VERSION "dbc-export 1 2025.20.8"

NS_ :

BS_:

BU_: APP BMS CC CMP CMPD CP DAS DI DIF DIR EPBL EPBR EVSE FC GTW HCML HCMR HVP ICR PCS PM PMF PMR PTC SCCM SCM SCS SDCR TAS UMC VC VCFRONT VCLEFT VCRIGHT VCSEC

BO_ 932 PCS_alertMatrix: 8 PCS
 SG_ PCS_matrixIndex M : 0|4@1+ (1,0) [0|15] "" Vector__XXX
 SG_ PCS_a001_chgHwInputOc m0 : 4|1@1+ (1,0) [0|1] "" Vector__XXX
 SG_ PCS_a002_chgHwOutputOc m0 : 5|1@1+ (1,0) [0|1] "" Vector__XXX
 SG_ PCS_a003_chgHwInputOv m0 : 6|1@1+ (1,0) [0|1] "" Vector__XXX
 SG_ PCS_a004_chgHwIntBusOv m0 : 7|1@1+ (1,0) [0|1] "" Vector__XXX
 SG_ PCS_a005_chgOutputOv m0 : 8|1@1+ (1,0) [0|1] "" Vector__XXX
 SG_ PCS_a006_chgPrechargeFailedScr m0 : 9|1@1+ (1,0) [0|1] "" Vector__XXX
 SG_ PCS_a007_chgPhaseTempHot m0 : 10|1@1+ (1,0) [0|1] "" Vector__XXX
 SG_ PCS_a008_chgPhaseOverTemp m0 : 11|1@1+ (1,0) [0|1] "" Vector__XXX
 SG_ PCS_a009_chgPfcCurrentRegulation m0 : 12|1@1+ (1,0) [0|1] "" Vector__XXX
 SG_ PCS_a010_chgIntBusVRegulation m0 : 13|1@1+ (1,0) [0|1] "" Vector__XXX
 SG_ PCS_a011_chgLlcCurrentRegulation m0 : 14|1@1+ (1,0) [0|1] "" Vector__XXX
 SG_ PCS_a012_chgPfcIBandTracerFault m0 : 15|1@1+ (1,0) [0|1] "" Vector__XXX
 SG_ PCS_a013_chgPrechargeFailedBoost m0 : 16|1@1+ (1,0) [0|1] "" Vector__XXX
 SG_ PCS_a014_chgTempRationality m0 : 17|1@1+ (1,0) [0|1] "" Vector__XXX
 SG_ PCS_a015_chg12vUv m0 : 18|1@1+ (1,0) [0|1] "" Vector__XXX
 SG_ PCS_a016_chgAllPhasesFaulted m0 : 19|1@1+ (1,0) [0|1] "" Vector__XXX
 SG_ PCS_a017_chgWallPowerRemoval m0 : 20|1@1+ (1,0) [0|1] "" Vector__XXX
 SG_ PCS_a018_chgUnknownGridConfig m0 : 21|1@1+ (1,0) [0|1] "" Vector__XXX
 SG_ PCS_a019_acChargePowerLimited m0 : 22|1@1+ (1,0) [0|1] "" Vector__XXX
 SG_ PCS_a020_chgEnableLineMismatch m0 : 23|1@1+ (1,0) [0|1] "" Vector__XXX
 SG_ PCS_a021_hvpMia m0 : 24|1@1+ (1,0) [0|1] "" Vector__XXX
 SG_ PCS_a022_bmsMia m0 : 25|1@1+ (1,0) [0|1] "" Vector__XXX
 SG_ PCS_a023_cpMia m0 : 26|1@1+ (1,0) [0|1] "" Vector__XXX
 SG_ PCS_a024_vcfrontMia m0 : 27|1@1+ (1,0) [0|1] "" Vector__XXX
 SG_ PCS_a025_cpu2Malfunction m0 : 28|1@1+ (1,0) [0|1] "" Vector__XXX
 SG_ PCS_a026_watchdogAlarmed m0 : 29|1@1+ (1,0) [0|1] "" Vector__XXX
 SG_ PCS_a027_chgInsufficientCooling m0 : 30|1@1+ (1,0) [0|1] "" Vector__XXX
 SG_ PCS_a028_chgOutputUv m0 : 31|1@1+ (1,0) [0|1] "" Vector__XXX
 SG_ PCS_a029_chgPowerRationality m0 : 32|1@1+ (1,0) [0|1] "" Vector__XXX
 SG_ PCS_a030_canRationality m0 : 33|1@1+ (1,0) [0|1] "" Vector__XXX
 SG_ PCS_a031_uiMia m0 : 34|1@1+ (1,0) [0|1] "" Vector__XXX
 SG_ PCS_a032_excessiveGridTransients m0 : 35|1@1+ (1,0) [0|1] "" Vector__XXX
 SG_ PCS_a033_hvBusUv m0 : 36|1@1+ (1,0) [0|1] "" Vector__XXX
 SG_ PCS_a034_hvBusOv m0 : 37|1@1+ (1,0) [0|1] "" Vector__XXX
 SG_ PCS_a035_lvBusUv m0 : 38|1@1+ (1,0) [0|1] "" Vector__XXX
 SG_ PCS_a036_lvBusOv m0 : 39|1@1+ (1,0) [0|1] "" Vector__XXX
 SG_ PCS_a037_resonantTankOc m0 : 40|1@1+ (1,0) [0|1] "" Vector__XXX
 SG_ PCS_a038_claFaulted m0 : 41|1@1+ (1,0) [0|1] "" Vector__XXX
 SG_ PCS_a039_sdModuleClkFault m0 : 42|1@1+ (1,0) [0|1] "" Vector__XXX
 SG_ PCS_a040_dcdcMaxPowerReached m0 : 43|1@1+ (1,0) [0|1] "" Vector__XXX
 SG_ PCS_a041_dcdcOverTemp m0 : 44|1@1+ (1,0) [0|1] "" Vector__XXX
 SG_ PCS_a042_dcdcEnableLineMismatch m0 : 45|1@1+ (1,0) [0|1] "" Vector__XXX
 SG_ PCS_a043_hvBusPrechargeFailure m0 : 46|1@1+ (1,0) [0|1] "" Vector__XXX
 SG_ PCS_a044_12vSupportRegulation m0 : 47|1@1+ (1,0) [0|1] "" Vector__XXX
 SG_ PCS_a045_hvBusLowImpedance m0 : 48|1@1+ (1,0) [0|1] "" Vector__XXX
 SG_ PCS_a046_hvBusHighImpedence m0 : 49|1@1+ (1,0) [0|1] "" Vector__XXX
 SG_ PCS_a047_bootloaderCrcMismatch m0 : 50|1@1+ (1,0) [0|1] "" Vector__XXX
 SG_ PCS_a048_softwareAssertion m0 : 51|1@1+ (1,0) [0|1] "" Vector__XXX
 SG_ PCS_a049_dcdcTempRationality m0 : 52|1@1+ (1,0) [0|1] "" Vector__XXX
 SG_ PCS_a050_dcdc12VsupportFaulted m0 : 53|1@1+ (1,0) [0|1] "" Vector__XXX
 SG_ PCS_a051_chgIntBusUv m0 : 54|1@1+ (1,0) [0|1] "" Vector__XXX
 SG_ PCS_a052_acVoltageNotPresent m0 : 55|1@1+ (1,0) [0|1] "" Vector__XXX
 SG_ PCS_a053_chgInputVDropHigh m0 : 56|1@1+ (1,0) [0|1] "" Vector__XXX
 SG_ PCS_a054_chgInputVDropTooHigh m0 : 57|1@1+ (1,0) [0|1] "" Vector__XXX
 SG_ PCS_a055_chgLineImpedanceHigh m0 : 58|1@1+ (1,0) [0|1] "" Vector__XXX
 SG_ PCS_a056_chgLineImpedanceTooHigh m0 : 59|1@1+ (1,0) [0|1] "" Vector__XXX
 SG_ PCS_a057_chgInputOverFreq m0 : 60|1@1+ (1,0) [0|1] "" Vector__XXX
 SG_ PCS_a058_chgInputUnderFreq m0 : 61|1@1+ (1,0) [0|1] "" Vector__XXX
 SG_ PCS_a059_chgInputOvRms m0 : 62|1@1+ (1,0) [0|1] "" Vector__XXX
 SG_ PCS_a060_chgInputOvPeak m0 : 63|1@1+ (1,0) [0|1] "" Vector__XXX
 SG_ PCS_a061_chgVLineRationality m1 : 4|1@1+ (1,0) [0|1] "" Vector__XXX
 SG_ PCS_a062_chgILineRationality m1 : 5|1@1+ (1,0) [0|1] "" Vector__XXX
 SG_ PCS_a063_chgVOutRationality m1 : 6|1@1+ (1,0) [0|1] "" Vector__XXX
 SG_ PCS_a064_chgIOutRationality m1 : 7|1@1+ (1,0) [0|1] "" Vector__XXX
 SG_ PCS_a065_chgPllNotLocked m1 : 8|1@1+ (1,0) [0|1] "" Vector__XXX
 SG_ PCS_a066_dcdcHvRationality m1 : 9|1@1+ (1,0) [0|1] "" Vector__XXX
 SG_ PCS_a067_dcdcLvRationality m1 : 10|1@1+ (1,0) [0|1] "" Vector__XXX
 SG_ PCS_a068_dcdcTankvRationality m1 : 11|1@1+ (1,0) [0|1] "" Vector__XXX
 SG_ PCS_a069_chgPfcLineDidt m1 : 12|1@1+ (1,0) [0|1] "" Vector__XXX
 SG_ PCS_a070_chgPfcLineDvdt m1 : 13|1@1+ (1,0) [0|1] "" Vector__XXX
 SG_ PCS_a071_chgPfcILoopRationality m1 : 14|1@1+ (1,0) [0|1] "" Vector__XXX
 SG_ PCS_a072_cpu2ClaStopped m1 : 15|1@1+ (1,0) [0|1] "" Vector__XXX
 SG_ PCS_a073_unexpectedAcInputVoltag m1 : 16|1@1+ (1,0) [0|1] "" Vector__XXX
 SG_ PCS_a074_hvBusDischargeFailure m1 : 17|1@1+ (1,0) [0|1] "" Vector__XXX
 SG_ PCS_a075_hvBusDischargeTimeout m1 : 18|1@1+ (1,0) [0|1] "" Vector__XXX
 SG_ PCS_a076_dcdcEnDeassertedErr m1 : 19|1@1+ (1,0) [0|1] "" Vector__XXX
 SG_ PCS_a077_microGridWobbleDetected m1 : 20|1@1+ (1,0) [0|1] "" Vector__XXX
 SG_ PCS_a078_chgStopDcdcTooHot m1 : 21|1@1+ (1,0) [0|1] "" Vector__XXX
 SG_ PCS_a079_eepromOperationError m1 : 22|1@1+ (1,0) [0|1] "" Vector__XXX
 SG_ PCS_a080_damagedPhaseDetected m1 : 23|1@1+ (1,0) [0|1] "" Vector__XXX
 SG_ PCS_a081_dcdcPchgTimeout m1 : 24|1@1+ (1,0) [0|1] "" Vector__XXX
 SG_ PCS_a082_dcdcPchgUnsafeDiVoltage m1 : 25|1@1+ (1,0) [0|1] "" Vector__XXX
 SG_ PCS_a083_triggerOdin m1 : 26|1@1+ (1,0) [0|1] "" Vector__XXX
 SG_ PCS_a084_vDropFastInParasiticDio m1 : 27|1@1+ (1,0) [0|1] "" Vector__XXX
 SG_ PCS_a085_dcdcFetsNotSwitching m1 : 28|1@1+ (1,0) [0|1] "" Vector__XXX
 SG_ PCS_a086_dcdcInsufficientCooling m1 : 29|1@1+ (1,0) [0|1] "" Vector__XXX
 SG_ PCS_a087_nvramRecordStatusError m1 : 30|1@1+ (1,0) [0|1] "" Vector__XXX
 SG_ PCS_a088_gridFreqDroopDetected m1 : 31|1@1+ (1,0) [0|1] "" Vector__XXX
 SG_ PCS_a089_hvBusDischargeIrrationa m1 : 32|1@1+ (1,0) [0|1] "" Vector__XXX
 SG_ PCS_a090_expectedAcVoltageSource m1 : 33|1@1+ (1,0) [0|1] "" Vector__XXX
 SG_ PCS_a091_chgIntBusRationality m1 : 34|1@1+ (1,0) [0|1] "" Vector__XXX
 SG_ PCS_a092_chgPowerLimitedByBusRip m1 : 35|1@1+ (1,0) [0|1] "" Vector__XXX
 SG_ PCS_a093_powerRailRationality m1 : 36|1@1+ (1,0) [0|1] "" Vector__XXX
 SG_ PCS_a094_pcsDcdcNeedService m1 : 37|1@1+ (1,0) [0|1] "" Vector__XXX
 SG_ PCS_a095_dcdcSensorlessModeActiv m1 : 38|1@1+ (1,0) [0|1] "" Vector__XXX
 SG_ PCS_a096_microGridOverLoaded m1 : 39|1@1+ (1,0) [0|1] "" Vector__XXX
 SG_ PCS_a097_rebootPhaseDetected m1 : 40|1@1+ (1,0) [0|1] "" Vector__XXX
 SG_ PCS_a098_gridFreqDroopDetectedSi m1 : 41|1@1+ (1,0) [0|1] "" Vector__XXX
 SG_ PCS_a099_microGridOverLoadedSile m1 : 42|1@1+ (1,0) [0|1] "" Vector__XXX
 SG_ PCS_a100_suspectedViperChipIssue m1 : 43|1@1+ (1,0) [0|1] "" Vector__XXX
 SG_ PCS_a101_phMachineModelIrrationa m1 : 44|1@1+ (1,0) [0|1] "" Vector__XXX
 SG_ PCS_a102_resetWithDCDCCmdAsserte m1 : 45|1@1+ (1,0) [0|1] "" Vector__XXX
 SG_ PCS_a103_pchgWithLowLvDetected m1 : 46|1@1+ (1,0) [0|1] "" Vector__XXX
 SG_ PCS_a104_ambientTempRationality m1 : 47|1@1+ (1,0) [0|1] "" Vector__XXX
 SG_ PCS_a105_redundantVoltageSourceI m1 : 48|1@1+ (1,0) [0|1] "" Vector__XXX
 SG_ PCS_a106_clockSourceNotFromExter m1 : 49|1@1+ (1,0) [0|1] "" Vector__XXX
 SG_ PCS_a107_vcPcsDCDCInterfaceMia m1 : 50|1@1+ (1,0) [0|1] "" Vector__XXX
 SG_ PCS_a108_misconfigurationDetecte m1 : 51|1@1+ (1,0) [0|1] "" Vector__XXX
 SG_ PCS_a109_deltaChargingL2L3Swappe m1 : 52|1@1+ (1,0) [0|1] "" Vector__XXX

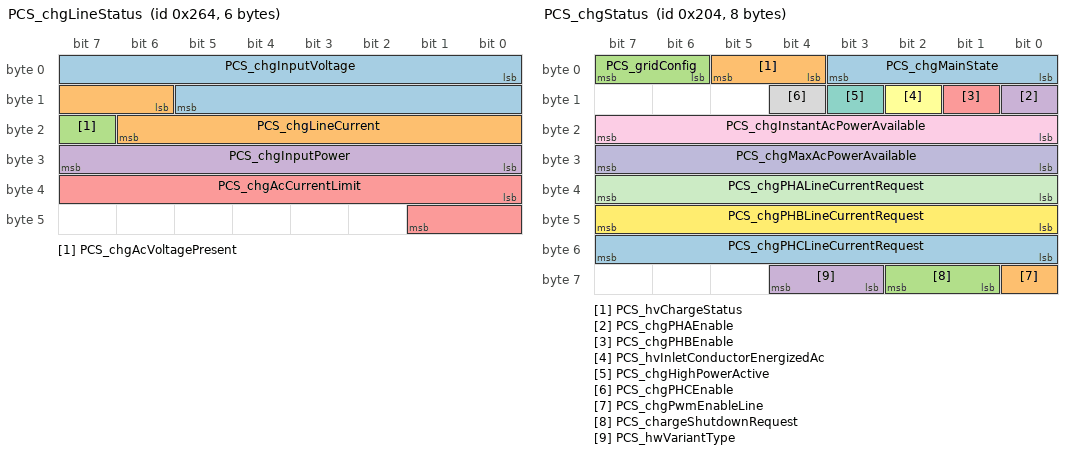
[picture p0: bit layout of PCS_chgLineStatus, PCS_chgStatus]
BO_ 612 PCS_chgLineStatus: 6 PCS
 SG_ PCS_chgInputVoltage : 0|14@1+ (0.033,0) [0|540.639] "V" Vector__XXX
 SG_ PCS_chgLineCurrent : 14|9@1+ (0.1,0) [0|50] "A" Vector__XXX
 SG_ PCS_chgAcVoltagePresent : 23|1@1+ (1,0) [0|1] "" Vector__XXX
 SG_ PCS_chgInputPower : 24|8@1+ (0.1,0) [0|20] "kW" Vector__XXX
 SG_ PCS_chgAcCurrentLimit : 32|10@1+ (0.1,0) [0|102.3] "A" Vector__XXX

BO_ 516 PCS_chgStatus: 8 PCS
 SG_ PCS_chgMainState : 0|4@1+ (1,0) [0|15] "" Vector__XXX
 SG_ PCS_hvChargeStatus : 4|2@1+ (1,0) [0|3] "" Vector__XXX
 SG_ PCS_gridConfig : 6|2@1+ (1,0) [1|3] "" Vector__XXX
 SG_ PCS_chgPHAEnable : 8|1@1+ (1,0) [0|1] "" Vector__XXX
 SG_ PCS_chgPHBEnable : 9|1@1+ (1,0) [0|1] "" Vector__XXX
 SG_ PCS_hvInletConductorEnergizedAc : 10|1@1+ (1,0) [0|1] "" Vector__XXX
 SG_ PCS_chgHighPowerActive : 11|1@1+ (1,0) [0|1] "" Vector__XXX
 SG_ PCS_chgPHCEnable : 12|1@1+ (1,0) [0|1] "" Vector__XXX
 SG_ PCS_chgInstantAcPowerAvailable : 16|8@1+ (0.1,0) [0|20] "kW" Vector__XXX
 SG_ PCS_chgMaxAcPowerAvailable : 24|8@1+ (0.1,0) [0|20] "kW" Vector__XXX
 SG_ PCS_chgPHALineCurrentRequest : 32|8@1+ (0.1,0) [0|20] "A" Vector__XXX
 SG_ PCS_chgPHBLineCurrentRequest : 40|8@1+ (0.1,0) [0|20] "A" Vector__XXX
 SG_ PCS_chgPHCLineCurrentRequest : 48|8@1+ (0.1,0) [0|20] "A" Vector__XXX
 SG_ PCS_chgPwmEnableLine : 56|1@1+ (1,0) [0|1] "" Vector__XXX
 SG_ PCS_chargeShutdownRequest : 57|2@1+ (1,0) [0|3] "" Vector__XXX
 SG_ PCS_hwVariantType : 59|2@1+ (1,0) [0|2] "" Vector__XXX

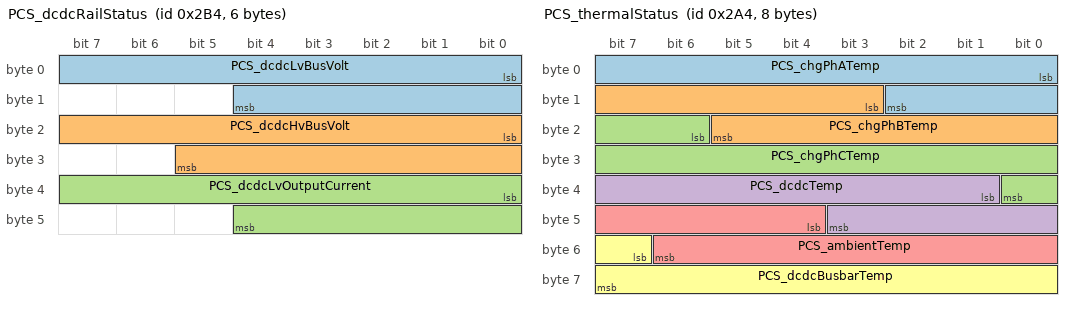
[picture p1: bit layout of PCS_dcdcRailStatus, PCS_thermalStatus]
BO_ 692 PCS_dcdcRailStatus: 6 PCS
 SG_ PCS_dcdcLvBusVolt : 0|13@1+ (0.01,0) [0|80] "V" Vector__XXX
 SG_ PCS_dcdcHvBusVolt : 16|14@1+ (0.1,0) [0|1600] "V" Vector__XXX
 SG_ PCS_dcdcLvOutputCurrent : 32|13@1- (0.1,0) [-400|400] "A" Vector__XXX

BO_ 548 PCS_dcdcStatus: 8 PCS
 SG_ PCS_dcdcPrechargeStatus : 0|2@1+ (1,0) [0|3] "" Vector__XXX
 SG_ PCS_dcdcLvSupportStatus : 2|2@1+ (1,0) [0|3] "" Vector__XXX
 SG_ PCS_dcdcHvBusDischargeStatus : 4|2@1+ (1,0) [0|3] "" Vector__XXX
 SG_ PCS_coldSleepAllowed : 8|1@1+ (1,0) [0|1] "" Vector__XXX
 SG_ PCS_dcdcPchgHVBusLowRDetected : 9|1@1+ (1,0) [0|1] "" Vector__XXX
 SG_ PCS_dcdcSubState : 10|5@1+ (1,0) [0|31] "" Vector__XXX
 SG_ PCS_dcdcFaulted : 15|1@1+ (1,0) [0|1] "" Vector__XXX
 SG_ PCS_okToBePowerCycled : 27|1@1+ (1,0) [0|1] "" Vector__XXX
 SG_ PCS_dcdcOutputIsLimited : 28|1@1+ (1,0) [0|1] "" Vector__XXX
 SG_ PCS_dcdcMaxOutputCurrentAllowed : 29|12@1+ (0.1,0) [0|400] "A" Vector__XXX
 SG_ PCS_dcdcPrechargeRtyCnt : 41|3@1+ (1,0) [0|7] "" Vector__XXX
 SG_ PCS_dcdcLvSupportRtyCnt : 44|4@1+ (1,0) [0|15] "" Vector__XXX
 SG_ PCS_dcdcDischargeRtyCnt : 48|4@1+ (1,0) [0|15] "" Vector__XXX
 SG_ PCS_dcdcPwmEnableLine : 52|1@1+ (1,0) [0|1] "" Vector__XXX
 SG_ PCS_dcdcSupportingFixedLvTarget : 53|1@1+ (1,0) [0|1] "" Vector__XXX
 SG_ PCS_ecuLogUploadRequest : 54|2@1+ (1,0) [0|3] "" Vector__XXX
 SG_ PCS_dcdcPrechargeRestartCnt : 56|3@1+ (1,0) [0|7] "" Vector__XXX
 SG_ PCS_dcdcInitialPrechargeSubState : 59|5@1+ (1,0) [0|31] "" Vector__XXX

BO_ 964 PCS_info: 8 PCS
 SG_ PCS_infoIndex M : 0|8@1+ (1,0) [0|255] "" Vector__XXX
 SG_ PCS_buildType m10 : 8|8@1+ (1,0) [0|255] "" Vector__XXX
 SG_ PCS_buildConfigId m10 : 16|16@1+ (1,0) [0|65535] "" Vector__XXX
 SG_ PCS_hardwareId m10 : 32|16@1+ (1,0) [0|65535] "" Vector__XXX
 SG_ PCS_componentId m10 : 48|16@1+ (1,0) [0|65535] "" Vector__XXX
 SG_ PCS_pcbaId m11 : 16|8@1+ (1,0) [0|255] "" Vector__XXX
 SG_ PCS_assemblyId m11 : 24|8@1+ (1,0) [0|255] "" Vector__XXX
 SG_ PCS_usageId m11 : 32|16@1+ (1,0) [0|65535] "" Vector__XXX
 SG_ PCS_subUsageId m11 : 48|16@1+ (1,0) [0|65535] "" Vector__XXX
 SG_ PCS_platformType m13 : 8|8@1+ (1,0) [0|255] "" Vector__XXX
 SG_ PCS_appCrc m13 : 32|32@1+ (1,0) [0|4294967295] "" Vector__XXX
 SG_ PCS_cpu2AppCrc m16 : 32|32@1+ (1,0) [0|4294967295] "" Vector__XXX
 SG_ PCS_appGitHash m17 : 8|56@1+ (1,0) [0|7.20575940379e+16] "" Vector__XXX
 SG_ PCS_bootGitHash m18 : 8|56@1+ (1,0) [0|7.20575940379e+16] "" Vector__XXX
 SG_ PCS_bootUdsProtoVersion m20 : 8|8@1+ (1,0) [0|255] "" Vector__XXX
 SG_ PCS_bootCrc m20 : 32|32@1+ (1,0) [0|4294967295] "" Vector__XXX

BO_ 708 PCS_logging: 8 PCS
 SG_ PCS_logMessageSelect M : 0|5@1+ (1,0) [0|31] "" Vector__XXX
 SG_ PCS_chgPhAInputIrms m0 : 5|9@1+ (0.1,0) [0|51.1] "A" Vector__XXX
 SG_ PCS_chgPhAIntBusV m0 : 14|9@1+ (1,0) [0|511] "V" Vector__XXX
 SG_ PCS_chgPhAIntBusVTarget m0 : 23|9@1+ (1,0) [0|511] "V" Vector__XXX
 SG_ PCS_chgPhAOutputI m0 : 32|8@1+ (0.1,0) [0|25.5] "A" Vector__XXX
 SG_ PCS_chgPhAInputCurrentLimitReaso m0 : 40|3@1+ (1,0) [0|7] "" Vector__XXX
 SG_ PCS_chgPhBInputIrms m1 : 5|9@1+ (0.1,0) [0|51.1] "A" Vector__XXX
 SG_ PCS_chgPhBIntBusV m1 : 14|9@1+ (1,0) [0|511] "V" Vector__XXX
 SG_ PCS_chgPhBIntBusVTarget m1 : 23|9@1+ (1,0) [0|511] "V" Vector__XXX
 SG_ PCS_chgPhBOutputI m1 : 32|8@1+ (0.1,0) [0|25.5] "A" Vector__XXX
 SG_ PCS_chgPhBInputCurrentLimitReaso m1 : 40|3@1+ (1,0) [0|7] "" Vector__XXX
 SG_ PCS_chgPhCInputIrms m2 : 5|9@1+ (0.1,0) [0|51.1] "A" Vector__XXX
 SG_ PCS_chgPhCIntBusV m2 : 14|9@1+ (1,0) [0|511] "V" Vector__XXX
 SG_ PCS_chgPhCIntBusVTarget m2 : 23|9@1+ (1,0) [0|511] "V" Vector__XXX
 SG_ PCS_chgPhCOutputI m2 : 32|8@1+ (0.1,0) [0|25.5] "A" Vector__XXX
 SG_ PCS_chgPhCInputCurrentLimitReaso m2 : 40|3@1+ (1,0) [0|7] "" Vector__XXX
 SG_ PCS_chgInputL1NVrms m3 : 5|12@1+ (0.2,0) [0|819] "V" Vector__XXX
 SG_ PCS_chgInputL2NVrms m3 : 17|12@1+ (0.2,0) [0|819] "V" Vector__XXX
 SG_ PCS_chgInputL3NVrms m3 : 29|12@1+ (0.2,0) [0|819] "V" Vector__XXX
 SG_ PCS_chgInputL1L2Vrms m3 : 41|12@1+ (0.2,0) [0|819] "V" Vector__XXX
 SG_ PCS_chgInputNGVrms m3 : 53|9@1+ (1,0) [0|511] "V" Vector__XXX
 SG_ PCS_chgInputFrequencyL1N m4 : 5|12@1+ (0.01,40) [40|80.95] "Hz" Vector__XXX
 SG_ PCS_chgInputFrequencyL2N m4 : 17|12@1+ (0.01,40) [40|80.95] "Hz" Vector__XXX
 SG_ PCS_chgInputFrequencyL3N m4 : 29|12@1+ (0.01,40) [40|80.95] "Hz" Vector__XXX
 SG_ PCS_chgInternalPhaseConfig m4 : 41|4@1+ (1,0) [1|15] "" Vector__XXX
 SG_ PCS_chgPhasesPriority m4 : 45|6@1+ (1,0) [0|63] "" Vector__XXX
 SG_ PCS_chgOutputV m4 : 51|12@1+ (0.146484375,0) [0|599.853515625] "V" Vector__XXX
 SG_ PCS_chgPhAState m5 : 5|4@1+ (1,0) [0|15] "" Vector__XXX
 SG_ PCS_chgPhBState m5 : 9|4@1+ (1,0) [0|15] "" Vector__XXX
 SG_ PCS_chgPhCState m5 : 13|4@1+ (1,0) [0|15] "" Vector__XXX
 SG_ PCS_chgPhALastShutdownReason m5 : 17|5@1+ (1,0) [0|31] "" Vector__XXX
 SG_ PCS_chgPhBLastShutdownReason m5 : 22|5@1+ (1,0) [0|31] "" Vector__XXX
 SG_ PCS_chgPhCLastShutdownReason m5 : 27|5@1+ (1,0) [0|31] "" Vector__XXX
 SG_ PCS_chgPhARetryCount m5 : 32|3@1+ (1,0) [0|7] "" Vector__XXX
 SG_ PCS_chgPhBRetryCount m5 : 35|3@1+ (1,0) [0|7] "" Vector__XXX
 SG_ PCS_chgPhCRetryCount m5 : 38|3@1+ (1,0) [0|7] "" Vector__XXX
 SG_ PCS_chgRetryCount m5 : 41|3@1+ (1,0) [0|7] "" Vector__XXX
 SG_ PCS_chgPhManCurrentToDist m5 : 44|10@1+ (0.1,0) [0|100] "A" Vector__XXX
 SG_ PCS_chgL1NPllLocked m5 : 54|1@1+ (1,0) [0|1] "" Vector__XXX
 SG_ PCS_chgL2NPllLocked m5 : 55|1@1+ (1,0) [0|1] "" Vector__XXX
 SG_ PCS_chgL3NPllLocked m5 : 56|1@1+ (1,0) [0|1] "" Vector__XXX
 SG_ PCS_chgL1L2PllLocked m5 : 57|1@1+ (1,0) [0|1] "" Vector__XXX
 SG_ PCS_chgNgPllLocked m5 : 58|1@1+ (1,0) [0|1] "" Vector__XXX
 SG_ PCS_chgPhManOptimalPhsToUse m5 : 59|2@1+ (1,0) [0|3] "" Vector__XXX
 SG_ PCS_chg5VL1Enable m5 : 61|1@1+ (1,0) [0|1] "" Vector__XXX
 SG_ PCS_dcdcMaxLvOutputCurrent m6 : 8|12@1+ (0.1,0) [0|400] "A" Vector__XXX
 SG_ PCS_dcdcCurrentLimit m6 : 20|12@1+ (0.1,0) [0|400] "A" Vector__XXX
 SG_ PCS_dcdcLvOutputCurrentTempLimit m6 : 32|12@1+ (0.1,0) [0|400] "A" Vector__XXX
 SG_ PCS_dcdcLvOutputCurrentFiltered m6 : 44|12@1+ (0.1,0) [0|400] "A" Vector__XXX
 SG_ PCS_dcdcUnifiedCommand m7 : 5|10@1+ (0.001,0) [0|1] "1" Vector__XXX
 SG_ PCS_dcdcCLAControllerOutput m7 : 16|10@1+ (0.001,0) [0|1] "1" Vector__XXX
 SG_ PCS_dcdcTankVoltage m7 : 26|11@1- (1,0) [-1024|1023] "V" Vector__XXX
 SG_ PCS_dcdcTankVoltageTarget m7 : 37|10@1+ (1,0) [0|1023] "V" Vector__XXX
 SG_ PCS_dcdcClaCurrentFreq m7 : 48|12@1+ (0.09765625,0) [0|399.9] "kHz" Vector__XXX
 SG_ PCS_dcdcTCommMeasured m8 : 5|16@1- (0.001953125,0) [-64|63.998] "us" Vector__XXX
 SG_ PCS_dcdcShortTimeUs m8 : 21|16@1+ (0.00048828125,0) [0|31.9995] "us" Vector__XXX
 SG_ PCS_dcdcHalfPeriodUs m8 : 37|16@1+ (0.00048828125,0) [0|31.9995] "us" Vector__XXX
 SG_ PCS_dcdcLvBusVoltTargetWithOffse m8 : 53|11@1+ (0.01,0) [0|20] "V" Vector__XXX
 SG_ PCS_cpu2BootState m9 : 5|2@1+ (1,0) [0|3] "" Vector__XXX
 SG_ PCS_acChargeSelfTestState m9 : 7|1@1+ (1,0) [0|1] "" Vector__XXX
 SG_ PCS_1V5Min10s m9 : 8|11@1+ (0.001,0) [0|2.047] "V" Vector__XXX
 SG_ PCS_1V5Max10s m9 : 19|11@1+ (0.001,0) [0|2.047] "V" Vector__XXX
 SG_ PCS_1V2Min10s m9 : 32|11@1+ (0.001,0) [0|2.047] "V" Vector__XXX
 SG_ PCS_1V2Max10s m9 : 43|11@1+ (0.001,0) [0|2.047] "V" Vector__XXX
 SG_ PCS_5VNMax10s m9 : 54|10@1+ (0.01,0) [0|10.23] "V" Vector__XXX
 SG_ PCS_chgPhAIntBusVMin10s m10 : 5|9@1+ (1,0) [0|511] "V" Vector__XXX
 SG_ PCS_chgPhAIntBusVMax10s m10 : 14|9@1+ (1,0) [0|511] "V" Vector__XXX
 SG_ PCS_chgPhAPchgVoltDeltaMax10s m10 : 23|8@1+ (0.5,0) [0|127.5] "V" Vector__XXX
 SG_ PCS_chgPhALifetimekWh m10 : 31|24@1+ (0.01,0) [0|167772.15] "kWh" Vector__XXX
 SG_ PCS_chgPhATransientRetryCount m10 : 55|9@1+ (0.1,0) [0|51.1] "-" Vector__XXX
 SG_ PCS_chgPhBIntBusVMin10s m11 : 5|9@1+ (1,0) [0|511] "V" Vector__XXX
 SG_ PCS_chgPhBIntBusVMax10s m11 : 14|9@1+ (1,0) [0|511] "V" Vector__XXX
 SG_ PCS_chgPhBPchgVoltDeltaMax10s m11 : 23|8@1+ (0.5,0) [0|127.5] "V" Vector__XXX
 SG_ PCS_chgPhBLifetimekWh m11 : 31|24@1+ (0.01,0) [0|167772.15] "kWh" Vector__XXX
 SG_ PCS_chgPhBTransientRetryCount m11 : 55|9@1+ (0.1,0) [0|51.1] "-" Vector__XXX
 SG_ PCS_chgPhCIntBusVMin10s m12 : 5|9@1+ (1,0) [0|511] "V" Vector__XXX
 SG_ PCS_chgPhCIntBusVMax10s m12 : 14|9@1+ (1,0) [0|511] "V" Vector__XXX
 SG_ PCS_chgPhCPchgVoltDeltaMax10s m12 : 23|8@1+ (0.5,0) [0|127.5] "V" Vector__XXX
 SG_ PCS_chgPhCLifetimekWh m12 : 31|24@1+ (0.01,0) [0|167772.15] "kWh" Vector__XXX
 SG_ PCS_chgPhCTransientRetryCount m12 : 55|9@1+ (0.1,0) [0|51.1] "-" Vector__XXX
 SG_ PCS_chgPhANoFlowBucket m20 : 5|9@1+ (0.01,0) [0|5.11] "-" Vector__XXX
 SG_ PCS_chgPhBNoFlowBucket m20 : 14|9@1+ (0.01,0) [0|5.11] "-" Vector__XXX
 SG_ PCS_chgPhCNoFlowBucket m20 : 23|9@1+ (0.01,0) [0|5.11] "-" Vector__XXX
 SG_ PCS_chgCurrentSensorOutOfBandUs m20 : 32|10@1+ (0.01,0) [0|10.23] "us" Vector__XXX
 SG_ PCS_chgAcpwHeartbeatState m20 : 42|3@1+ (1,0) [0|7] "" Vector__XXX
 SG_ PCS_chgKwhLostByFreqDroop m20 : 48|8@1+ (0.1,0) [0|25.5] "kWh" Vector__XXX
 SG_ PCS_chgReqKwhLostByFreqDroop m20 : 56|8@1+ (0.1,0) [0|25.5] "kWh" Vector__XXX
 SG_ PCS_dcdcLvSupportLifetimekWh m22 : 8|24@1+ (0.01,0) [0|167772.15] "kWh" Vector__XXX
 SG_ PCS_chgPwmEnableLineErrorCount m22 : 32|10@1+ (1,0) [0|1023] "" Vector__XXX
 SG_ PCS_dcdcPwmEnableLineErrorCount m22 : 42|10@1+ (1,0) [0|1023] "" Vector__XXX
 SG_ PCS_numAlertsSet m22 : 56|7@1+ (1,0) [0|127] "" Vector__XXX
 SG_ PCS_dcdcPchgStartLvBusVolt m24 : 5|10@1+ (0.0390625,0) [0|39.9609375] "V" Vector__XXX
 SG_ PCS_dcdcPchgStartHvBusVolt m24 : 16|12@1+ (0.146484375,0) [0|599.853515625] "V" Vector__XXX
 SG_ PCS_processorDieIdLot m26 : 8|24@1+ (1,0) [0|16777215] "" Vector__XXX
 SG_ PCS_processorDieIdWafer m26 : 32|8@1+ (1,0) [0|255] "" Vector__XXX
 SG_ PCS_processorDieIdX m26 : 40|12@1+ (1,0) [0|4095] "" Vector__XXX
 SG_ PCS_processorDieIdY m26 : 52|12@1+ (1,0) [0|4095] "" Vector__XXX

BO_ 676 PCS_thermalStatus: 8 PCS
 SG_ PCS_chgPhATemp : 0|11@1- (0.1,40) [-62.4|142.3] "C" Vector__XXX
 SG_ PCS_chgPhBTemp : 11|11@1- (0.1,40) [-62.4|142.3] "C" Vector__XXX
 SG_ PCS_chgPhCTemp : 22|11@1- (0.1,40) [-62.4|142.3] "C" Vector__XXX
 SG_ PCS_dcdcTemp : 33|11@1- (0.1,40) [-62.4|142.3] "C" Vector__XXX
 SG_ PCS_ambientTemp : 44|11@1- (0.1,40) [-62.4|142.3] "C" Vector__XXX
 SG_ PCS_dcdcBusbarTemp : 55|9@1+ (0.2935421,0) [0|149.706471] "C" Vector__XXX

BO_ 1317 PMF_alertLog: 8 PMF
 SG_ PMF_alertID M : 0|7@1+ (1,0) [0|127] "" Vector__XXX
 SG_ PMF_alertState : 15|1@1+ (1,0) [0|1] "" Vector__XXX
 SG_ PMF_a001_w0 m1 : 16|16@1+ (1,0) [0|65535] "" Vector__XXX
 SG_ PMF_a001_w1 m1 : 32|16@1+ (1,0) [0|65535] "" Vector__XXX
 SG_ PMF_a001_w2 m1 : 48|16@1+ (1,0) [0|65535] "" Vector__XXX
 SG_ PMF_a002_torqueAverage m2 : 16|1@1+ (1,0) [0|1] "" Vector__XXX
 SG_ PMF_a002_torqueWindow m2 : 17|1@1+ (1,0) [0|1] "" Vector__XXX
 SG_ PMF_a002_torqueMeasured m2 : 18|13@1- (2,0) [-8192|8190] "Nm" Vector__XXX
 SG_ PMF_a002_torqueAccelAverage m2 : 32|13@1- (2,0) [-8192|8190] "Nm" Vector__XXX
 SG_ PMF_a002_torqueAccelWindow m2 : 48|13@1- (2,0) [-8192|8190] "Nm" Vector__XXX
 SG_ PMF_a003_reverseGear m3 : 16|1@1+ (1,0) [0|1] "" Vector__XXX
 SG_ PMF_a003_pedalPos m3 : 24|8@1+ (0.4,0) [0|102] "%" Vector__XXX
 SG_ PMF_a003_zeroPointPedal m3 : 32|8@1+ (0.4,0) [0|102] "%" Vector__XXX
 SG_ PMF_a004_torqueAverage m4 : 16|1@1+ (1,0) [0|1] "" Vector__XXX
 SG_ PMF_a004_torqueWindow m4 : 17|1@1+ (1,0) [0|1] "" Vector__XXX
 SG_ PMF_a004_torqueMeasured m4 : 18|13@1- (2,0) [-8192|8190] "Nm" Vector__XXX
 SG_ PMF_a004_torqueDecelAverage m4 : 32|13@1- (2,0) [-8192|8190] "Nm" Vector__XXX
 SG_ PMF_a004_torqueDecelWindow m4 : 48|13@1- (2,0) [-8192|8190] "Nm" Vector__XXX
 SG_ PMF_a005_torqueReason m5 : 16|2@1+ (1,0) [0|3] "" Vector__XXX
 SG_ PMF_a005_torqueMeasured m5 : 18|13@1- (2,0) [-8192|8190] "Nm" Vector__XXX
 SG_ PMF_a005_iDQmagnitude m5 : 32|16@1- (0.0939,0) [-3076.9152|3076.8213] "A" Vector__XXX
 SG_ PMF_a006_torqueActual m6 : 16|13@1- (2,0) [-8192|8190] "Nm" Vector__XXX
 SG_ PMF_a006_motorRPM m6 : 32|16@1- (1,0) [-32768|32767] "RPM" Vector__XXX
 SG_ PMF_a006_torqueMeasured m6 : 48|13@1- (2,0) [-8192|8190] "Nm" Vector__XXX
 SG_ PMF_a010_messageId m10 : 16|16@1+ (1,0) [0|65535] "" Vector__XXX
 SG_ PMF_a010_DI_status m10 : 32|1@1+ (1,0) [0|1] "" Vector__XXX
 SG_ PMF_a010_DI_torque m10 : 33|1@1+ (1,0) [0|1] "" Vector__XXX
 SG_ PMF_a010_DI_slaveCommand m10 : 34|1@1+ (1,0) [0|1] "" Vector__XXX
 SG_ PMF_a010_DI_locStatus m10 : 35|1@1+ (1,0) [0|1] "" Vector__XXX
 SG_ PMF_a010_DI_speed m10 : 36|1@1+ (1,0) [0|1] "" Vector__XXX
 SG_ PMF_a010_DI_systemStatus m10 : 37|1@1+ (1,0) [0|1] "" Vector__XXX
 SG_ PMF_a010_DI_chassisControl m10 : 38|1@1+ (1,0) [0|1] "" Vector__XXX
 SG_ PMF_a010_DI_chassisControl2 m10 : 39|1@1+ (1,0) [0|1] "" Vector__XXX
 SG_ PMF_a010_vdcLeft m10 : 40|1@1+ (1,0) [0|1] "" Vector__XXX
 SG_ PMF_a010_vdcRight m10 : 41|1@1+ (1,0) [0|1] "" Vector__XXX
 SG_ PMF_a010_DI_vehicleEstimates m10 : 42|1@1+ (1,0) [0|1] "" Vector__XXX
 SG_ PMF_a010_DI_brakeCommand m10 : 43|1@1+ (1,0) [0|1] "" Vector__XXX
 SG_ PMF_a010_DI_difCommand m10 : 44|1@1+ (1,0) [0|1] "" Vector__XXX
 SG_ PMF_a010_DI_dirCommand m10 : 45|1@1+ (1,0) [0|1] "" Vector__XXX
 SG_ PMF_a010_DI_dirVehicle m10 : 46|1@1+ (1,0) [0|1] "" Vector__XXX
 SG_ PMF_a010_DI_locStatus2 m10 : 47|1@1+ (1,0) [0|1] "" Vector__XXX
 SG_ PMF_a011_Ia m11 : 16|16@1- (0.0939,0) [-3076.9152|3076.8213] "A" Vector__XXX
 SG_ PMF_a011_Ib m11 : 32|16@1- (0.0939,0) [-3076.9152|3076.8213] "A" Vector__XXX
 SG_ PMF_a011_currentVref m11 : 48|11@1+ (0.005,0) [0|10.235] "V" Vector__XXX
 SG_ PMF_a011_badPhaseAsample m11 : 59|1@1+ (1,0) [0|1] "" Vector__XXX
 SG_ PMF_a011_badPhaseBsample m11 : 60|1@1+ (1,0) [0|1] "" Vector__XXX
 SG_ PMF_a011_sampleFreeze m11 : 61|1@1+ (1,0) [0|1] "" Vector__XXX
 SG_ PMF_a012_canID m12 : 16|12@1+ (1,0) [0|4095] "" Vector__XXX
 SG_ PMF_a012_errorType m12 : 28|3@1+ (1,0) [0|7] "" Vector__XXX
 SG_ PMF_a012_badValue1 m12 : 32|16@1+ (1,0) [0|65535] "" Vector__XXX
 SG_ PMF_a012_badValue2 m12 : 48|16@1+ (1,0) [0|65535] "" Vector__XXX
 SG_ PMF_a013_mailboxID m13 : 16|16@1+ (1,0) [0|65535] "" Vector__XXX
 SG_ PMF_a013_canID m13 : 32|16@1+ (1,0) [0|65535] "" Vector__XXX
 SG_ PMF_a013_errorType m13 : 48|3@1+ (1,0) [0|7] "" Vector__XXX
 SG_ PMF_a017_EPBL_status m17 : 16|1@1+ (1,0) [0|1] "" Vector__XXX
 SG_ PMF_a017_EPBR_status m17 : 17|1@1+ (1,0) [0|1] "" Vector__XXX
 SG_ PMF_a018_w0 m18 : 16|16@1+ (1,0) [0|65535] "" Vector__XXX
 SG_ PMF_a018_w1 m18 : 32|16@1+ (1,0) [0|65535] "" Vector__XXX
 SG_ PMF_a018_w2 m18 : 48|16@1+ (1,0) [0|65535] "" Vector__XXX
 SG_ PMF_a019_statorTemp1 m19 : 16|16@1- (0.1,0) [-3276.8|3276.7] "DegC" Vector__XXX
 SG_ PMF_a019_statorTslope1 m19 : 32|16@1- (0.1,0) [-3276.8|3276.7] "DegC/s" Vector__XXX
 SG_ PMF_a025_sccReset m25 : 16|1@1+ (1,0) [0|1] "" Vector__XXX
 SG_ PMF_a025_hibernate m25 : 17|1@1+ (1,0) [0|1] "" Vector__XXX
 SG_ PMF_a025_hwBist m25 : 18|1@1+ (1,0) [0|1] "" Vector__XXX
 SG_ PMF_a025_nmiWatchdog m25 : 19|1@1+ (1,0) [0|1] "" Vector__XXX
 SG_ PMF_a025_watchdog m25 : 20|1@1+ (1,0) [0|1] "" Vector__XXX
 SG_ PMF_a025_clockFailNmi m25 : 21|1@1+ (1,0) [0|1] "" Vector__XXX
 SG_ PMF_a025_ramUncErrorNmi m25 : 22|1@1+ (1,0) [0|1] "" Vector__XXX
 SG_ PMF_a025_flashUncErrorNmi m25 : 23|1@1+ (1,0) [0|1] "" Vector__XXX
 SG_ PMF_a025_cpu1signMismatchNmi m25 : 24|1@1+ (1,0) [0|1] "" Vector__XXX
 SG_ PMF_a025_cpu2signMismatchNmi m25 : 25|1@1+ (1,0) [0|1] "" Vector__XXX
 SG_ PMF_a025_pieVectErrorNmi m25 : 26|1@1+ (1,0) [0|1] "" Vector__XXX
 SG_ PMF_a025_sysDbgNmi m25 : 27|1@1+ (1,0) [0|1] "" Vector__XXX
 SG_ PMF_a025_rlNmi m25 : 28|1@1+ (1,0) [0|1] "" Vector__XXX
 SG_ PMF_a025_ovfNmi m25 : 29|1@1+ (1,0) [0|1] "" Vector__XXX
 SG_ PMF_a025_possibleSafetyICReset m25 : 30|1@1+ (1,0) [0|1] "" Vector__XXX
 SG_ PMF_a025_powerOnReset m25 : 31|1@1+ (1,0) [0|1] "" Vector__XXX
 SG_ PMF_a025_watchdogTimer0 m25 : 32|1@1+ (1,0) [0|1] "" Vector__XXX
 SG_ PMF_a025_watchdogTimer1 m25 : 33|1@1+ (1,0) [0|1] "" Vector__XXX
 SG_ PMF_a025_watchdogTimer2 m25 : 34|1@1+ (1,0) [0|1] "" Vector__XXX
 SG_ PMF_a025_watchdogTimer3 m25 : 35|1@1+ (1,0) [0|1] "" Vector__XXX
 SG_ PMF_a025_warmResetReq m25 : 36|1@1+ (1,0) [0|1] "" Vector__XXX
 SG_ PMF_a025_externalPadReset m25 : 37|1@1+ (1,0) [0|1] "" Vector__XXX
 SG_ PMF_a025_hwSecModuleWatchdogTime m25 : 38|1@1+ (1,0) [0|1] "" Vector__XXX
 SG_ PMF_a025_debugReset m25 : 39|1@1+ (1,0) [0|1] "" Vector__XXX
 SG_ PMF_a025_tempSense0 m25 : 40|1@1+ (1,0) [0|1] "" Vector__XXX
 SG_ PMF_a025_tempSense1 m25 : 41|1@1+ (1,0) [0|1] "" Vector__XXX
 SG_ PMF_a026_reason m26 : 16|1@1+ (1,0) [0|1] "" Vector__XXX
 SG_ PMF_a026_isrCount20kHz m26 : 17|5@1+ (1,0) [0|31] "" Vector__XXX
 SG_ PMF_a026_isrCount1kHz m26 : 22|4@1+ (1,0) [0|15] "" Vector__XXX
 SG_ PMF_a026_switchingActive m26 : 26|1@1+ (1,0) [0|1] "" Vector__XXX
 SG_ PMF_a026_systemStackOvf m26 : 27|1@1+ (1,0) [0|1] "" Vector__XXX
 SG_ PMF_a026_controlStackOvf m26 : 28|1@1+ (1,0) [0|1] "" Vector__XXX
 SG_ PMF_a026_idleStackOvf m26 : 29|1@1+ (1,0) [0|1] "" Vector__XXX
 SG_ PMF_a026_eepStackOvf m26 : 30|1@1+ (1,0) [0|1] "" Vector__XXX
 SG_ PMF_a026_immStackOvf m26 : 31|1@1+ (1,0) [0|1] "" Vector__XXX
 SG_ PMF_a026_xdcErrorIdMSW m26 : 32|10@1+ (1,0) [0|1023] "" Vector__XXX
 SG_ PMF_a026_xdcErrorArg1 m26 : 42|22@1- (1,0) [-2097152|2097151] "" Vector__XXX
 SG_ PMF_a032_w0 m32 : 16|16@1+ (1,0) [0|65535] "" Vector__XXX
 SG_ PMF_a032_w1 m32 : 32|16@1+ (1,0) [0|65535] "" Vector__XXX
 SG_ PMF_a032_w2 m32 : 48|16@1+ (1,0) [0|65535] "" Vector__XXX
 SG_ PMF_a033_state m33 : 16|4@1+ (1,0) [0|15] "" Vector__XXX
 SG_ PMF_a033_failReason m33 : 20|3@1+ (1,0) [0|7] "" Vector__XXX
 SG_ PMF_a033_DSADC_Ia m33 : 24|16@1- (0.0939,0) [-3076.9152|3076.8213] "A" Vector__XXX
 SG_ PMF_a033_DSADC_Ib m33 : 40|16@1- (0.0939,0) [-3076.9152|3076.8213] "A" Vector__XXX
 SG_ PMF_a036_timeSinceTxHWI m36 : 16|6@1+ (64,0) [0|4032] "us" Vector__XXX
 SG_ PMF_a036_timeSinceRxHWI m36 : 22|6@1+ (64,0) [0|4032] "us" Vector__XXX
 SG_ PMF_a036_timeSince100HzTxSWI m36 : 28|6@1+ (0.32,0) [0|20.16] "ms" Vector__XXX
 SG_ PMF_a036_timeSince1kHzCLK m36 : 34|6@1+ (32,0) [0|2016] "us" Vector__XXX
 SG_ PMF_a036_timeSince1kHzSWI m36 : 40|6@1+ (32,0) [0|2016] "us" Vector__XXX
 SG_ PMF_a036_timeSinceIdle m36 : 46|6@1+ (0.16,0) [0|10.08] "ms" Vector__XXX
 SG_ PMF_a036_ovfStackId m36 : 52|4@1+ (1,0) [0|14] "" Vector__XXX
 SG_ PMF_a036_inTxISR m36 : 56|1@1+ (1,0) [0|1] "" Vector__XXX
 SG_ PMF_a036_inTxHWI m36 : 57|1@1+ (1,0) [0|1] "" Vector__XXX
 SG_ PMF_a036_inRxHWI m36 : 58|1@1+ (1,0) [0|1] "" Vector__XXX
 SG_ PMF_a036_in1kHzSWI m36 : 59|1@1+ (1,0) [0|1] "" Vector__XXX
 SG_ PMF_a036_in1kHzCLK m36 : 60|1@1+ (1,0) [0|1] "" Vector__XXX
 SG_ PMF_a036_in100HzCLK m36 : 61|1@1+ (1,0) [0|1] "" Vector__XXX
 SG_ PMF_a036_in10HzCLK m36 : 62|1@1+ (1,0) [0|1] "" Vector__XXX
 SG_ PMF_a036_in1HzCLK m36 : 63|1@1+ (1,0) [0|1] "" Vector__XXX
 SG_ PMF_a037_hvpFaults m37 : 16|1@1+ (1,0) [0|1] "" Vector__XXX
 SG_ PMF_a039_DIS_status m39 : 16|1@1+ (1,0) [0|1] "" Vector__XXX
 SG_ PMF_a039_DIS_torque m39 : 17|1@1+ (1,0) [0|1] "" Vector__XXX
 SG_ PMF_a039_messageId m39 : 24|16@1+ (1,0) [0|65535] "" Vector__XXX
 SG_ PMF_a040_PM_state m40 : 16|1@1+ (1,0) [0|1] "" Vector__XXX
 SG_ PMF_a040_messageId m40 : 24|16@1+ (1,0) [0|65535] "" Vector__XXX
 SG_ PMF_a040_PM_locState m40 : 40|1@1+ (1,0) [0|1] "" Vector__XXX
 SG_ PMF_a042_GTW_carConfig m42 : 16|1@1+ (1,0) [0|1] "" Vector__XXX
 SG_ PMF_a042_GTW_time m42 : 17|1@1+ (1,0) [0|1] "" Vector__XXX
 SG_ PMF_a042_GTW_drivetrainType m42 : 18|2@1+ (1,0) [0|3] "" Vector__XXX
 SG_ PMF_a042_expectedPerformanceCfg m42 : 20|2@1+ (1,0) [0|3] "" Vector__XXX
 SG_ PMF_a042_gearControl m42 : 22|1@1+ (1,0) [0|1] "" Vector__XXX
 SG_ PMF_a053_LVPowerState m53 : 16|1@1+ (1,0) [0|1] "" Vector__XXX
 SG_ PMF_a053_coolant m53 : 17|1@1+ (1,0) [0|1] "" Vector__XXX
 SG_ PMF_a053_vcleftSwitchStatus m53 : 18|1@1+ (1,0) [0|1] "" Vector__XXX
 SG_ PMF_a053_restraintStatus m53 : 19|1@1+ (1,0) [0|1] "" Vector__XXX
 SG_ PMF_a053_sensors m53 : 20|1@1+ (1,0) [0|1] "" Vector__XXX
 SG_ PMF_a054_uiPowertrainControl m54 : 16|1@1+ (1,0) [0|1] "" Vector__XXX
 SG_ PMF_a054_uiChassisControl m54 : 17|1@1+ (1,0) [0|1] "" Vector__XXX
 SG_ PMF_a054_uiCruiseControl m54 : 18|1@1+ (1,0) [0|1] "" Vector__XXX
 SG_ PMF_a054_uiTrackModeSettings m54 : 19|1@1+ (1,0) [0|1] "" Vector__XXX
 SG_ PMF_a054_uiTPMSRCPSetting m54 : 20|1@1+ (1,0) [0|1] "" Vector__XXX
 SG_ PMF_a055_motorRPM m55 : 16|16@1- (1,0) [-32768|32767] "RPM" Vector__XXX
 SG_ PMF_a055_phaseAngle m55 : 32|8@1+ (0.00308,0) [0|0.7854] "1" Vector__XXX
 SG_ PMF_a055_commonGain m55 : 40|8@1+ (0.02,0) [0|5.1] "1" Vector__XXX
 SG_ PMF_a055_notReady m55 : 48|1@1+ (1,0) [0|1] "" Vector__XXX
 SG_ PMF_a055_noCarrier m55 : 49|1@1+ (1,0) [0|1] "" Vector__XXX
 SG_ PMF_a055_phaseOutOfSpec m55 : 50|1@1+ (1,0) [0|1] "" Vector__XXX
 SG_ PMF_a055_diElecAngleMismatch m55 : 51|1@1+ (1,0) [0|1] "" Vector__XXX
 SG_ PMF_a055_diSpeedMismatch m55 : 52|1@1+ (1,0) [0|1] "" Vector__XXX
 SG_ PMF_a055_claMIA m55 : 53|1@1+ (1,0) [0|1] "" Vector__XXX
 SG_ PMF_a055_diMIA m55 : 54|1@1+ (1,0) [0|1] "" Vector__XXX
 SG_ PMF_a055_diElecAngleMismatchWarn m55 : 55|1@1+ (1,0) [0|1] "" Vector__XXX
 SG_ PMF_a056_mailboxID m56 : 16|16@1+ (1,0) [0|65535] "" Vector__XXX
 SG_ PMF_a056_canID m56 : 32|16@1+ (1,0) [0|65535] "" Vector__XXX
 SG_ PMF_a056_errorType m56 : 48|3@1+ (1,0) [0|7] "" Vector__XXX
 SG_ PMF_a057_canID m57 : 16|12@1+ (1,0) [0|4095] "" Vector__XXX
 SG_ PMF_a057_errorType m57 : 28|3@1+ (1,0) [0|7] "" Vector__XXX
 SG_ PMF_a057_badValue1 m57 : 32|16@1+ (1,0) [0|65535] "" Vector__XXX
 SG_ PMF_a057_badValue2 m57 : 48|16@1+ (1,0) [0|65535] "" Vector__XXX
 SG_ PMF_a058_hvilCurrent m58 : 16|8@1+ (0.1,0) [0|25.5] "mA" Vector__XXX
 SG_ PMF_a061_diIpcVersion m61 : 16|8@1+ (1,0) [0|255] "" Vector__XXX
 SG_ PMF_a061_pmIpcVersion m61 : 24|8@1+ (1,0) [0|255] "" Vector__XXX
 SG_ PMF_a062_address m62 : 16|32@1+ (1,0) [0|4294967295] "" Vector__XXX
 SG_ PMF_a062_errorType m62 : 48|4@1+ (1,0) [0|15] "" Vector__XXX
 SG_ PMF_a064_interventionType m64 : 16|4@1+ (1,0) [0|15] "" Vector__XXX
 SG_ PMF_a064_torqueCmdState m64 : 20|4@1+ (1,0) [1|15] "" Vector__XXX
 SG_ PMF_a064_shortDetectedByDI m64 : 24|1@1+ (1,0) [0|1] "" Vector__XXX
 SG_ PMF_a064_UI_stoppingMode m64 : 25|2@1+ (1,0) [0|3] "" Vector__XXX
 SG_ PMF_a064_diCrsState m64 : 27|3@1+ (1,0) [0|7] "" Vector__XXX
 SG_ PMF_a064_pmCrsState m64 : 32|3@1+ (1,0) [0|7] "" Vector__XXX
 SG_ PMF_a082_faultAddress m82 : 16|32@1+ (1,0) [0|4294967295] "" Vector__XXX
 SG_ PMF_a082_isWriteNotRead m82 : 48|1@1+ (1,0) [0|1] "" Vector__XXX
 SG_ PMF_a084_faultAddress m84 : 16|32@1+ (1,0) [0|4294967295] "" Vector__XXX
 SG_ PMF_a084_firewallId m84 : 48|5@1+ (1,0) [0|31] "" Vector__XXX
 SG_ PMF_a084_privId m84 : 56|4@1+ (1,0) [0|15] "" Vector__XXX
 SG_ PMF_a084_ns m84 : 60|1@1+ (1,0) [0|1] "" Vector__XXX
 SG_ PMF_a084_faultType m84 : 61|3@1+ (1,0) [0|7] "" Vector__XXX
 SG_ PMF_a092_pllClockSource m92 : 16|2@1+ (1,0) [0|3] "" Vector__XXX
 SG_ PMF_a100_index1kHzPeriodic m100 : 16|8@1+ (1,0) [0|255] "" Vector__XXX
 SG_ PMF_a100_index100HzPeriodic m100 : 24|8@1+ (1,0) [0|255] "" Vector__XXX
 SG_ PMF_a100_index10HzPeriodic m100 : 32|8@1+ (1,0) [0|255] "" Vector__XXX
 SG_ PMF_a100_indexSWI m100 : 40|8@1+ (1,0) [0|255] "" Vector__XXX
 SG_ PMF_a100_eepEvent m100 : 48|8@1+ (1,0) [0|255] "" Vector__XXX
 SG_ PMF_a100_module500HzActive m100 : 56|1@1+ (1,0) [0|1] "" Vector__XXX
 SG_ PMF_a100_module50HzActive m100 : 57|1@1+ (1,0) [0|1] "" Vector__XXX
 SG_ PMF_a100_module1HzActive m100 : 58|1@1+ (1,0) [0|1] "" Vector__XXX
 SG_ PMF_a100_task10HzActive m100 : 59|1@1+ (1,0) [0|1] "" Vector__XXX
 SG_ PMF_a100_taskUdsActive m100 : 60|1@1+ (1,0) [0|1] "" Vector__XXX

BO_ 790 PMF_info: 8 PMF
 SG_ PMF_infoIndex M : 0|8@1+ (1,0) [0|255] "" Vector__XXX
 SG_ PMF_buildType m10 : 8|8@1+ (1,0) [0|255] "" Vector__XXX
 SG_ PMF_buildConfigurationId m10 : 16|16@1+ (1,0) [0|65535] "" Vector__XXX
 SG_ PMF_hardwareId m10 : 32|8@1+ (1,0) [0|252] "" Vector__XXX
 SG_ PMF_deviceFused m10 : 40|1@1+ (1,0) [0|1] "" Vector__XXX
 SG_ PMF_componentId m10 : 48|16@1+ (1,0) [0|65535] "" Vector__XXX
 SG_ PMF_pcbaId m11 : 16|8@1+ (1,0) [0|255] "" Vector__XXX
 SG_ PMF_assemblyId m11 : 24|8@1+ (1,0) [0|255] "" Vector__XXX
 SG_ PMF_usageId m11 : 32|16@1+ (1,0) [0|65535] "" Vector__XXX
 SG_ PMF_subUsageId m11 : 48|16@1+ (1,0) [0|65535] "" Vector__XXX
 SG_ PMF_applicationCrc m13 : 32|32@1+ (1,0) [0|4294967295] "" Vector__XXX
 SG_ PMF_appGitHash m17 : 8|56@1+ (1,0) [0|7.20575940379e+16] "" Vector__XXX
 SG_ PMF_bootGitHash m18 : 8|56@1+ (1,0) [0|7.20575940379e+16] "" Vector__XXX
 SG_ PMF_platformTyp m19 : 8|8@1+ (1,0) [0|255] "" Vector__XXX
 SG_ PMF_udsProtocolVersion m20 : 8|8@1+ (1,0) [0|255] "" Vector__XXX
 SG_ PMF_bootloaderCrc m20 : 32|32@1+ (1,0) [0|4294967295] "" Vector__XXX

BO_ 1446 PMR_alertLog: 8 PMR
 SG_ PMR_alertID M : 0|7@1+ (1,0) [0|127] "" Vector__XXX
 SG_ PMR_alertState : 15|1@1+ (1,0) [0|1] "" Vector__XXX
 SG_ PMR_a001_w0 m1 : 16|16@1+ (1,0) [0|65535] "" Vector__XXX
 SG_ PMR_a001_w1 m1 : 32|16@1+ (1,0) [0|65535] "" Vector__XXX
 SG_ PMR_a001_w2 m1 : 48|16@1+ (1,0) [0|65535] "" Vector__XXX
 SG_ PMR_a002_torqueAverage m2 : 16|1@1+ (1,0) [0|1] "" Vector__XXX
 SG_ PMR_a002_torqueWindow m2 : 17|1@1+ (1,0) [0|1] "" Vector__XXX
 SG_ PMR_a002_torqueMeasured m2 : 18|13@1- (2,0) [-8192|8190] "Nm" Vector__XXX
 SG_ PMR_a002_torqueAccelAverage m2 : 32|13@1- (2,0) [-8192|8190] "Nm" Vector__XXX
 SG_ PMR_a002_torqueAccelWindow m2 : 48|13@1- (2,0) [-8192|8190] "Nm" Vector__XXX
 SG_ PMR_a003_reverseGear m3 : 16|1@1+ (1,0) [0|1] "" Vector__XXX
 SG_ PMR_a003_pedalPos m3 : 24|8@1+ (0.4,0) [0|102] "%" Vector__XXX
 SG_ PMR_a003_zeroPointPedal m3 : 32|8@1+ (0.4,0) [0|102] "%" Vector__XXX
 SG_ PMR_a004_torqueAverage m4 : 16|1@1+ (1,0) [0|1] "" Vector__XXX
 SG_ PMR_a004_torqueWindow m4 : 17|1@1+ (1,0) [0|1] "" Vector__XXX
 SG_ PMR_a004_torqueMeasured m4 : 18|13@1- (2,0) [-8192|8190] "Nm" Vector__XXX
 SG_ PMR_a004_torqueDecelAverage m4 : 32|13@1- (2,0) [-8192|8190] "Nm" Vector__XXX
 SG_ PMR_a004_torqueDecelWindow m4 : 48|13@1- (2,0) [-8192|8190] "Nm" Vector__XXX
 SG_ PMR_a005_torqueReason m5 : 16|2@1+ (1,0) [0|3] "" Vector__XXX
 SG_ PMR_a005_torqueMeasured m5 : 18|13@1- (2,0) [-8192|8190] "Nm" Vector__XXX
 SG_ PMR_a005_iDQmagnitude m5 : 32|16@1- (0.0939,0) [-3076.9152|3076.8213] "A" Vector__XXX
 SG_ PMR_a006_torqueActual m6 : 16|13@1- (2,0) [-8192|8190] "Nm" Vector__XXX
 SG_ PMR_a006_motorRPM m6 : 32|16@1- (1,0) [-32768|32767] "RPM" Vector__XXX
 SG_ PMR_a006_torqueMeasured m6 : 48|13@1- (2,0) [-8192|8190] "Nm" Vector__XXX
 SG_ PMR_a010_messageId m10 : 16|16@1+ (1,0) [0|65535] "" Vector__XXX
 SG_ PMR_a010_DI_status m10 : 32|1@1+ (1,0) [0|1] "" Vector__XXX
 SG_ PMR_a010_DI_torque m10 : 33|1@1+ (1,0) [0|1] "" Vector__XXX
 SG_ PMR_a010_DI_slaveCommand m10 : 34|1@1+ (1,0) [0|1] "" Vector__XXX
 SG_ PMR_a010_DI_locStatus m10 : 35|1@1+ (1,0) [0|1] "" Vector__XXX
 SG_ PMR_a010_DI_speed m10 : 36|1@1+ (1,0) [0|1] "" Vector__XXX
 SG_ PMR_a010_DI_systemStatus m10 : 37|1@1+ (1,0) [0|1] "" Vector__XXX
 SG_ PMR_a010_DI_chassisControl m10 : 38|1@1+ (1,0) [0|1] "" Vector__XXX
 SG_ PMR_a010_DI_chassisControl2 m10 : 39|1@1+ (1,0) [0|1] "" Vector__XXX
 SG_ PMR_a010_vdcLeft m10 : 40|1@1+ (1,0) [0|1] "" Vector__XXX
 SG_ PMR_a010_vdcRight m10 : 41|1@1+ (1,0) [0|1] "" Vector__XXX
 SG_ PMR_a010_DI_vehicleEstimates m10 : 42|1@1+ (1,0) [0|1] "" Vector__XXX
 SG_ PMR_a010_DI_brakeCommand m10 : 43|1@1+ (1,0) [0|1] "" Vector__XXX
 SG_ PMR_a010_DI_difCommand m10 : 44|1@1+ (1,0) [0|1] "" Vector__XXX
 SG_ PMR_a010_DI_dirCommand m10 : 45|1@1+ (1,0) [0|1] "" Vector__XXX
 SG_ PMR_a010_DI_dirVehicle m10 : 46|1@1+ (1,0) [0|1] "" Vector__XXX
 SG_ PMR_a010_DI_locStatus2 m10 : 47|1@1+ (1,0) [0|1] "" Vector__XXX
 SG_ PMR_a011_Ia m11 : 16|16@1- (0.0939,0) [-3076.9152|3076.8213] "A" Vector__XXX
 SG_ PMR_a011_Ib m11 : 32|16@1- (0.0939,0) [-3076.9152|3076.8213] "A" Vector__XXX
 SG_ PMR_a011_currentVref m11 : 48|11@1+ (0.005,0) [0|10.235] "V" Vector__XXX
 SG_ PMR_a011_badPhaseAsample m11 : 59|1@1+ (1,0) [0|1] "" Vector__XXX
 SG_ PMR_a011_badPhaseBsample m11 : 60|1@1+ (1,0) [0|1] "" Vector__XXX
 SG_ PMR_a011_sampleFreeze m11 : 61|1@1+ (1,0) [0|1] "" Vector__XXX
 SG_ PMR_a012_canID m12 : 16|12@1+ (1,0) [0|4095] "" Vector__XXX
 SG_ PMR_a012_errorType m12 : 28|3@1+ (1,0) [0|7] "" Vector__XXX
 SG_ PMR_a012_badValue1 m12 : 32|16@1+ (1,0) [0|65535] "" Vector__XXX
 SG_ PMR_a012_badValue2 m12 : 48|16@1+ (1,0) [0|65535] "" Vector__XXX
 SG_ PMR_a013_mailboxID m13 : 16|16@1+ (1,0) [0|65535] "" Vector__XXX
 SG_ PMR_a013_canID m13 : 32|16@1+ (1,0) [0|65535] "" Vector__XXX
 SG_ PMR_a013_errorType m13 : 48|3@1+ (1,0) [0|7] "" Vector__XXX
 SG_ PMR_a017_EPBL_status m17 : 16|1@1+ (1,0) [0|1] "" Vector__XXX
 SG_ PMR_a017_EPBR_status m17 : 17|1@1+ (1,0) [0|1] "" Vector__XXX
 SG_ PMR_a018_w0 m18 : 16|16@1+ (1,0) [0|65535] "" Vector__XXX
 SG_ PMR_a018_w1 m18 : 32|16@1+ (1,0) [0|65535] "" Vector__XXX
 SG_ PMR_a018_w2 m18 : 48|16@1+ (1,0) [0|65535] "" Vector__XXX
 SG_ PMR_a019_statorTemp1 m19 : 16|16@1- (0.1,0) [-3276.8|3276.7] "DegC" Vector__XXX
 SG_ PMR_a019_statorTslope1 m19 : 32|16@1- (0.1,0) [-3276.8|3276.7] "DegC/s" Vector__XXX
 SG_ PMR_a025_sccReset m25 : 16|1@1+ (1,0) [0|1] "" Vector__XXX
 SG_ PMR_a025_hibernate m25 : 17|1@1+ (1,0) [0|1] "" Vector__XXX
 SG_ PMR_a025_hwBist m25 : 18|1@1+ (1,0) [0|1] "" Vector__XXX
 SG_ PMR_a025_nmiWatchdog m25 : 19|1@1+ (1,0) [0|1] "" Vector__XXX
 SG_ PMR_a025_watchdog m25 : 20|1@1+ (1,0) [0|1] "" Vector__XXX
 SG_ PMR_a025_clockFailNmi m25 : 21|1@1+ (1,0) [0|1] "" Vector__XXX
 SG_ PMR_a025_ramUncErrorNmi m25 : 22|1@1+ (1,0) [0|1] "" Vector__XXX
 SG_ PMR_a025_flashUncErrorNmi m25 : 23|1@1+ (1,0) [0|1] "" Vector__XXX
 SG_ PMR_a025_cpu1signMismatchNmi m25 : 24|1@1+ (1,0) [0|1] "" Vector__XXX
 SG_ PMR_a025_cpu2signMismatchNmi m25 : 25|1@1+ (1,0) [0|1] "" Vector__XXX
 SG_ PMR_a025_pieVectErrorNmi m25 : 26|1@1+ (1,0) [0|1] "" Vector__XXX
 SG_ PMR_a025_sysDbgNmi m25 : 27|1@1+ (1,0) [0|1] "" Vector__XXX
 SG_ PMR_a025_rlNmi m25 : 28|1@1+ (1,0) [0|1] "" Vector__XXX
 SG_ PMR_a025_ovfNmi m25 : 29|1@1+ (1,0) [0|1] "" Vector__XXX
 SG_ PMR_a025_possibleSafetyICReset m25 : 30|1@1+ (1,0) [0|1] "" Vector__XXX
 SG_ PMR_a025_powerOnReset m25 : 31|1@1+ (1,0) [0|1] "" Vector__XXX
 SG_ PMR_a025_watchdogTimer0 m25 : 32|1@1+ (1,0) [0|1] "" Vector__XXX
 SG_ PMR_a025_watchdogTimer1 m25 : 33|1@1+ (1,0) [0|1] "" Vector__XXX
 SG_ PMR_a025_watchdogTimer2 m25 : 34|1@1+ (1,0) [0|1] "" Vector__XXX
 SG_ PMR_a025_watchdogTimer3 m25 : 35|1@1+ (1,0) [0|1] "" Vector__XXX
 SG_ PMR_a025_warmResetReq m25 : 36|1@1+ (1,0) [0|1] "" Vector__XXX
 SG_ PMR_a025_externalPadReset m25 : 37|1@1+ (1,0) [0|1] "" Vector__XXX
 SG_ PMR_a025_hwSecModuleWatchdogTime m25 : 38|1@1+ (1,0) [0|1] "" Vector__XXX
 SG_ PMR_a025_debugReset m25 : 39|1@1+ (1,0) [0|1] "" Vector__XXX
 SG_ PMR_a025_tempSense0 m25 : 40|1@1+ (1,0) [0|1] "" Vector__XXX
 SG_ PMR_a025_tempSense1 m25 : 41|1@1+ (1,0) [0|1] "" Vector__XXX
 SG_ PMR_a026_reason m26 : 16|1@1+ (1,0) [0|1] "" Vector__XXX
 SG_ PMR_a026_isrCount20kHz m26 : 17|5@1+ (1,0) [0|31] "" Vector__XXX
 SG_ PMR_a026_isrCount1kHz m26 : 22|4@1+ (1,0) [0|15] "" Vector__XXX
 SG_ PMR_a026_switchingActive m26 : 26|1@1+ (1,0) [0|1] "" Vector__XXX
 SG_ PMR_a026_systemStackOvf m26 : 27|1@1+ (1,0) [0|1] "" Vector__XXX
 SG_ PMR_a026_controlStackOvf m26 : 28|1@1+ (1,0) [0|1] "" Vector__XXX
 SG_ PMR_a026_idleStackOvf m26 : 29|1@1+ (1,0) [0|1] "" Vector__XXX
 SG_ PMR_a026_eepStackOvf m26 : 30|1@1+ (1,0) [0|1] "" Vector__XXX
 SG_ PMR_a026_immStackOvf m26 : 31|1@1+ (1,0) [0|1] "" Vector__XXX
 SG_ PMR_a026_xdcErrorIdMSW m26 : 32|10@1+ (1,0) [0|1023] "" Vector__XXX
 SG_ PMR_a026_xdcErrorArg1 m26 : 42|22@1- (1,0) [-2097152|2097151] "" Vector__XXX
 SG_ PMR_a032_w0 m32 : 16|16@1+ (1,0) [0|65535] "" Vector__XXX
 SG_ PMR_a032_w1 m32 : 32|16@1+ (1,0) [0|65535] "" Vector__XXX
 SG_ PMR_a032_w2 m32 : 48|16@1+ (1,0) [0|65535] "" Vector__XXX
 SG_ PMR_a033_state m33 : 16|4@1+ (1,0) [0|15] "" Vector__XXX
 SG_ PMR_a033_failReason m33 : 20|3@1+ (1,0) [0|7] "" Vector__XXX
 SG_ PMR_a033_DSADC_Ia m33 : 24|16@1- (0.0939,0) [-3076.9152|3076.8213] "A" Vector__XXX
 SG_ PMR_a033_DSADC_Ib m33 : 40|16@1- (0.0939,0) [-3076.9152|3076.8213] "A" Vector__XXX
 SG_ PMR_a036_timeSinceTxHWI m36 : 16|6@1+ (64,0) [0|4032] "us" Vector__XXX
 SG_ PMR_a036_timeSinceRxHWI m36 : 22|6@1+ (64,0) [0|4032] "us" Vector__XXX
 SG_ PMR_a036_timeSince100HzTxSWI m36 : 28|6@1+ (0.32,0) [0|20.16] "ms" Vector__XXX
 SG_ PMR_a036_timeSince1kHzCLK m36 : 34|6@1+ (32,0) [0|2016] "us" Vector__XXX
 SG_ PMR_a036_timeSince1kHzSWI m36 : 40|6@1+ (32,0) [0|2016] "us" Vector__XXX
 SG_ PMR_a036_timeSinceIdle m36 : 46|6@1+ (0.16,0) [0|10.08] "ms" Vector__XXX
 SG_ PMR_a036_ovfStackId m36 : 52|4@1+ (1,0) [0|14] "" Vector__XXX
 SG_ PMR_a036_inTxISR m36 : 56|1@1+ (1,0) [0|1] "" Vector__XXX
 SG_ PMR_a036_inTxHWI m36 : 57|1@1+ (1,0) [0|1] "" Vector__XXX
 SG_ PMR_a036_inRxHWI m36 : 58|1@1+ (1,0) [0|1] "" Vector__XXX
 SG_ PMR_a036_in1kHzSWI m36 : 59|1@1+ (1,0) [0|1] "" Vector__XXX
 SG_ PMR_a036_in1kHzCLK m36 : 60|1@1+ (1,0) [0|1] "" Vector__XXX
 SG_ PMR_a036_in100HzCLK m36 : 61|1@1+ (1,0) [0|1] "" Vector__XXX
 SG_ PMR_a036_in10HzCLK m36 : 62|1@1+ (1,0) [0|1] "" Vector__XXX
 SG_ PMR_a036_in1HzCLK m36 : 63|1@1+ (1,0) [0|1] "" Vector__XXX
 SG_ PMR_a037_hvpFaults m37 : 16|1@1+ (1,0) [0|1] "" Vector__XXX
 SG_ PMR_a039_DIS_status m39 : 16|1@1+ (1,0) [0|1] "" Vector__XXX
 SG_ PMR_a039_DIS_torque m39 : 17|1@1+ (1,0) [0|1] "" Vector__XXX
 SG_ PMR_a039_messageId m39 : 24|16@1+ (1,0) [0|65535] "" Vector__XXX
 SG_ PMR_a040_PM_state m40 : 16|1@1+ (1,0) [0|1] "" Vector__XXX
 SG_ PMR_a040_messageId m40 : 24|16@1+ (1,0) [0|65535] "" Vector__XXX
 SG_ PMR_a040_PM_locState m40 : 40|1@1+ (1,0) [0|1] "" Vector__XXX
 SG_ PMR_a042_GTW_carConfig m42 : 16|1@1+ (1,0) [0|1] "" Vector__XXX
 SG_ PMR_a042_GTW_time m42 : 17|1@1+ (1,0) [0|1] "" Vector__XXX
 SG_ PMR_a042_GTW_drivetrainType m42 : 18|2@1+ (1,0) [0|3] "" Vector__XXX
 SG_ PMR_a042_expectedPerformanceCfg m42 : 20|2@1+ (1,0) [0|3] "" Vector__XXX
 SG_ PMR_a042_gearControl m42 : 22|1@1+ (1,0) [0|1] "" Vector__XXX
 SG_ PMR_a053_LVPowerState m53 : 16|1@1+ (1,0) [0|1] "" Vector__XXX
 SG_ PMR_a053_coolant m53 : 17|1@1+ (1,0) [0|1] "" Vector__XXX
 SG_ PMR_a053_vcleftSwitchStatus m53 : 18|1@1+ (1,0) [0|1] "" Vector__XXX
 SG_ PMR_a053_restraintStatus m53 : 19|1@1+ (1,0) [0|1] "" Vector__XXX
 SG_ PMR_a053_sensors m53 : 20|1@1+ (1,0) [0|1] "" Vector__XXX
 SG_ PMR_a054_uiPowertrainControl m54 : 16|1@1+ (1,0) [0|1] "" Vector__XXX
 SG_ PMR_a054_uiChassisControl m54 : 17|1@1+ (1,0) [0|1] "" Vector__XXX
 SG_ PMR_a054_uiCruiseControl m54 : 18|1@1+ (1,0) [0|1] "" Vector__XXX
 SG_ PMR_a054_uiTrackModeSettings m54 : 19|1@1+ (1,0) [0|1] "" Vector__XXX
 SG_ PMR_a054_uiTPMSRCPSetting m54 : 20|1@1+ (1,0) [0|1] "" Vector__XXX
 SG_ PMR_a055_motorRPM m55 : 16|16@1- (1,0) [-32768|32767] "RPM" Vector__XXX
 SG_ PMR_a055_phaseAngle m55 : 32|8@1+ (0.00308,0) [0|0.7854] "1" Vector__XXX
 SG_ PMR_a055_commonGain m55 : 40|8@1+ (0.02,0) [0|5.1] "1" Vector__XXX
 SG_ PMR_a055_notReady m55 : 48|1@1+ (1,0) [0|1] "" Vector__XXX
 SG_ PMR_a055_noCarrier m55 : 49|1@1+ (1,0) [0|1] "" Vector__XXX
 SG_ PMR_a055_phaseOutOfSpec m55 : 50|1@1+ (1,0) [0|1] "" Vector__XXX
 SG_ PMR_a055_diElecAngleMismatch m55 : 51|1@1+ (1,0) [0|1] "" Vector__XXX
 SG_ PMR_a055_diSpeedMismatch m55 : 52|1@1+ (1,0) [0|1] "" Vector__XXX
 SG_ PMR_a055_claMIA m55 : 53|1@1+ (1,0) [0|1] "" Vector__XXX
 SG_ PMR_a055_diMIA m55 : 54|1@1+ (1,0) [0|1] "" Vector__XXX
 SG_ PMR_a055_diElecAngleMismatchWarn m55 : 55|1@1+ (1,0) [0|1] "" Vector__XXX
 SG_ PMR_a056_mailboxID m56 : 16|16@1+ (1,0) [0|65535] "" Vector__XXX
 SG_ PMR_a056_canID m56 : 32|16@1+ (1,0) [0|65535] "" Vector__XXX
 SG_ PMR_a056_errorType m56 : 48|3@1+ (1,0) [0|7] "" Vector__XXX
 SG_ PMR_a057_canID m57 : 16|12@1+ (1,0) [0|4095] "" Vector__XXX
 SG_ PMR_a057_errorType m57 : 28|3@1+ (1,0) [0|7] "" Vector__XXX
 SG_ PMR_a057_badValue1 m57 : 32|16@1+ (1,0) [0|65535] "" Vector__XXX
 SG_ PMR_a057_badValue2 m57 : 48|16@1+ (1,0) [0|65535] "" Vector__XXX
 SG_ PMR_a058_hvilCurrent m58 : 16|8@1+ (0.1,0) [0|25.5] "mA" Vector__XXX
 SG_ PMR_a061_diIpcVersion m61 : 16|8@1+ (1,0) [0|255] "" Vector__XXX
 SG_ PMR_a061_pmIpcVersion m61 : 24|8@1+ (1,0) [0|255] "" Vector__XXX
 SG_ PMR_a062_address m62 : 16|32@1+ (1,0) [0|4294967295] "" Vector__XXX
 SG_ PMR_a062_errorType m62 : 48|4@1+ (1,0) [0|15] "" Vector__XXX
 SG_ PMR_a064_interventionType m64 : 16|4@1+ (1,0) [0|15] "" Vector__XXX
 SG_ PMR_a064_torqueCmdState m64 : 20|4@1+ (1,0) [1|15] "" Vector__XXX
 SG_ PMR_a064_shortDetectedByDI m64 : 24|1@1+ (1,0) [0|1] "" Vector__XXX
 SG_ PMR_a064_UI_stoppingMode m64 : 25|2@1+ (1,0) [0|3] "" Vector__XXX
 SG_ PMR_a064_diCrsState m64 : 27|3@1+ (1,0) [0|7] "" Vector__XXX
 SG_ PMR_a064_pmCrsState m64 : 32|3@1+ (1,0) [0|7] "" Vector__XXX
 SG_ PMR_a082_faultAddress m82 : 16|32@1+ (1,0) [0|4294967295] "" Vector__XXX
 SG_ PMR_a082_isWriteNotRead m82 : 48|1@1+ (1,0) [0|1] "" Vector__XXX
 SG_ PMR_a084_faultAddress m84 : 16|32@1+ (1,0) [0|4294967295] "" Vector__XXX
 SG_ PMR_a084_firewallId m84 : 48|5@1+ (1,0) [0|31] "" Vector__XXX
 SG_ PMR_a084_privId m84 : 56|4@1+ (1,0) [0|15] "" Vector__XXX
 SG_ PMR_a084_ns m84 : 60|1@1+ (1,0) [0|1] "" Vector__XXX
 SG_ PMR_a084_faultType m84 : 61|3@1+ (1,0) [0|7] "" Vector__XXX
 SG_ PMR_a092_pllClockSource m92 : 16|2@1+ (1,0) [0|3] "" Vector__XXX
 SG_ PMR_a100_index1kHzPeriodic m100 : 16|8@1+ (1,0) [0|255] "" Vector__XXX
 SG_ PMR_a100_index100HzPeriodic m100 : 24|8@1+ (1,0) [0|255] "" Vector__XXX
 SG_ PMR_a100_index10HzPeriodic m100 : 32|8@1+ (1,0) [0|255] "" Vector__XXX
 SG_ PMR_a100_indexSWI m100 : 40|8@1+ (1,0) [0|255] "" Vector__XXX
 SG_ PMR_a100_eepEvent m100 : 48|8@1+ (1,0) [0|255] "" Vector__XXX
 SG_ PMR_a100_module500HzActive m100 : 56|1@1+ (1,0) [0|1] "" Vector__XXX
 SG_ PMR_a100_module50HzActive m100 : 57|1@1+ (1,0) [0|1] "" Vector__XXX
 SG_ PMR_a100_module1HzActive m100 : 58|1@1+ (1,0) [0|1] "" Vector__XXX
 SG_ PMR_a100_task10HzActive m100 : 59|1@1+ (1,0) [0|1] "" Vector__XXX
 SG_ PMR_a100_taskUdsActive m100 : 60|1@1+ (1,0) [0|1] "" Vector__XXX
 SG_ PMR_a101_VDDA18_ref33_uv m101 : 16|1@1+ (1,0) [0|1] "" Vector__XXX
 SG_ PMR_a101_VBGAP09_ov m101 : 17|1@1+ (1,0) [0|1] "" Vector__XXX
 SG_ PMR_a101_VBGAP09_uv m101 : 18|1@1+ (1,0) [0|1] "" Vector__XXX
 SG_ PMR_a101_VDDA18_refBGAP_ov m101 : 19|1@1+ (1,0) [0|1] "" Vector__XXX
 SG_ PMR_a101_VDDA18_refBGAP_uv m101 : 20|1@1+ (1,0) [0|1] "" Vector__XXX
 SG_ PMR_a101_VDD12_ov m101 : 21|1@1+ (1,0) [0|1] "" Vector__XXX
 SG_ PMR_a101_VDD12_uv m101 : 22|1@1+ (1,0) [0|1] "" Vector__XXX
 SG_ PMR_a101_VDDSBIO_ov m101 : 23|1@1+ (1,0) [0|1] "" Vector__XXX
 SG_ PMR_a101_VDDSBIO_uv m101 : 24|1@1+ (1,0) [0|1] "" Vector__XXX
 SG_ PMR_a101_VSYS_MON_uv m101 : 25|1@1+ (1,0) [0|1] "" Vector__XXX
 SG_ PMR_a101_VDDA33_uv m101 : 26|1@1+ (1,0) [0|1] "" Vector__XXX
 SG_ PMR_a101_ADC0_REF_ov m101 : 27|1@1+ (1,0) [0|1] "" Vector__XXX
 SG_ PMR_a101_ADC0_REF_uv m101 : 28|1@1+ (1,0) [0|1] "" Vector__XXX
 SG_ PMR_a101_ADC12_REF_ov m101 : 29|1@1+ (1,0) [0|1] "" Vector__XXX
 SG_ PMR_a101_ADC12_REF_uv m101 : 30|1@1+ (1,0) [0|1] "" Vector__XXX
 SG_ PMR_a101_ADC34_REF_ov m101 : 31|1@1+ (1,0) [0|1] "" Vector__XXX
 SG_ PMR_a101_ADC34_REF_uv m101 : 32|1@1+ (1,0) [0|1] "" Vector__XXX
 SG_ PMR_a101_ADCR01_REF_ov m101 : 33|1@1+ (1,0) [0|1] "" Vector__XXX
 SG_ PMR_a101_ADCR01_REF_uv m101 : 34|1@1+ (1,0) [0|1] "" Vector__XXX

BO_ 1748 PMR_info: 8 PMR
 SG_ PMR_infoIndex M : 0|8@1+ (1,0) [0|255] "" Vector__XXX
 SG_ PMR_buildType m10 : 8|8@1+ (1,0) [0|255] "" Vector__XXX
 SG_ PMR_buildConfigurationId m10 : 16|16@1+ (1,0) [0|65535] "" Vector__XXX
 SG_ PMR_hardwareId m10 : 32|8@1+ (1,0) [0|252] "" Vector__XXX
 SG_ PMR_deviceFused m10 : 40|1@1+ (1,0) [0|1] "" Vector__XXX
 SG_ PMR_componentId m10 : 48|16@1+ (1,0) [0|65535] "" Vector__XXX
 SG_ PMR_pcbaId m11 : 16|8@1+ (1,0) [0|255] "" Vector__XXX
 SG_ PMR_assemblyId m11 : 24|8@1+ (1,0) [0|255] "" Vector__XXX
 SG_ PMR_usageId m11 : 32|16@1+ (1,0) [0|65535] "" Vector__XXX
 SG_ PMR_subUsageId m11 : 48|16@1+ (1,0) [0|65535] "" Vector__XXX
 SG_ PMR_applicationCrc m13 : 32|32@1+ (1,0) [0|4294967295] "" Vector__XXX
 SG_ PMR_appGitHash m17 : 8|56@1+ (1,0) [0|7.20575940379e+16] "" Vector__XXX
 SG_ PMR_bootGitHash m18 : 8|56@1+ (1,0) [0|7.20575940379e+16] "" Vector__XXX
 SG_ PMR_platformTyp m19 : 8|8@1+ (1,0) [0|255] "" Vector__XXX
 SG_ PMR_udsProtocolVersion m20 : 8|8@1+ (1,0) [0|255] "" Vector__XXX
 SG_ PMR_bootloaderCrc m20 : 32|32@1+ (1,0) [0|4294967295] "" Vector__XXX

BO_TX_BU_ 932 : PCS;
BO_TX_BU_ 612 : PCS;
BO_TX_BU_ 516 : PCS;
BO_TX_BU_ 692 : PCS;
BO_TX_BU_ 548 : PCS;
BO_TX_BU_ 964 : PCS;
BO_TX_BU_ 708 : PCS;
BO_TX_BU_ 676 : PCS;
BO_TX_BU_ 1317 : PMF;
BO_TX_BU_ 790 : PMF;
BO_TX_BU_ 1446 : PMR;
BO_TX_BU_ 1748 : PMR;
CM_ BO_ 932 "Power conversion system (on-board charger and DC-DC converter) message: alert matrix";
CM_ SG_ 932 PCS_matrixIndex "Power conversion system (on-board charger and DC-DC converter): matrix index";
CM_ SG_ 932 PCS_a001_chgHwInputOc "Power conversion system (on-board charger and DC-DC converter): a001 chg hw input oc";
CM_ SG_ 932 PCS_a002_chgHwOutputOc "Power conversion system (on-board charger and DC-DC converter): a002 chg hw output oc";
CM_ SG_ 932 PCS_a003_chgHwInputOv "Power conversion system (on-board charger and DC-DC converter): a003 chg hw input ov";
CM_ SG_ 932 PCS_a004_chgHwIntBusOv "Power conversion system (on-board charger and DC-DC converter): a004 chg hw int bus ov";
CM_ SG_ 932 PCS_a005_chgOutputOv "Power conversion system (on-board charger and DC-DC converter): a005 chg output ov";
CM_ SG_ 932 PCS_a006_chgPrechargeFailedScr "Power conversion system (on-board charger and DC-DC converter): a006 chg precharge failed scr";
CM_ SG_ 932 PCS_a007_chgPhaseTempHot "Power conversion system (on-board charger and DC-DC converter): a007 chg phase temp hot";
CM_ SG_ 932 PCS_a008_chgPhaseOverTemp "Power conversion system (on-board charger and DC-DC converter): a008 chg phase over temp";
CM_ SG_ 932 PCS_a009_chgPfcCurrentRegulation "Power conversion system (on-board charger and DC-DC converter): a009 chg pfc current regulation";
CM_ SG_ 932 PCS_a010_chgIntBusVRegulation "Power conversion system (on-board charger and DC-DC converter): a010 chg int bus v regulation";
CM_ SG_ 932 PCS_a011_chgLlcCurrentRegulation "Power conversion system (on-board charger and DC-DC converter): a011 chg llc current regulation";
CM_ SG_ 932 PCS_a012_chgPfcIBandTracerFault "Power conversion system (on-board charger and DC-DC converter): a012 chg pfc i band tracer fault";
CM_ SG_ 932 PCS_a013_chgPrechargeFailedBoost "Power conversion system (on-board charger and DC-DC converter): a013 chg precharge failed boost";
CM_ SG_ 932 PCS_a014_chgTempRationality "Power conversion system (on-board charger and DC-DC converter): a014 chg temp rationality";
CM_ SG_ 932 PCS_a015_chg12vUv "Power conversion system (on-board charger and DC-DC converter): a015 chg12v uv";
CM_ SG_ 932 PCS_a016_chgAllPhasesFaulted "Power conversion system (on-board charger and DC-DC converter): a016 chg all phases faulted";
CM_ SG_ 932 PCS_a017_chgWallPowerRemoval "Power conversion system (on-board charger and DC-DC converter): a017 chg wall power removal";
CM_ SG_ 932 PCS_a018_chgUnknownGridConfig "Power conversion system (on-board charger and DC-DC converter): a018 chg unknown grid config";
CM_ SG_ 932 PCS_a019_acChargePowerLimited "Power conversion system (on-board charger and DC-DC converter): a019 ac charge power limited";
CM_ SG_ 932 PCS_a020_chgEnableLineMismatch "Power conversion system (on-board charger and DC-DC converter): a020 chg enable line mismatch";
CM_ SG_ 932 PCS_a021_hvpMia "Power conversion system (on-board charger and DC-DC converter): a021 hvp mia";
CM_ SG_ 932 PCS_a022_bmsMia "Power conversion system (on-board charger and DC-DC converter): a022 bms mia";
CM_ SG_ 932 PCS_a023_cpMia "Power conversion system (on-board charger and DC-DC converter): a023 cp mia";
CM_ SG_ 932 PCS_a024_vcfrontMia "Power conversion system (on-board charger and DC-DC converter): a024 vcfront mia";
CM_ SG_ 932 PCS_a025_cpu2Malfunction "Power conversion system (on-board charger and DC-DC converter): a025 cpu2 malfunction";
CM_ SG_ 932 PCS_a026_watchdogAlarmed "Power conversion system (on-board charger and DC-DC converter): a026 watchdog alarmed";
CM_ SG_ 932 PCS_a027_chgInsufficientCooling "Power conversion system (on-board charger and DC-DC converter): a027 chg insufficient cooling";
CM_ SG_ 932 PCS_a028_chgOutputUv "Power conversion system (on-board charger and DC-DC converter): a028 chg output uv";
CM_ SG_ 932 PCS_a029_chgPowerRationality "Power conversion system (on-board charger and DC-DC converter): a029 chg power rationality";
CM_ SG_ 932 PCS_a030_canRationality "Power conversion system (on-board charger and DC-DC converter): a030 can rationality";
CM_ SG_ 932 PCS_a031_uiMia "Power conversion system (on-board charger and DC-DC converter): a031 ui mia";
CM_ SG_ 932 PCS_a032_excessiveGridTransients "Power conversion system (on-board charger and DC-DC converter): a032 excessive grid transients detected";
CM_ SG_ 932 PCS_a033_hvBusUv "Power conversion system (on-board charger and DC-DC converter): a033 hv bus uv";
CM_ SG_ 932 PCS_a034_hvBusOv "Power conversion system (on-board charger and DC-DC converter): a034 hv bus ov";
CM_ SG_ 932 PCS_a035_lvBusUv "Power conversion system (on-board charger and DC-DC converter): a035 lv bus uv";
CM_ SG_ 932 PCS_a036_lvBusOv "Power conversion system (on-board charger and DC-DC converter): a036 lv bus ov";
CM_ SG_ 932 PCS_a037_resonantTankOc "Power conversion system (on-board charger and DC-DC converter): a037 resonant tank oc";
CM_ SG_ 932 PCS_a038_claFaulted "Power conversion system (on-board charger and DC-DC converter): a038 cla faulted";
CM_ SG_ 932 PCS_a039_sdModuleClkFault "Power conversion system (on-board charger and DC-DC converter): a039 sd module clk fault";
CM_ SG_ 932 PCS_a040_dcdcMaxPowerReached "Power conversion system (on-board charger and DC-DC converter): a040 dcdc max power reached";
CM_ SG_ 932 PCS_a041_dcdcOverTemp "Power conversion system (on-board charger and DC-DC converter): a041 dcdc over temp";
CM_ SG_ 932 PCS_a042_dcdcEnableLineMismatch "Power conversion system (on-board charger and DC-DC converter): a042 dcdc enable line mismatch";
CM_ SG_ 932 PCS_a043_hvBusPrechargeFailure "Power conversion system (on-board charger and DC-DC converter): a043 hv bus precharge failure";
CM_ SG_ 932 PCS_a044_12vSupportRegulation "Power conversion system (on-board charger and DC-DC converter): a044 12v support regulation";
CM_ SG_ 932 PCS_a045_hvBusLowImpedance "Power conversion system (on-board charger and DC-DC converter): a045 hv bus low impedance";
CM_ SG_ 932 PCS_a046_hvBusHighImpedence "Power conversion system (on-board charger and DC-DC converter): a046 hv bus high impedence";
CM_ SG_ 932 PCS_a047_bootloaderCrcMismatch "Power conversion system (on-board charger and DC-DC converter): a047 bootloader crc mismatch";
CM_ SG_ 932 PCS_a048_softwareAssertion "Power conversion system (on-board charger and DC-DC converter): a048 software assertion";
CM_ SG_ 932 PCS_a049_dcdcTempRationality "Power conversion system (on-board charger and DC-DC converter): a049 dcdc temp rationality";
CM_ SG_ 932 PCS_a050_dcdc12VsupportFaulted "Power conversion system (on-board charger and DC-DC converter): a050 dcdc12 vsupport faulted";
CM_ SG_ 932 PCS_a051_chgIntBusUv "Power conversion system (on-board charger and DC-DC converter): a051 chg int bus uv";
CM_ SG_ 932 PCS_a052_acVoltageNotPresent "Power conversion system (on-board charger and DC-DC converter): a052 ac voltage not present";
CM_ SG_ 932 PCS_a053_chgInputVDropHigh "Power conversion system (on-board charger and DC-DC converter): a053 chg input v drop high";
CM_ SG_ 932 PCS_a054_chgInputVDropTooHigh "Power conversion system (on-board charger and DC-DC converter): a054 chg input v drop too high";
CM_ SG_ 932 PCS_a055_chgLineImpedanceHigh "Power conversion system (on-board charger and DC-DC converter): a055 chg line impedance high";
CM_ SG_ 932 PCS_a056_chgLineImpedanceTooHigh "Power conversion system (on-board charger and DC-DC converter): a056 chg line impedance too high";
CM_ SG_ 932 PCS_a057_chgInputOverFreq "Power conversion system (on-board charger and DC-DC converter): a057 chg input over freq";
CM_ SG_ 932 PCS_a058_chgInputUnderFreq "Power conversion system (on-board charger and DC-DC converter): a058 chg input under freq";
CM_ SG_ 932 PCS_a059_chgInputOvRms "Power conversion system (on-board charger and DC-DC converter): a059 chg input ov rms";
CM_ SG_ 932 PCS_a060_chgInputOvPeak "Power conversion system (on-board charger and DC-DC converter): a060 chg input ov peak";
CM_ SG_ 932 PCS_a061_chgVLineRationality "Power conversion system (on-board charger and DC-DC converter): a061 chg v line rationality";
CM_ SG_ 932 PCS_a062_chgILineRationality "Power conversion system (on-board charger and DC-DC converter): a062 chg i line rationality";
CM_ SG_ 932 PCS_a063_chgVOutRationality "Power conversion system (on-board charger and DC-DC converter): a063 chg v out rationality";
CM_ SG_ 932 PCS_a064_chgIOutRationality "Power conversion system (on-board charger and DC-DC converter): a064 chg i out rationality";
CM_ SG_ 932 PCS_a065_chgPllNotLocked "Power conversion system (on-board charger and DC-DC converter): a065 chg pll not locked";
CM_ SG_ 932 PCS_a066_dcdcHvRationality "Power conversion system (on-board charger and DC-DC converter): a066 dcdc hv rationality";
CM_ SG_ 932 PCS_a067_dcdcLvRationality "Power conversion system (on-board charger and DC-DC converter): a067 dcdc lv rationality";
CM_ SG_ 932 PCS_a068_dcdcTankvRationality "Power conversion system (on-board charger and DC-DC converter): a068 dcdc tankv rationality";
CM_ SG_ 932 PCS_a069_chgPfcLineDidt "Power conversion system (on-board charger and DC-DC converter): a069 chg pfc line didt";
CM_ SG_ 932 PCS_a070_chgPfcLineDvdt "Power conversion system (on-board charger and DC-DC converter): a070 chg pfc line dvdt";
CM_ SG_ 932 PCS_a071_chgPfcILoopRationality "Power conversion system (on-board charger and DC-DC converter): a071 chg pfc i loop rationality";
CM_ SG_ 932 PCS_a072_cpu2ClaStopped "Power conversion system (on-board charger and DC-DC converter): a072 cpu2 cla stopped";
CM_ SG_ 932 PCS_a073_unexpectedAcInputVoltag "Power conversion system (on-board charger and DC-DC converter): a073 unexpected ac input voltage";
CM_ SG_ 932 PCS_a074_hvBusDischargeFailure "Power conversion system (on-board charger and DC-DC converter): a074 hv bus discharge failure";
CM_ SG_ 932 PCS_a075_hvBusDischargeTimeout "Power conversion system (on-board charger and DC-DC converter): a075 hv bus discharge timeout";
CM_ SG_ 932 PCS_a076_dcdcEnDeassertedErr "Power conversion system (on-board charger and DC-DC converter): a076 dcdc en deasserted err";
CM_ SG_ 932 PCS_a077_microGridWobbleDetected "Power conversion system (on-board charger and DC-DC converter): a077 micro grid wobble detected";
CM_ SG_ 932 PCS_a078_chgStopDcdcTooHot "Power conversion system (on-board charger and DC-DC converter): a078 chg stop dcdc too hot";
CM_ SG_ 932 PCS_a079_eepromOperationError "Power conversion system (on-board charger and DC-DC converter): a079 eeprom operation error";
CM_ SG_ 932 PCS_a080_damagedPhaseDetected "Power conversion system (on-board charger and DC-DC converter): a080 damaged phase detected";
CM_ SG_ 932 PCS_a081_dcdcPchgTimeout "Power conversion system (on-board charger and DC-DC converter): a081 dcdc pchg timeout";
CM_ SG_ 932 PCS_a082_dcdcPchgUnsafeDiVoltage "Power conversion system (on-board charger and DC-DC converter): a082 dcdc pchg unsafe di voltage";
CM_ SG_ 932 PCS_a083_triggerOdin "Signal reported by Power conversion system (on-board charger and DC-DC converter)";
CM_ SG_ 932 PCS_a084_vDropFastInParasiticDio "Power conversion system (on-board charger and DC-DC converter): a084 v drop fast in parasitic diode region";
CM_ SG_ 932 PCS_a085_dcdcFetsNotSwitching "Power conversion system (on-board charger and DC-DC converter): a085 dcdc fets not switching";
CM_ SG_ 932 PCS_a086_dcdcInsufficientCooling "Power conversion system (on-board charger and DC-DC converter): a086 dcdc insufficient cooling";
CM_ SG_ 932 PCS_a087_nvramRecordStatusError "Power conversion system (on-board charger and DC-DC converter): a087 nvram record status error";
CM_ SG_ 932 PCS_a088_gridFreqDroopDetected "Power conversion system (on-board charger and DC-DC converter): a088 grid freq droop detected";
CM_ SG_ 932 PCS_a089_hvBusDischargeIrrationa "Power conversion system (on-board charger and DC-DC converter): a089 hv bus discharge irrational";
CM_ SG_ 932 PCS_a090_expectedAcVoltageSource "Power conversion system (on-board charger and DC-DC converter): a090 expected ac voltage source missing";
CM_ SG_ 932 PCS_a091_chgIntBusRationality "Power conversion system (on-board charger and DC-DC converter): a091 chg int bus rationality";
CM_ SG_ 932 PCS_a092_chgPowerLimitedByBusRip "Power conversion system (on-board charger and DC-DC converter): a092 chg power limited by bus ripple";
CM_ SG_ 932 PCS_a093_powerRailRationality "Power conversion system (on-board charger and DC-DC converter): a093 power rail rationality";
CM_ SG_ 932 PCS_a094_pcsDcdcNeedService "Power conversion system (on-board charger and DC-DC converter): a094 pcs dcdc need service";
CM_ SG_ 932 PCS_a095_dcdcSensorlessModeActiv "Power conversion system (on-board charger and DC-DC converter): a095 dcdc sensorless mode active";
CM_ SG_ 932 PCS_a096_microGridOverLoaded "Power conversion system (on-board charger and DC-DC converter): a096 micro grid over loaded";
CM_ SG_ 932 PCS_a097_rebootPhaseDetected "Power conversion system (on-board charger and DC-DC converter): a097 reboot phase detected";
CM_ SG_ 932 PCS_a098_gridFreqDroopDetectedSi "Power conversion system (on-board charger and DC-DC converter): a098 grid freq droop detected silent";
CM_ SG_ 932 PCS_a099_microGridOverLoadedSile "Power conversion system (on-board charger and DC-DC converter): a099 micro grid over loaded silent";
CM_ SG_ 932 PCS_a100_suspectedViperChipIssue "Power conversion system (on-board charger and DC-DC converter): a100 suspected viper chip issue";
CM_ SG_ 932 PCS_a101_phMachineModelIrrationa "Power conversion system (on-board charger and DC-DC converter): a101 ph machine model irrational";
CM_ SG_ 932 PCS_a102_resetWithDCDCCmdAsserte "Power conversion system (on-board charger and DC-DC converter): a102 reset with DCDC cmd asserted";
CM_ SG_ 932 PCS_a103_pchgWithLowLvDetected "Power conversion system (on-board charger and DC-DC converter): a103 pchg with low lv detected";
CM_ SG_ 932 PCS_a104_ambientTempRationality "Power conversion system (on-board charger and DC-DC converter): a104 ambient temp rationality";
CM_ SG_ 932 PCS_a105_redundantVoltageSourceI "Power conversion system (on-board charger and DC-DC converter): a105 redundant voltage source irrational";
CM_ SG_ 932 PCS_a106_clockSourceNotFromExter "Power conversion system (on-board charger and DC-DC converter): a106 clock source not from external crystal";
CM_ SG_ 932 PCS_a107_vcPcsDCDCInterfaceMia "Power conversion system (on-board charger and DC-DC converter): a107 vc pcs DCDC interface mia";
CM_ SG_ 932 PCS_a108_misconfigurationDetecte "Power conversion system (on-board charger and DC-DC converter): a108 misconfiguration detected";
CM_ SG_ 932 PCS_a109_deltaChargingL2L3Swappe "Power conversion system (on-board charger and DC-DC converter): a109 delta charging L2 L3 swapped detected";
CM_ BO_ 612 "Power conversion system (on-board charger and DC-DC converter) message: chg line status";
CM_ SG_ 612 PCS_chgInputVoltage "RMS value of AC charger's sensed input voltage";
CM_ SG_ 612 PCS_chgLineCurrent "AC charger's sensed input line current";
CM_ SG_ 612 PCS_chgAcVoltagePresent "Indicates whether AC voltage is present on the PCS input";
CM_ SG_ 612 PCS_chgInputPower "Total AC charger input power";
CM_ SG_ 612 PCS_chgAcCurrentLimit "Maximum AC current that can be pulled from a single conductor";
CM_ BO_ 516 "Power conversion system (on-board charger and DC-DC converter) message: chg status";
CM_ SG_ 516 PCS_chgMainState "Power conversion system (on-board charger and DC-DC converter): chg main state";
CM_ SG_ 516 PCS_hvChargeStatus "Power conversion system (on-board charger and DC-DC converter): hv charge status";
CM_ SG_ 516 PCS_gridConfig "AC charger sensed grid configuration; raw 0 = signal not available (SNA)";
CM_ SG_ 516 PCS_chgPHAEnable "Indicates whether AC charger phase A is enabled";
CM_ SG_ 516 PCS_chgPHBEnable "Indicates whether AC charger phase B is enabled";
CM_ SG_ 516 PCS_hvInletConductorEnergizedAc "Power conversion system (on-board charger and DC-DC converter): hv inlet conductor energized ac";
CM_ SG_ 516 PCS_chgHighPowerActive "Power conversion system (on-board charger and DC-DC converter): chg high power active";
CM_ SG_ 516 PCS_chgPHCEnable "Indicates whether AC charger phase C is enabled";
CM_ SG_ 516 PCS_chgInstantAcPowerAvailable "Instantaneous power capability of the AC charger";
CM_ SG_ 516 PCS_chgMaxAcPowerAvailable "Maximum power capability of the AC charger; raw 255 = signal not available (SNA)";
CM_ SG_ 516 PCS_chgPHALineCurrentRequest "AC charger phase A input current command";
CM_ SG_ 516 PCS_chgPHBLineCurrentRequest "AC charger phase B input current command";
CM_ SG_ 516 PCS_chgPHCLineCurrentRequest "AC charger phase B input current command";
CM_ SG_ 516 PCS_chgPwmEnableLine "Sensed state of the charger PWM enable hardline";
CM_ SG_ 516 PCS_chargeShutdownRequest "Power conversion system (on-board charger and DC-DC converter): charge shutdown request";
CM_ SG_ 516 PCS_hwVariantType "Hardware variant of AC charger; raw 3 = signal not available (SNA)";
CM_ BO_ 692 "Power conversion system (on-board charger and DC-DC converter) message: dcdc rail status";
CM_ SG_ 692 PCS_dcdcLvBusVolt "DCDC's sensed LV bus voltage";
CM_ SG_ 692 PCS_dcdcHvBusVolt "DCDC's sensed HV bus voltage";
CM_ SG_ 692 PCS_dcdcLvOutputCurrent "DCDC's computed LV output current";
CM_ BO_ 548 "Power conversion system (on-board charger and DC-DC converter) message: dcdc status";
CM_ SG_ 548 PCS_dcdcPrechargeStatus "Status of DCDC HV bus precharge";
CM_ SG_ 548 PCS_dcdcLvSupportStatus "Status of DCDC LV support";
CM_ SG_ 548 PCS_dcdcHvBusDischargeStatus "Power conversion system (on-board charger and DC-DC converter): dcdc hv bus discharge status";
CM_ SG_ 548 PCS_coldSleepAllowed "Power conversion system (on-board charger and DC-DC converter): cold sleep allowed";
CM_ SG_ 548 PCS_dcdcPchgHVBusLowRDetected "Power conversion system (on-board charger and DC-DC converter): dcdc pchg HV bus low r detected";
CM_ SG_ 548 PCS_dcdcSubState "Substate of DCDC state machine";
CM_ SG_ 548 PCS_dcdcFaulted "Whether the DCDC is in faulted state";
CM_ SG_ 548 PCS_okToBePowerCycled "Power conversion system (on-board charger and DC-DC converter): ok to be power cycled";
CM_ SG_ 548 PCS_dcdcOutputIsLimited "Whether the DCDC's output is current limiting";
CM_ SG_ 548 PCS_dcdcMaxOutputCurrentAllowed "Maximum LV output current capability of DCDC based on operating point";
CM_ SG_ 548 PCS_dcdcPrechargeRtyCnt "Power conversion system (on-board charger and DC-DC converter): dcdc precharge rty cnt";
CM_ SG_ 548 PCS_dcdcLvSupportRtyCnt "Power conversion system (on-board charger and DC-DC converter): dcdc lv support rty cnt";
CM_ SG_ 548 PCS_dcdcDischargeRtyCnt "Power conversion system (on-board charger and DC-DC converter): dcdc discharge rty cnt";
CM_ SG_ 548 PCS_dcdcPwmEnableLine "Sensed state of the DCDC PWM enable hardline";
CM_ SG_ 548 PCS_dcdcSupportingFixedLvTarget "Whether DCDC is running LV support at a fixed voltage target";
CM_ SG_ 548 PCS_ecuLogUploadRequest "Power conversion system (on-board charger and DC-DC converter): ecu log upload request";
CM_ SG_ 548 PCS_dcdcPrechargeRestartCnt "Power conversion system (on-board charger and DC-DC converter): dcdc precharge restart cnt";
CM_ SG_ 548 PCS_dcdcInitialPrechargeSubState "Power conversion system (on-board charger and DC-DC converter): dcdc initial precharge sub state";
CM_ BO_ 964 "Power conversion system (on-board charger and DC-DC converter) message: info";
CM_ SG_ 964 PCS_infoIndex "Power conversion system (on-board charger and DC-DC converter): info index";
CM_ SG_ 964 PCS_buildType "Power conversion system (on-board charger and DC-DC converter): build type";
CM_ SG_ 964 PCS_buildConfigId "Power conversion system (on-board charger and DC-DC converter): build config id";
CM_ SG_ 964 PCS_hardwareId "Power conversion system (on-board charger and DC-DC converter): hardware id";
CM_ SG_ 964 PCS_componentId "Power conversion system (on-board charger and DC-DC converter): component id";
CM_ SG_ 964 PCS_pcbaId "PCBA ID portion of component hardware ID as reported by application";
CM_ SG_ 964 PCS_assemblyId "Power conversion system (on-board charger and DC-DC converter): assembly id";
CM_ SG_ 964 PCS_usageId "Usage ID portion of component hardware ID as reported by application";
CM_ SG_ 964 PCS_subUsageId "Sub-usage ID portion of component hardware ID as reported by application";
CM_ SG_ 964 PCS_platformType "Power conversion system (on-board charger and DC-DC converter): platform type";
CM_ SG_ 964 PCS_appCrc "Power conversion system (on-board charger and DC-DC converter): app crc";
CM_ SG_ 964 PCS_cpu2AppCrc "Power conversion system (on-board charger and DC-DC converter): cpu2 app crc";
CM_ SG_ 964 PCS_appGitHash "Power conversion system (on-board charger and DC-DC converter): app git hash";
CM_ SG_ 964 PCS_bootGitHash "Power conversion system (on-board charger and DC-DC converter): boot git hash";
CM_ SG_ 964 PCS_bootUdsProtoVersion "Power conversion system (on-board charger and DC-DC converter): boot uds proto version";
CM_ SG_ 964 PCS_bootCrc "Power conversion system (on-board charger and DC-DC converter): boot crc";
CM_ BO_ 708 "Power conversion system (on-board charger and DC-DC converter) message: logging";
CM_ SG_ 708 PCS_logMessageSelect "Power conversion system (on-board charger and DC-DC converter): log message select";
CM_ SG_ 708 PCS_chgPhAInputIrms "AC charger phase A's sensed RMS input current";
CM_ SG_ 708 PCS_chgPhAIntBusV "AC charger phase A's sensed intermediate bus voltage";
CM_ SG_ 708 PCS_chgPhAIntBusVTarget "AC charger phase A's intermediate bus voltage target";
CM_ SG_ 708 PCS_chgPhAOutputI "AC charger phase A sensed output current";
CM_ SG_ 708 PCS_chgPhAInputCurrentLimitReaso "Provides the reason behind the input AC charging current limit for phase A";
CM_ SG_ 708 PCS_chgPhBInputIrms "AC charger phase B's sensed RMS input current";
CM_ SG_ 708 PCS_chgPhBIntBusV "AC charger phase B's sensed intermediate bus voltage";
CM_ SG_ 708 PCS_chgPhBIntBusVTarget "AC charger phase B's intermediate bus voltage target";
CM_ SG_ 708 PCS_chgPhBOutputI "AC charger phase B sensed output current";
CM_ SG_ 708 PCS_chgPhBInputCurrentLimitReaso "Provides the reason behind the input AC charging current limit for phase B";
CM_ SG_ 708 PCS_chgPhCInputIrms "AC charger phase C's sensed RMS input current";
CM_ SG_ 708 PCS_chgPhCIntBusV "AC charger phase C's sensed intermediate bus voltage";
CM_ SG_ 708 PCS_chgPhCIntBusVTarget "AC charger phase C's intermediate bus voltage target";
CM_ SG_ 708 PCS_chgPhCOutputI "AC charger phase C sensed output current";
CM_ SG_ 708 PCS_chgPhCInputCurrentLimitReaso "Provides the reason behind the input AC charging current limit for phase C";
CM_ SG_ 708 PCS_chgInputL1NVrms "AC charger's sensed AC RMS voltage of L1-N voltage source";
CM_ SG_ 708 PCS_chgInputL2NVrms "AC charger's sensed AC RMS voltage of L2-N voltage source";
CM_ SG_ 708 PCS_chgInputL3NVrms "AC charger's sensed AC RMS voltage of L3-N voltage source";
CM_ SG_ 708 PCS_chgInputL1L2Vrms "AC charger's sensed input frequency of L2-N voltage source";
CM_ SG_ 708 PCS_chgInputNGVrms "AC charger's sensed AC RMS voltage of N-G voltage source";
CM_ SG_ 708 PCS_chgInputFrequencyL1N "AC charger's sensed input frequency of L1-N voltage source";
CM_ SG_ 708 PCS_chgInputFrequencyL2N "AC charger's sensed input frequency of L2-N voltage source";
CM_ SG_ 708 PCS_chgInputFrequencyL3N "AC charger's sensed input frequency of L3-N voltage source";
CM_ SG_ 708 PCS_chgInternalPhaseConfig "Internal phase configuration of the AC charger (three phase vs. single phase); raw 0 = signal not available (SNA)";
CM_ SG_ 708 PCS_chgPhasesPriority "AC charger phase manager's priority logic for enabling phases in single phase PCS variant";
CM_ SG_ 708 PCS_chgOutputV "Sensed output voltage of AC charger";
CM_ SG_ 708 PCS_chgPhAState "State of AC charger phase A";
CM_ SG_ 708 PCS_chgPhBState "State of AC charger phase B";
CM_ SG_ 708 PCS_chgPhCState "State of AC charger phase C";
CM_ SG_ 708 PCS_chgPhALastShutdownReason "Last reason for shutting down AC charger phase A";
CM_ SG_ 708 PCS_chgPhBLastShutdownReason "Last reason for shutting down AC charger phase B";
CM_ SG_ 708 PCS_chgPhCLastShutdownReason "Last reason for shutting down AC charger phase C";
CM_ SG_ 708 PCS_chgPhARetryCount "AC charger phase A number of retries used during the current charge session";
CM_ SG_ 708 PCS_chgPhBRetryCount "AC charger phase B number of retries used during the current charge session";
CM_ SG_ 708 PCS_chgPhCRetryCount "AC charger phase C number of retries used during the current charge session";
CM_ SG_ 708 PCS_chgRetryCount "AC charger number of system level retries used during the current charge session";
CM_ SG_ 708 PCS_chgPhManCurrentToDist "Power conversion system (on-board charger and DC-DC converter): chg ph man current to dist";
CM_ SG_ 708 PCS_chgL1NPllLocked "Power conversion system (on-board charger and DC-DC converter): chg L1 n pll locked";
CM_ SG_ 708 PCS_chgL2NPllLocked "Power conversion system (on-board charger and DC-DC converter): chg L2 n pll locked";
CM_ SG_ 708 PCS_chgL3NPllLocked "Power conversion system (on-board charger and DC-DC converter): chg L3 n pll locked";
CM_ SG_ 708 PCS_chgL1L2PllLocked "Power conversion system (on-board charger and DC-DC converter): chg L1 L2 pll locked";
CM_ SG_ 708 PCS_chgNgPllLocked "Power conversion system (on-board charger and DC-DC converter): chg ng pll locked";
CM_ SG_ 708 PCS_chgPhManOptimalPhsToUse "Power conversion system (on-board charger and DC-DC converter): chg ph man optimal phs to use";
CM_ SG_ 708 PCS_chg5VL1Enable "Power conversion system (on-board charger and DC-DC converter): chg5 VL1 enable";
CM_ SG_ 708 PCS_dcdcMaxLvOutputCurrent "Overall maxmum LV output current capability of DCDC";
CM_ SG_ 708 PCS_dcdcCurrentLimit "Power conversion system (on-board charger and DC-DC converter): dcdc current limit";
CM_ SG_ 708 PCS_dcdcLvOutputCurrentTempLimit "Maximum LV output current capability of DCDC based on thermals";
CM_ SG_ 708 PCS_dcdcLvOutputCurrentFiltered "DCDC's filtered LV output current";
CM_ SG_ 708 PCS_dcdcUnifiedCommand "Power conversion system (on-board charger and DC-DC converter): dcdc unified command";
CM_ SG_ 708 PCS_dcdcCLAControllerOutput "Power conversion system (on-board charger and DC-DC converter): dcdc CLA controller output";
CM_ SG_ 708 PCS_dcdcTankVoltage "Power conversion system (on-board charger and DC-DC converter): dcdc tank voltage; raw 1024 = signal not available (SNA)";
CM_ SG_ 708 PCS_dcdcTankVoltageTarget "Power conversion system (on-board charger and DC-DC converter): dcdc tank voltage target";
CM_ SG_ 708 PCS_dcdcClaCurrentFreq "Power conversion system (on-board charger and DC-DC converter): dcdc cla current freq";
CM_ SG_ 708 PCS_dcdcTCommMeasured "Power conversion system (on-board charger and DC-DC converter): dcdc t comm measured";
CM_ SG_ 708 PCS_dcdcShortTimeUs "Power conversion system (on-board charger and DC-DC converter): dcdc short time us";
CM_ SG_ 708 PCS_dcdcHalfPeriodUs "Power conversion system (on-board charger and DC-DC converter): dcdc half period us";
CM_ SG_ 708 PCS_dcdcLvBusVoltTargetWithOffse "LV support Voltage target with Feed-forward offset";
CM_ SG_ 708 PCS_cpu2BootState "Power conversion system (on-board charger and DC-DC converter): cpu2 boot state";
CM_ SG_ 708 PCS_acChargeSelfTestState "Power conversion system (on-board charger and DC-DC converter): ac charge self test state";
CM_ SG_ 708 PCS_1V5Min10s "Power conversion system (on-board charger and DC-DC converter): 1 V5 min10s";
CM_ SG_ 708 PCS_1V5Max10s "Power conversion system (on-board charger and DC-DC converter): 1 V5 max10s";
CM_ SG_ 708 PCS_1V2Min10s "Power conversion system (on-board charger and DC-DC converter): 1 V2 min10s";
CM_ SG_ 708 PCS_1V2Max10s "Power conversion system (on-board charger and DC-DC converter): 1 V2 max10s";
CM_ SG_ 708 PCS_5VNMax10s "Power conversion system (on-board charger and DC-DC converter): 5 VN max10s";
CM_ SG_ 708 PCS_chgPhAIntBusVMin10s "AC charger phase A's minimum sensed intermediate bus voltage over the last ten seconds";
CM_ SG_ 708 PCS_chgPhAIntBusVMax10s "AC charger phase A's maximum sensed intermediate bus voltage over the last ten seconds";
CM_ SG_ 708 PCS_chgPhAPchgVoltDeltaMax10s "AC charger phase A maximum sensed voltage delta between line and intermediate bus in the last 10 seconds during SCR precharge";
CM_ SG_ 708 PCS_chgPhALifetimekWh "Lifetime total energy throughput of AC charger phase A";
CM_ SG_ 708 PCS_chgPhATransientRetryCount "AC charger phase A number of transient retries used during the current charge session";
CM_ SG_ 708 PCS_chgPhBIntBusVMin10s "AC charger phase B's minimum sensed intermediate bus voltage over the last ten seconds";
CM_ SG_ 708 PCS_chgPhBIntBusVMax10s "AC charger phase B's maximum sensed intermediate bus voltage over the last ten seconds";
CM_ SG_ 708 PCS_chgPhBPchgVoltDeltaMax10s "AC charger phase B maximum sensed voltage delta between line and intermediate bus in the last 10 seconds during SCR precharge";
CM_ SG_ 708 PCS_chgPhBLifetimekWh "Lifetime total energy throughput of AC charger phase B";
CM_ SG_ 708 PCS_chgPhBTransientRetryCount "AC charger phase B number of transient retries used during the current charge session";
CM_ SG_ 708 PCS_chgPhCIntBusVMin10s "AC charger phase C's minimum sensed intermediate bus voltage over the last ten seconds";
CM_ SG_ 708 PCS_chgPhCIntBusVMax10s "AC charger phase C's maximum sensed intermediate bus voltage over the last ten seconds";
CM_ SG_ 708 PCS_chgPhCPchgVoltDeltaMax10s "AC charger phase C maximum sensed voltage delta between line and intermediate bus in the last 10 seconds during SCR precharge";
CM_ SG_ 708 PCS_chgPhCLifetimekWh "Lifetime total energy throughput of AC charger phase C";
CM_ SG_ 708 PCS_chgPhCTransientRetryCount "AC charger phase C number of transient retries used during the current charge session";
CM_ SG_ 708 PCS_chgPhANoFlowBucket "Power conversion system (on-board charger and DC-DC converter): chg ph a no flow bucket";
CM_ SG_ 708 PCS_chgPhBNoFlowBucket "Power conversion system (on-board charger and DC-DC converter): chg ph b no flow bucket";
CM_ SG_ 708 PCS_chgPhCNoFlowBucket "Power conversion system (on-board charger and DC-DC converter): chg ph c no flow bucket";
CM_ SG_ 708 PCS_chgCurrentSensorOutOfBandUs "Power conversion system (on-board charger and DC-DC converter): chg current sensor out of band us";
CM_ SG_ 708 PCS_chgAcpwHeartbeatState "A signal to indicate if PCS detects the heartbeat signature from AC Power Wall";
CM_ SG_ 708 PCS_chgKwhLostByFreqDroop "Power conversion system (on-board charger and DC-DC converter): chg kwh lost by freq droop";
CM_ SG_ 708 PCS_chgReqKwhLostByFreqDroop "Power conversion system (on-board charger and DC-DC converter): chg req kwh lost by freq droop";
CM_ SG_ 708 PCS_dcdcLvSupportLifetimekWh "Lifetime energy throughput of DCDC LV support mode";
CM_ SG_ 708 PCS_chgPwmEnableLineErrorCount "Power conversion system (on-board charger and DC-DC converter): chg pwm enable line error count";
CM_ SG_ 708 PCS_dcdcPwmEnableLineErrorCount "Number of deassertions detected for DCDC PWM enable line";
CM_ SG_ 708 PCS_numAlertsSet "Power conversion system (on-board charger and DC-DC converter): num alerts set";
CM_ SG_ 708 PCS_dcdcPchgStartLvBusVolt "Sensed LV bus votlage when beginning DCDC precharge";
CM_ SG_ 708 PCS_dcdcPchgStartHvBusVolt "Sensed HV bus votlage when beginning DCDC precharge";
CM_ SG_ 708 PCS_processorDieIdLot "Power conversion system (on-board charger and DC-DC converter): processor die id lot";
CM_ SG_ 708 PCS_processorDieIdWafer "Power conversion system (on-board charger and DC-DC converter): processor die id wafer";
CM_ SG_ 708 PCS_processorDieIdX "Power conversion system (on-board charger and DC-DC converter): processor die id x";
CM_ SG_ 708 PCS_processorDieIdY "Power conversion system (on-board charger and DC-DC converter): processor die id y";
CM_ BO_ 676 "Power conversion system (on-board charger and DC-DC converter) message: thermal status";
CM_ SG_ 676 PCS_chgPhATemp "Sensed temperature of AC charger phase A; raw 1025 = signal not available (SNA)";
CM_ SG_ 676 PCS_chgPhBTemp "Sensed temperature of AC charger phase B; raw 1025 = signal not available (SNA)";
CM_ SG_ 676 PCS_chgPhCTemp "Sensed temperature of AC charger phase C; raw 1025 = signal not available (SNA)";
CM_ SG_ 676 PCS_dcdcTemp "Sensed temperature of DCDC; raw 1025 = signal not available (SNA)";
CM_ SG_ 676 PCS_ambientTemp "Ambient temperature sensed by the PCS; raw 1025 = signal not available (SNA)";
CM_ SG_ 676 PCS_dcdcBusbarTemp "Sensed temperature of DCDC busbar; raw 511 = signal not available (SNA)";
CM_ BO_ 1317 "PMF ECU message: alert log";
CM_ SG_ 1317 PMF_alertID "PMF ECU: alert ID";
CM_ SG_ 1317 PMF_alertState "PMF ECU: alert state";
CM_ SG_ 1317 PMF_a001_w0 "PMF ECU: a001 w0";
CM_ SG_ 1317 PMF_a001_w1 "PMF ECU: a001 w1";
CM_ SG_ 1317 PMF_a001_w2 "PMF ECU: a001 w2";
CM_ SG_ 1317 PMF_a002_torqueAverage "PMF ECU: a002 torque average";
CM_ SG_ 1317 PMF_a002_torqueWindow "PMF ECU: a002 torque window";
CM_ SG_ 1317 PMF_a002_torqueMeasured "PMF ECU: a002 torque measured; raw 4096 = signal not available (SNA)";
CM_ SG_ 1317 PMF_a002_torqueAccelAverage "PMF ECU: a002 torque accel average; raw 4096 = signal not available (SNA)";
CM_ SG_ 1317 PMF_a002_torqueAccelWindow "PMF ECU: a002 torque accel window; raw 4096 = signal not available (SNA)";
CM_ SG_ 1317 PMF_a003_reverseGear "PMF ECU: a003 reverse gear";
CM_ SG_ 1317 PMF_a003_pedalPos "PMF ECU: a003 pedal pos";
CM_ SG_ 1317 PMF_a003_zeroPointPedal "PMF ECU: a003 zero point pedal";
CM_ SG_ 1317 PMF_a004_torqueAverage "PMF ECU: a004 torque average";
CM_ SG_ 1317 PMF_a004_torqueWindow "PMF ECU: a004 torque window";
CM_ SG_ 1317 PMF_a004_torqueMeasured "PMF ECU: a004 torque measured; raw 4096 = signal not available (SNA)";
CM_ SG_ 1317 PMF_a004_torqueDecelAverage "PMF ECU: a004 torque decel average; raw 4096 = signal not available (SNA)";
CM_ SG_ 1317 PMF_a004_torqueDecelWindow "PMF ECU: a004 torque decel window; raw 4096 = signal not available (SNA)";
CM_ SG_ 1317 PMF_a005_torqueReason "PMF ECU: a005 torque reason";
CM_ SG_ 1317 PMF_a005_torqueMeasured "PMF ECU: a005 torque measured; raw 4096 = signal not available (SNA)";
CM_ SG_ 1317 PMF_a005_iDQmagnitude "PMF ECU: a005 i d qmagnitude";
CM_ SG_ 1317 PMF_a006_torqueActual "PMF ECU: a006 torque actual; raw 4096 = signal not available (SNA)";
CM_ SG_ 1317 PMF_a006_motorRPM "PMF ECU: a006 motor RPM";
CM_ SG_ 1317 PMF_a006_torqueMeasured "PMF ECU: a006 torque measured; raw 4096 = signal not available (SNA)";
CM_ SG_ 1317 PMF_a010_messageId "PMF ECU: a010 message id";
CM_ SG_ 1317 PMF_a010_DI_status "PMF ECU: a010 DI status";
CM_ SG_ 1317 PMF_a010_DI_torque "PMF ECU: a010 DI torque";
CM_ SG_ 1317 PMF_a010_DI_slaveCommand "PMF ECU: a010 DI slave command";
CM_ SG_ 1317 PMF_a010_DI_locStatus "PMF ECU: a010 DI loc status";
CM_ SG_ 1317 PMF_a010_DI_speed "PMF ECU: a010 DI speed";
CM_ SG_ 1317 PMF_a010_DI_systemStatus "PMF ECU: a010 DI system status";
CM_ SG_ 1317 PMF_a010_DI_chassisControl "PMF ECU: a010 DI chassis control";
CM_ SG_ 1317 PMF_a010_DI_chassisControl2 "PMF ECU: a010 DI chassis control2";
CM_ SG_ 1317 PMF_a010_vdcLeft "PMF ECU: a010 vdc left";
CM_ SG_ 1317 PMF_a010_vdcRight "PMF ECU: a010 vdc right";
CM_ SG_ 1317 PMF_a010_DI_vehicleEstimates "PMF ECU: a010 DI vehicle estimates";
CM_ SG_ 1317 PMF_a010_DI_brakeCommand "PMF ECU: a010 DI brake command";
CM_ SG_ 1317 PMF_a010_DI_difCommand "PMF ECU: a010 DI dif command";
CM_ SG_ 1317 PMF_a010_DI_dirCommand "PMF ECU: a010 DI dir command";
CM_ SG_ 1317 PMF_a010_DI_dirVehicle "PMF ECU: a010 DI dir vehicle";
CM_ SG_ 1317 PMF_a010_DI_locStatus2 "PMF ECU: a010 DI loc status2";
CM_ SG_ 1317 PMF_a011_Ia "PMF ECU: a011 ia";
CM_ SG_ 1317 PMF_a011_Ib "PMF ECU: a011 ib";
CM_ SG_ 1317 PMF_a011_currentVref "PMF ECU: a011 current vref";
CM_ SG_ 1317 PMF_a011_badPhaseAsample "PMF ECU: a011 bad phase asample";
CM_ SG_ 1317 PMF_a011_badPhaseBsample "PMF ECU: a011 bad phase bsample";
CM_ SG_ 1317 PMF_a011_sampleFreeze "PMF ECU: a011 sample freeze";
CM_ SG_ 1317 PMF_a012_canID "PMF ECU: a012 can ID";
CM_ SG_ 1317 PMF_a012_errorType "PMF ECU: a012 error type";
CM_ SG_ 1317 PMF_a012_badValue1 "PMF ECU: a012 bad value1";
CM_ SG_ 1317 PMF_a012_badValue2 "PMF ECU: a012 bad value2";
CM_ SG_ 1317 PMF_a013_mailboxID "PMF ECU: a013 mailbox ID";
CM_ SG_ 1317 PMF_a013_canID "PMF ECU: a013 can ID";
CM_ SG_ 1317 PMF_a013_errorType "PMF ECU: a013 error type";
CM_ SG_ 1317 PMF_a017_EPBL_status "PMF ECU: a017 EPBL status";
CM_ SG_ 1317 PMF_a017_EPBR_status "PMF ECU: a017 EPBR status";
CM_ SG_ 1317 PMF_a018_w0 "PMF ECU: a018 w0";
CM_ SG_ 1317 PMF_a018_w1 "PMF ECU: a018 w1";
CM_ SG_ 1317 PMF_a018_w2 "PMF ECU: a018 w2";
CM_ SG_ 1317 PMF_a019_statorTemp1 "PMF ECU: a019 stator temp1";
CM_ SG_ 1317 PMF_a019_statorTslope1 "PMF ECU: a019 stator tslope1";
CM_ SG_ 1317 PMF_a025_sccReset "PMF ECU: a025 scc reset";
CM_ SG_ 1317 PMF_a025_hibernate "PMF ECU: a025 hibernate";
CM_ SG_ 1317 PMF_a025_hwBist "PMF ECU: a025 hw bist";
CM_ SG_ 1317 PMF_a025_nmiWatchdog "PMF ECU: a025 nmi watchdog";
CM_ SG_ 1317 PMF_a025_watchdog "PMF ECU: a025 watchdog";
CM_ SG_ 1317 PMF_a025_clockFailNmi "PMF ECU: a025 clock fail nmi";
CM_ SG_ 1317 PMF_a025_ramUncErrorNmi "PMF ECU: a025 ram unc error nmi";
CM_ SG_ 1317 PMF_a025_flashUncErrorNmi "PMF ECU: a025 flash unc error nmi";
CM_ SG_ 1317 PMF_a025_cpu1signMismatchNmi "PMF ECU: a025 cpu1sign mismatch nmi";
CM_ SG_ 1317 PMF_a025_cpu2signMismatchNmi "PMF ECU: a025 cpu2sign mismatch nmi";
CM_ SG_ 1317 PMF_a025_pieVectErrorNmi "PMF ECU: a025 pie vect error nmi";
CM_ SG_ 1317 PMF_a025_sysDbgNmi "PMF ECU: a025 sys dbg nmi";
CM_ SG_ 1317 PMF_a025_rlNmi "PMF ECU: a025 rl nmi";
CM_ SG_ 1317 PMF_a025_ovfNmi "PMF ECU: a025 ovf nmi";
CM_ SG_ 1317 PMF_a025_possibleSafetyICReset "PMF ECU: a025 possible safety IC reset";
CM_ SG_ 1317 PMF_a025_powerOnReset "PMF ECU: a025 power on reset";
CM_ SG_ 1317 PMF_a025_watchdogTimer0 "PMF ECU: a025 watchdog timer0";
CM_ SG_ 1317 PMF_a025_watchdogTimer1 "PMF ECU: a025 watchdog timer1";
CM_ SG_ 1317 PMF_a025_watchdogTimer2 "PMF ECU: a025 watchdog timer2";
CM_ SG_ 1317 PMF_a025_watchdogTimer3 "PMF ECU: a025 watchdog timer3";
CM_ SG_ 1317 PMF_a025_warmResetReq "PMF ECU: a025 warm reset req";
CM_ SG_ 1317 PMF_a025_externalPadReset "PMF ECU: a025 external pad reset";
CM_ SG_ 1317 PMF_a025_hwSecModuleWatchdogTime "PMF ECU: a025 hw sec module watchdog timer";
CM_ SG_ 1317 PMF_a025_debugReset "PMF ECU: a025 debug reset";
CM_ SG_ 1317 PMF_a025_tempSense0 "PMF ECU: a025 temp sense0";
CM_ SG_ 1317 PMF_a025_tempSense1 "PMF ECU: a025 temp sense1";
CM_ SG_ 1317 PMF_a026_reason "PMF ECU: a026 reason";
CM_ SG_ 1317 PMF_a026_isrCount20kHz "PMF ECU: a026 isr count20k hz";
CM_ SG_ 1317 PMF_a026_isrCount1kHz "PMF ECU: a026 isr count1k hz";
CM_ SG_ 1317 PMF_a026_switchingActive "PMF ECU: a026 switching active";
CM_ SG_ 1317 PMF_a026_systemStackOvf "PMF ECU: a026 system stack ovf";
CM_ SG_ 1317 PMF_a026_controlStackOvf "PMF ECU: a026 control stack ovf";
CM_ SG_ 1317 PMF_a026_idleStackOvf "PMF ECU: a026 idle stack ovf";
CM_ SG_ 1317 PMF_a026_eepStackOvf "PMF ECU: a026 eep stack ovf";
CM_ SG_ 1317 PMF_a026_immStackOvf "PMF ECU: a026 imm stack ovf";
CM_ SG_ 1317 PMF_a026_xdcErrorIdMSW "PMF ECU: a026 xdc error id MSW";
CM_ SG_ 1317 PMF_a026_xdcErrorArg1 "PMF ECU: a026 xdc error arg1";
CM_ SG_ 1317 PMF_a032_w0 "PMF ECU: a032 w0";
CM_ SG_ 1317 PMF_a032_w1 "PMF ECU: a032 w1";
CM_ SG_ 1317 PMF_a032_w2 "PMF ECU: a032 w2";
CM_ SG_ 1317 PMF_a033_state "PMF ECU: a033 state";
CM_ SG_ 1317 PMF_a033_failReason "PMF ECU: a033 fail reason";
CM_ SG_ 1317 PMF_a033_DSADC_Ia "PMF ECU: a033 DSADC ia";
CM_ SG_ 1317 PMF_a033_DSADC_Ib "PMF ECU: a033 DSADC ib";
CM_ SG_ 1317 PMF_a036_timeSinceTxHWI "PMF ECU: a036 time since tx HWI";
CM_ SG_ 1317 PMF_a036_timeSinceRxHWI "PMF ECU: a036 time since rx HWI";
CM_ SG_ 1317 PMF_a036_timeSince100HzTxSWI "PMF ECU: a036 time since100 hz tx SWI";
CM_ SG_ 1317 PMF_a036_timeSince1kHzCLK "PMF ECU: a036 time since1k hz CLK";
CM_ SG_ 1317 PMF_a036_timeSince1kHzSWI "PMF ECU: a036 time since1k hz SWI";
CM_ SG_ 1317 PMF_a036_timeSinceIdle "PMF ECU: a036 time since idle";
CM_ SG_ 1317 PMF_a036_ovfStackId "PMF ECU: a036 ovf stack id; raw 15 = signal not available (SNA)";
CM_ SG_ 1317 PMF_a036_inTxISR "PMF ECU: a036 in tx ISR";
CM_ SG_ 1317 PMF_a036_inTxHWI "PMF ECU: a036 in tx HWI";
CM_ SG_ 1317 PMF_a036_inRxHWI "PMF ECU: a036 in rx HWI";
CM_ SG_ 1317 PMF_a036_in1kHzSWI "PMF ECU: a036 in1k hz SWI";
CM_ SG_ 1317 PMF_a036_in1kHzCLK "PMF ECU: a036 in1k hz CLK";
CM_ SG_ 1317 PMF_a036_in100HzCLK "PMF ECU: a036 in100 hz CLK";
CM_ SG_ 1317 PMF_a036_in10HzCLK "PMF ECU: a036 in10 hz CLK";
CM_ SG_ 1317 PMF_a036_in1HzCLK "PMF ECU: a036 in1 hz CLK";
CM_ SG_ 1317 PMF_a037_hvpFaults "PMF ECU: a037 hvp faults";
CM_ SG_ 1317 PMF_a039_DIS_status "PMF ECU: a039 DIS status";
CM_ SG_ 1317 PMF_a039_DIS_torque "PMF ECU: a039 DIS torque";
CM_ SG_ 1317 PMF_a039_messageId "PMF ECU: a039 message id";
CM_ SG_ 1317 PMF_a040_PM_state "PMF ECU: a040 PM state";
CM_ SG_ 1317 PMF_a040_messageId "PMF ECU: a040 message id";
CM_ SG_ 1317 PMF_a040_PM_locState "PMF ECU: a040 PM loc state";
CM_ SG_ 1317 PMF_a042_GTW_carConfig "PMF ECU: a042 GTW car config";
CM_ SG_ 1317 PMF_a042_GTW_time "PMF ECU: a042 GTW time";
CM_ SG_ 1317 PMF_a042_GTW_drivetrainType "PMF ECU: a042 GTW drivetrain type";
CM_ SG_ 1317 PMF_a042_expectedPerformanceCfg "PMF ECU: a042 expected performance cfg";
CM_ SG_ 1317 PMF_a042_gearControl "PMF ECU: a042 gear control";
CM_ SG_ 1317 PMF_a053_LVPowerState "PMF ECU: a053 LV power state";
CM_ SG_ 1317 PMF_a053_coolant "PMF ECU: a053 coolant";
CM_ SG_ 1317 PMF_a053_vcleftSwitchStatus "PMF ECU: a053 vcleft switch status";
CM_ SG_ 1317 PMF_a053_restraintStatus "PMF ECU: a053 restraint status";
CM_ SG_ 1317 PMF_a053_sensors "PMF ECU: a053 sensors";
CM_ SG_ 1317 PMF_a054_uiPowertrainControl "PMF ECU: a054 ui powertrain control";
CM_ SG_ 1317 PMF_a054_uiChassisControl "PMF ECU: a054 ui chassis control";
CM_ SG_ 1317 PMF_a054_uiCruiseControl "PMF ECU: a054 ui cruise control";
CM_ SG_ 1317 PMF_a054_uiTrackModeSettings "PMF ECU: a054 ui track mode settings";
CM_ SG_ 1317 PMF_a054_uiTPMSRCPSetting "PMF ECU: a054 ui TPMSRCP setting";
CM_ SG_ 1317 PMF_a055_motorRPM "PMF ECU: a055 motor RPM";
CM_ SG_ 1317 PMF_a055_phaseAngle "PMF ECU: a055 phase angle";
CM_ SG_ 1317 PMF_a055_commonGain "PMF ECU: a055 common gain";
CM_ SG_ 1317 PMF_a055_notReady "PMF ECU: a055 not ready";
CM_ SG_ 1317 PMF_a055_noCarrier "PMF ECU: a055 no carrier";
CM_ SG_ 1317 PMF_a055_phaseOutOfSpec "PMF ECU: a055 phase out of spec";
CM_ SG_ 1317 PMF_a055_diElecAngleMismatch "PMF ECU: a055 di elec angle mismatch";
CM_ SG_ 1317 PMF_a055_diSpeedMismatch "PMF ECU: a055 di speed mismatch";
CM_ SG_ 1317 PMF_a055_claMIA "PMF ECU: a055 cla MIA";
CM_ SG_ 1317 PMF_a055_diMIA "PMF ECU: a055 di MIA";
CM_ SG_ 1317 PMF_a055_diElecAngleMismatchWarn "PMF ECU: a055 di elec angle mismatch warn";
CM_ SG_ 1317 PMF_a056_mailboxID "PMF ECU: a056 mailbox ID";
CM_ SG_ 1317 PMF_a056_canID "PMF ECU: a056 can ID";
CM_ SG_ 1317 PMF_a056_errorType "PMF ECU: a056 error type";
CM_ SG_ 1317 PMF_a057_canID "PMF ECU: a057 can ID";
CM_ SG_ 1317 PMF_a057_errorType "PMF ECU: a057 error type";
CM_ SG_ 1317 PMF_a057_badValue1 "PMF ECU: a057 bad value1";
CM_ SG_ 1317 PMF_a057_badValue2 "PMF ECU: a057 bad value2";
CM_ SG_ 1317 PMF_a058_hvilCurrent "PMF ECU: a058 hvil current";
CM_ SG_ 1317 PMF_a061_diIpcVersion "PMF ECU: a061 di ipc version";
CM_ SG_ 1317 PMF_a061_pmIpcVersion "PMF ECU: a061 pm ipc version";
CM_ SG_ 1317 PMF_a062_address "PMF ECU: a062 address";
CM_ SG_ 1317 PMF_a062_errorType "PMF ECU: a062 error type";
CM_ SG_ 1317 PMF_a064_interventionType "PMF ECU: a064 intervention type";
CM_ SG_ 1317 PMF_a064_torqueCmdState "PMF ECU: a064 torque cmd state; raw 0 = signal not available (SNA)";
CM_ SG_ 1317 PMF_a064_shortDetectedByDI "PMF ECU: a064 short detected by DI";
CM_ SG_ 1317 PMF_a064_UI_stoppingMode "PMF ECU: a064 UI stopping mode";
CM_ SG_ 1317 PMF_a064_diCrsState "PMF ECU: a064 di crs state";
CM_ SG_ 1317 PMF_a064_pmCrsState "PMF ECU: a064 pm crs state";
CM_ SG_ 1317 PMF_a082_faultAddress "PMF ECU: a082 fault address";
CM_ SG_ 1317 PMF_a082_isWriteNotRead "PMF ECU: a082 is write not read";
CM_ SG_ 1317 PMF_a084_faultAddress "PMF ECU: a084 fault address";
CM_ SG_ 1317 PMF_a084_firewallId "PMF ECU: a084 firewall id";
CM_ SG_ 1317 PMF_a084_privId "PMF ECU: a084 priv id";
CM_ SG_ 1317 PMF_a084_ns "PMF ECU: a084 ns";
CM_ SG_ 1317 PMF_a084_faultType "PMF ECU: a084 fault type";
CM_ SG_ 1317 PMF_a092_pllClockSource "PMF ECU: a092 pll clock source";
CM_ SG_ 1317 PMF_a100_index1kHzPeriodic "PMF ECU: a100 index1k hz periodic";
CM_ SG_ 1317 PMF_a100_index100HzPeriodic "PMF ECU: a100 index100 hz periodic";
CM_ SG_ 1317 PMF_a100_index10HzPeriodic "PMF ECU: a100 index10 hz periodic";
CM_ SG_ 1317 PMF_a100_indexSWI "PMF ECU: a100 index SWI";
CM_ SG_ 1317 PMF_a100_eepEvent "PMF ECU: a100 eep event";
CM_ SG_ 1317 PMF_a100_module500HzActive "PMF ECU: a100 module500 hz active";
CM_ SG_ 1317 PMF_a100_module50HzActive "PMF ECU: a100 module50 hz active";
CM_ SG_ 1317 PMF_a100_module1HzActive "PMF ECU: a100 module1 hz active";
CM_ SG_ 1317 PMF_a100_task10HzActive "PMF ECU: a100 task10 hz active";
CM_ SG_ 1317 PMF_a100_taskUdsActive "PMF ECU: a100 task uds active";
CM_ BO_ 790 "PMF ECU message: info";
CM_ SG_ 790 PMF_infoIndex "PMF ECU: info index";
CM_ SG_ 790 PMF_buildType "PMF ECU: build type";
CM_ SG_ 790 PMF_buildConfigurationId "PMF ECU: build configuration id";
CM_ SG_ 790 PMF_hardwareId "PMF ECU: hardware id";
CM_ SG_ 790 PMF_deviceFused "PMF ECU: device fused";
CM_ SG_ 790 PMF_componentId "PMF ECU: component id";
CM_ SG_ 790 PMF_pcbaId "PMF ECU: pcba id";
CM_ SG_ 790 PMF_assemblyId "PMF ECU: assembly id";
CM_ SG_ 790 PMF_usageId "PMF ECU: usage id";
CM_ SG_ 790 PMF_subUsageId "PMF ECU: sub usage id";
CM_ SG_ 790 PMF_applicationCrc "PMF ECU: application crc";
CM_ SG_ 790 PMF_appGitHash "PMF ECU: app git hash";
CM_ SG_ 790 PMF_bootGitHash "PMF ECU: boot git hash";
CM_ SG_ 790 PMF_platformTyp "PMF ECU: platform typ";
CM_ SG_ 790 PMF_udsProtocolVersion "PMF ECU: uds protocol version";
CM_ SG_ 790 PMF_bootloaderCrc "PMF ECU: bootloader crc";
CM_ BO_ 1446 "PMR ECU message: alert log";
CM_ SG_ 1446 PMR_alertID "PMR ECU: alert ID";
CM_ SG_ 1446 PMR_alertState "PMR ECU: alert state";
CM_ SG_ 1446 PMR_a001_w0 "PMR ECU: a001 w0";
CM_ SG_ 1446 PMR_a001_w1 "PMR ECU: a001 w1";
CM_ SG_ 1446 PMR_a001_w2 "PMR ECU: a001 w2";
CM_ SG_ 1446 PMR_a002_torqueAverage "PMR ECU: a002 torque average";
CM_ SG_ 1446 PMR_a002_torqueWindow "PMR ECU: a002 torque window";
CM_ SG_ 1446 PMR_a002_torqueMeasured "PMR ECU: a002 torque measured; raw 4096 = signal not available (SNA)";
CM_ SG_ 1446 PMR_a002_torqueAccelAverage "PMR ECU: a002 torque accel average; raw 4096 = signal not available (SNA)";
CM_ SG_ 1446 PMR_a002_torqueAccelWindow "PMR ECU: a002 torque accel window; raw 4096 = signal not available (SNA)";
CM_ SG_ 1446 PMR_a003_reverseGear "PMR ECU: a003 reverse gear";
CM_ SG_ 1446 PMR_a003_pedalPos "PMR ECU: a003 pedal pos";
CM_ SG_ 1446 PMR_a003_zeroPointPedal "PMR ECU: a003 zero point pedal";
CM_ SG_ 1446 PMR_a004_torqueAverage "PMR ECU: a004 torque average";
CM_ SG_ 1446 PMR_a004_torqueWindow "PMR ECU: a004 torque window";
CM_ SG_ 1446 PMR_a004_torqueMeasured "PMR ECU: a004 torque measured; raw 4096 = signal not available (SNA)";
CM_ SG_ 1446 PMR_a004_torqueDecelAverage "PMR ECU: a004 torque decel average; raw 4096 = signal not available (SNA)";
CM_ SG_ 1446 PMR_a004_torqueDecelWindow "PMR ECU: a004 torque decel window; raw 4096 = signal not available (SNA)";
CM_ SG_ 1446 PMR_a005_torqueReason "PMR ECU: a005 torque reason";
CM_ SG_ 1446 PMR_a005_torqueMeasured "PMR ECU: a005 torque measured; raw 4096 = signal not available (SNA)";
CM_ SG_ 1446 PMR_a005_iDQmagnitude "PMR ECU: a005 i d qmagnitude";
CM_ SG_ 1446 PMR_a006_torqueActual "PMR ECU: a006 torque actual; raw 4096 = signal not available (SNA)";
CM_ SG_ 1446 PMR_a006_motorRPM "PMR ECU: a006 motor RPM";
CM_ SG_ 1446 PMR_a006_torqueMeasured "PMR ECU: a006 torque measured; raw 4096 = signal not available (SNA)";
CM_ SG_ 1446 PMR_a010_messageId "PMR ECU: a010 message id";
CM_ SG_ 1446 PMR_a010_DI_status "PMR ECU: a010 DI status";
CM_ SG_ 1446 PMR_a010_DI_torque "PMR ECU: a010 DI torque";
CM_ SG_ 1446 PMR_a010_DI_slaveCommand "PMR ECU: a010 DI slave command";
CM_ SG_ 1446 PMR_a010_DI_locStatus "PMR ECU: a010 DI loc status";
CM_ SG_ 1446 PMR_a010_DI_speed "PMR ECU: a010 DI speed";
CM_ SG_ 1446 PMR_a010_DI_systemStatus "PMR ECU: a010 DI system status";
CM_ SG_ 1446 PMR_a010_DI_chassisControl "PMR ECU: a010 DI chassis control";
CM_ SG_ 1446 PMR_a010_DI_chassisControl2 "PMR ECU: a010 DI chassis control2";
CM_ SG_ 1446 PMR_a010_vdcLeft "PMR ECU: a010 vdc left";
CM_ SG_ 1446 PMR_a010_vdcRight "PMR ECU: a010 vdc right";
CM_ SG_ 1446 PMR_a010_DI_vehicleEstimates "PMR ECU: a010 DI vehicle estimates";
CM_ SG_ 1446 PMR_a010_DI_brakeCommand "PMR ECU: a010 DI brake command";
CM_ SG_ 1446 PMR_a010_DI_difCommand "PMR ECU: a010 DI dif command";
CM_ SG_ 1446 PMR_a010_DI_dirCommand "PMR ECU: a010 DI dir command";
CM_ SG_ 1446 PMR_a010_DI_dirVehicle "PMR ECU: a010 DI dir vehicle";
CM_ SG_ 1446 PMR_a010_DI_locStatus2 "PMR ECU: a010 DI loc status2";
CM_ SG_ 1446 PMR_a011_Ia "PMR ECU: a011 ia";
CM_ SG_ 1446 PMR_a011_Ib "PMR ECU: a011 ib";
CM_ SG_ 1446 PMR_a011_currentVref "PMR ECU: a011 current vref";
CM_ SG_ 1446 PMR_a011_badPhaseAsample "PMR ECU: a011 bad phase asample";
CM_ SG_ 1446 PMR_a011_badPhaseBsample "PMR ECU: a011 bad phase bsample";
CM_ SG_ 1446 PMR_a011_sampleFreeze "PMR ECU: a011 sample freeze";
CM_ SG_ 1446 PMR_a012_canID "PMR ECU: a012 can ID";
CM_ SG_ 1446 PMR_a012_errorType "PMR ECU: a012 error type";
CM_ SG_ 1446 PMR_a012_badValue1 "PMR ECU: a012 bad value1";
CM_ SG_ 1446 PMR_a012_badValue2 "PMR ECU: a012 bad value2";
CM_ SG_ 1446 PMR_a013_mailboxID "PMR ECU: a013 mailbox ID";
CM_ SG_ 1446 PMR_a013_canID "PMR ECU: a013 can ID";
CM_ SG_ 1446 PMR_a013_errorType "PMR ECU: a013 error type";
CM_ SG_ 1446 PMR_a017_EPBL_status "PMR ECU: a017 EPBL status";
CM_ SG_ 1446 PMR_a017_EPBR_status "PMR ECU: a017 EPBR status";
CM_ SG_ 1446 PMR_a018_w0 "PMR ECU: a018 w0";
CM_ SG_ 1446 PMR_a018_w1 "PMR ECU: a018 w1";
CM_ SG_ 1446 PMR_a018_w2 "PMR ECU: a018 w2";
CM_ SG_ 1446 PMR_a019_statorTemp1 "PMR ECU: a019 stator temp1";
CM_ SG_ 1446 PMR_a019_statorTslope1 "PMR ECU: a019 stator tslope1";
CM_ SG_ 1446 PMR_a025_sccReset "PMR ECU: a025 scc reset";
CM_ SG_ 1446 PMR_a025_hibernate "PMR ECU: a025 hibernate";
CM_ SG_ 1446 PMR_a025_hwBist "PMR ECU: a025 hw bist";
CM_ SG_ 1446 PMR_a025_nmiWatchdog "PMR ECU: a025 nmi watchdog";
CM_ SG_ 1446 PMR_a025_watchdog "PMR ECU: a025 watchdog";
CM_ SG_ 1446 PMR_a025_clockFailNmi "PMR ECU: a025 clock fail nmi";
CM_ SG_ 1446 PMR_a025_ramUncErrorNmi "PMR ECU: a025 ram unc error nmi";
CM_ SG_ 1446 PMR_a025_flashUncErrorNmi "PMR ECU: a025 flash unc error nmi";
CM_ SG_ 1446 PMR_a025_cpu1signMismatchNmi "PMR ECU: a025 cpu1sign mismatch nmi";
CM_ SG_ 1446 PMR_a025_cpu2signMismatchNmi "PMR ECU: a025 cpu2sign mismatch nmi";
CM_ SG_ 1446 PMR_a025_pieVectErrorNmi "PMR ECU: a025 pie vect error nmi";
CM_ SG_ 1446 PMR_a025_sysDbgNmi "PMR ECU: a025 sys dbg nmi";
CM_ SG_ 1446 PMR_a025_rlNmi "PMR ECU: a025 rl nmi";
CM_ SG_ 1446 PMR_a025_ovfNmi "PMR ECU: a025 ovf nmi";
CM_ SG_ 1446 PMR_a025_possibleSafetyICReset "PMR ECU: a025 possible safety IC reset";
CM_ SG_ 1446 PMR_a025_powerOnReset "PMR ECU: a025 power on reset";
CM_ SG_ 1446 PMR_a025_watchdogTimer0 "PMR ECU: a025 watchdog timer0";
CM_ SG_ 1446 PMR_a025_watchdogTimer1 "PMR ECU: a025 watchdog timer1";
CM_ SG_ 1446 PMR_a025_watchdogTimer2 "PMR ECU: a025 watchdog timer2";
CM_ SG_ 1446 PMR_a025_watchdogTimer3 "PMR ECU: a025 watchdog timer3";
CM_ SG_ 1446 PMR_a025_warmResetReq "PMR ECU: a025 warm reset req";
CM_ SG_ 1446 PMR_a025_externalPadReset "PMR ECU: a025 external pad reset";
CM_ SG_ 1446 PMR_a025_hwSecModuleWatchdogTime "PMR ECU: a025 hw sec module watchdog timer";
CM_ SG_ 1446 PMR_a025_debugReset "PMR ECU: a025 debug reset";
CM_ SG_ 1446 PMR_a025_tempSense0 "PMR ECU: a025 temp sense0";
CM_ SG_ 1446 PMR_a025_tempSense1 "PMR ECU: a025 temp sense1";
CM_ SG_ 1446 PMR_a026_reason "PMR ECU: a026 reason";
CM_ SG_ 1446 PMR_a026_isrCount20kHz "PMR ECU: a026 isr count20k hz";
CM_ SG_ 1446 PMR_a026_isrCount1kHz "PMR ECU: a026 isr count1k hz";
CM_ SG_ 1446 PMR_a026_switchingActive "PMR ECU: a026 switching active";
CM_ SG_ 1446 PMR_a026_systemStackOvf "PMR ECU: a026 system stack ovf";
CM_ SG_ 1446 PMR_a026_controlStackOvf "PMR ECU: a026 control stack ovf";
CM_ SG_ 1446 PMR_a026_idleStackOvf "PMR ECU: a026 idle stack ovf";
CM_ SG_ 1446 PMR_a026_eepStackOvf "PMR ECU: a026 eep stack ovf";
CM_ SG_ 1446 PMR_a026_immStackOvf "PMR ECU: a026 imm stack ovf";
CM_ SG_ 1446 PMR_a026_xdcErrorIdMSW "PMR ECU: a026 xdc error id MSW";
CM_ SG_ 1446 PMR_a026_xdcErrorArg1 "PMR ECU: a026 xdc error arg1";
CM_ SG_ 1446 PMR_a032_w0 "PMR ECU: a032 w0";
CM_ SG_ 1446 PMR_a032_w1 "PMR ECU: a032 w1";
CM_ SG_ 1446 PMR_a032_w2 "PMR ECU: a032 w2";
CM_ SG_ 1446 PMR_a033_state "PMR ECU: a033 state";
CM_ SG_ 1446 PMR_a033_failReason "PMR ECU: a033 fail reason";
CM_ SG_ 1446 PMR_a033_DSADC_Ia "PMR ECU: a033 DSADC ia";
CM_ SG_ 1446 PMR_a033_DSADC_Ib "PMR ECU: a033 DSADC ib";
CM_ SG_ 1446 PMR_a036_timeSinceTxHWI "PMR ECU: a036 time since tx HWI";
CM_ SG_ 1446 PMR_a036_timeSinceRxHWI "PMR ECU: a036 time since rx HWI";
CM_ SG_ 1446 PMR_a036_timeSince100HzTxSWI "PMR ECU: a036 time since100 hz tx SWI";
CM_ SG_ 1446 PMR_a036_timeSince1kHzCLK "PMR ECU: a036 time since1k hz CLK";
CM_ SG_ 1446 PMR_a036_timeSince1kHzSWI "PMR ECU: a036 time since1k hz SWI";
CM_ SG_ 1446 PMR_a036_timeSinceIdle "PMR ECU: a036 time since idle";
CM_ SG_ 1446 PMR_a036_ovfStackId "PMR ECU: a036 ovf stack id; raw 15 = signal not available (SNA)";
CM_ SG_ 1446 PMR_a036_inTxISR "PMR ECU: a036 in tx ISR";
CM_ SG_ 1446 PMR_a036_inTxHWI "PMR ECU: a036 in tx HWI";
CM_ SG_ 1446 PMR_a036_inRxHWI "PMR ECU: a036 in rx HWI";
CM_ SG_ 1446 PMR_a036_in1kHzSWI "PMR ECU: a036 in1k hz SWI";
CM_ SG_ 1446 PMR_a036_in1kHzCLK "PMR ECU: a036 in1k hz CLK";
CM_ SG_ 1446 PMR_a036_in100HzCLK "PMR ECU: a036 in100 hz CLK";
CM_ SG_ 1446 PMR_a036_in10HzCLK "PMR ECU: a036 in10 hz CLK";
CM_ SG_ 1446 PMR_a036_in1HzCLK "PMR ECU: a036 in1 hz CLK";
CM_ SG_ 1446 PMR_a037_hvpFaults "PMR ECU: a037 hvp faults";
CM_ SG_ 1446 PMR_a039_DIS_status "PMR ECU: a039 DIS status";
CM_ SG_ 1446 PMR_a039_DIS_torque "PMR ECU: a039 DIS torque";
CM_ SG_ 1446 PMR_a039_messageId "PMR ECU: a039 message id";
CM_ SG_ 1446 PMR_a040_PM_state "PMR ECU: a040 PM state";
CM_ SG_ 1446 PMR_a040_messageId "PMR ECU: a040 message id";
CM_ SG_ 1446 PMR_a040_PM_locState "PMR ECU: a040 PM loc state";
CM_ SG_ 1446 PMR_a042_GTW_carConfig "PMR ECU: a042 GTW car config";
CM_ SG_ 1446 PMR_a042_GTW_time "PMR ECU: a042 GTW time";
CM_ SG_ 1446 PMR_a042_GTW_drivetrainType "PMR ECU: a042 GTW drivetrain type";
CM_ SG_ 1446 PMR_a042_expectedPerformanceCfg "PMR ECU: a042 expected performance cfg";
CM_ SG_ 1446 PMR_a042_gearControl "PMR ECU: a042 gear control";
CM_ SG_ 1446 PMR_a053_LVPowerState "PMR ECU: a053 LV power state";
CM_ SG_ 1446 PMR_a053_coolant "PMR ECU: a053 coolant";
CM_ SG_ 1446 PMR_a053_vcleftSwitchStatus "PMR ECU: a053 vcleft switch status";
CM_ SG_ 1446 PMR_a053_restraintStatus "PMR ECU: a053 restraint status";
CM_ SG_ 1446 PMR_a053_sensors "PMR ECU: a053 sensors";
CM_ SG_ 1446 PMR_a054_uiPowertrainControl "PMR ECU: a054 ui powertrain control";
CM_ SG_ 1446 PMR_a054_uiChassisControl "PMR ECU: a054 ui chassis control";
CM_ SG_ 1446 PMR_a054_uiCruiseControl "PMR ECU: a054 ui cruise control";
CM_ SG_ 1446 PMR_a054_uiTrackModeSettings "PMR ECU: a054 ui track mode settings";
CM_ SG_ 1446 PMR_a054_uiTPMSRCPSetting "PMR ECU: a054 ui TPMSRCP setting";
CM_ SG_ 1446 PMR_a055_motorRPM "PMR ECU: a055 motor RPM";
CM_ SG_ 1446 PMR_a055_phaseAngle "PMR ECU: a055 phase angle";
CM_ SG_ 1446 PMR_a055_commonGain "PMR ECU: a055 common gain";
CM_ SG_ 1446 PMR_a055_notReady "PMR ECU: a055 not ready";
CM_ SG_ 1446 PMR_a055_noCarrier "PMR ECU: a055 no carrier";
CM_ SG_ 1446 PMR_a055_phaseOutOfSpec "PMR ECU: a055 phase out of spec";
CM_ SG_ 1446 PMR_a055_diElecAngleMismatch "PMR ECU: a055 di elec angle mismatch";
CM_ SG_ 1446 PMR_a055_diSpeedMismatch "PMR ECU: a055 di speed mismatch";
CM_ SG_ 1446 PMR_a055_claMIA "PMR ECU: a055 cla MIA";
CM_ SG_ 1446 PMR_a055_diMIA "PMR ECU: a055 di MIA";
CM_ SG_ 1446 PMR_a055_diElecAngleMismatchWarn "PMR ECU: a055 di elec angle mismatch warn";
CM_ SG_ 1446 PMR_a056_mailboxID "PMR ECU: a056 mailbox ID";
CM_ SG_ 1446 PMR_a056_canID "PMR ECU: a056 can ID";
CM_ SG_ 1446 PMR_a056_errorType "PMR ECU: a056 error type";
CM_ SG_ 1446 PMR_a057_canID "PMR ECU: a057 can ID";
CM_ SG_ 1446 PMR_a057_errorType "PMR ECU: a057 error type";
CM_ SG_ 1446 PMR_a057_badValue1 "PMR ECU: a057 bad value1";
CM_ SG_ 1446 PMR_a057_badValue2 "PMR ECU: a057 bad value2";
CM_ SG_ 1446 PMR_a058_hvilCurrent "PMR ECU: a058 hvil current";
CM_ SG_ 1446 PMR_a061_diIpcVersion "PMR ECU: a061 di ipc version";
CM_ SG_ 1446 PMR_a061_pmIpcVersion "PMR ECU: a061 pm ipc version";
CM_ SG_ 1446 PMR_a062_address "PMR ECU: a062 address";
CM_ SG_ 1446 PMR_a062_errorType "PMR ECU: a062 error type";
CM_ SG_ 1446 PMR_a064_interventionType "PMR ECU: a064 intervention type";
CM_ SG_ 1446 PMR_a064_torqueCmdState "PMR ECU: a064 torque cmd state; raw 0 = signal not available (SNA)";
CM_ SG_ 1446 PMR_a064_shortDetectedByDI "PMR ECU: a064 short detected by DI";
CM_ SG_ 1446 PMR_a064_UI_stoppingMode "PMR ECU: a064 UI stopping mode";
CM_ SG_ 1446 PMR_a064_diCrsState "PMR ECU: a064 di crs state";
CM_ SG_ 1446 PMR_a064_pmCrsState "PMR ECU: a064 pm crs state";
CM_ SG_ 1446 PMR_a082_faultAddress "PMR ECU: a082 fault address";
CM_ SG_ 1446 PMR_a082_isWriteNotRead "PMR ECU: a082 is write not read";
CM_ SG_ 1446 PMR_a084_faultAddress "PMR ECU: a084 fault address";
CM_ SG_ 1446 PMR_a084_firewallId "PMR ECU: a084 firewall id";
CM_ SG_ 1446 PMR_a084_privId "PMR ECU: a084 priv id";
CM_ SG_ 1446 PMR_a084_ns "PMR ECU: a084 ns";
CM_ SG_ 1446 PMR_a084_faultType "PMR ECU: a084 fault type";
CM_ SG_ 1446 PMR_a092_pllClockSource "PMR ECU: a092 pll clock source";
CM_ SG_ 1446 PMR_a100_index1kHzPeriodic "PMR ECU: a100 index1k hz periodic";
CM_ SG_ 1446 PMR_a100_index100HzPeriodic "PMR ECU: a100 index100 hz periodic";
CM_ SG_ 1446 PMR_a100_index10HzPeriodic "PMR ECU: a100 index10 hz periodic";
CM_ SG_ 1446 PMR_a100_indexSWI "PMR ECU: a100 index SWI";
CM_ SG_ 1446 PMR_a100_eepEvent "PMR ECU: a100 eep event";
CM_ SG_ 1446 PMR_a100_module500HzActive "PMR ECU: a100 module500 hz active";
CM_ SG_ 1446 PMR_a100_module50HzActive "PMR ECU: a100 module50 hz active";
CM_ SG_ 1446 PMR_a100_module1HzActive "PMR ECU: a100 module1 hz active";
CM_ SG_ 1446 PMR_a100_task10HzActive "PMR ECU: a100 task10 hz active";
CM_ SG_ 1446 PMR_a100_taskUdsActive "PMR ECU: a100 task uds active";
CM_ SG_ 1446 PMR_a101_VDDA18_ref33_uv "PMR ECU: a101 VDDA18 ref33 uv";
CM_ SG_ 1446 PMR_a101_VBGAP09_ov "PMR ECU: a101 VBGAP09 ov";
CM_ SG_ 1446 PMR_a101_VBGAP09_uv "PMR ECU: a101 VBGAP09 uv";
CM_ SG_ 1446 PMR_a101_VDDA18_refBGAP_ov "PMR ECU: a101 VDDA18 ref BGAP ov";
CM_ SG_ 1446 PMR_a101_VDDA18_refBGAP_uv "PMR ECU: a101 VDDA18 ref BGAP uv";
CM_ SG_ 1446 PMR_a101_VDD12_ov "PMR ECU: a101 VDD12 ov";
CM_ SG_ 1446 PMR_a101_VDD12_uv "PMR ECU: a101 VDD12 uv";
CM_ SG_ 1446 PMR_a101_VDDSBIO_ov "PMR ECU: a101 VDDSBIO ov";
CM_ SG_ 1446 PMR_a101_VDDSBIO_uv "PMR ECU: a101 VDDSBIO uv";
CM_ SG_ 1446 PMR_a101_VSYS_MON_uv "PMR ECU: a101 VSYS MON uv";
CM_ SG_ 1446 PMR_a101_VDDA33_uv "PMR ECU: a101 VDDA33 uv";
CM_ SG_ 1446 PMR_a101_ADC0_REF_ov "PMR ECU: a101 ADC0 REF ov";
CM_ SG_ 1446 PMR_a101_ADC0_REF_uv "PMR ECU: a101 ADC0 REF uv";
CM_ SG_ 1446 PMR_a101_ADC12_REF_ov "PMR ECU: a101 ADC12 REF ov";
CM_ SG_ 1446 PMR_a101_ADC12_REF_uv "PMR ECU: a101 ADC12 REF uv";
CM_ SG_ 1446 PMR_a101_ADC34_REF_ov "PMR ECU: a101 ADC34 REF ov";
CM_ SG_ 1446 PMR_a101_ADC34_REF_uv "PMR ECU: a101 ADC34 REF uv";
CM_ SG_ 1446 PMR_a101_ADCR01_REF_ov "PMR ECU: a101 ADCR01 REF ov";
CM_ SG_ 1446 PMR_a101_ADCR01_REF_uv "PMR ECU: a101 ADCR01 REF uv";
CM_ BO_ 1748 "PMR ECU message: info";
CM_ SG_ 1748 PMR_infoIndex "PMR ECU: info index";
CM_ SG_ 1748 PMR_buildType "PMR ECU: build type";
CM_ SG_ 1748 PMR_buildConfigurationId "PMR ECU: build configuration id";
CM_ SG_ 1748 PMR_hardwareId "PMR ECU: hardware id";
CM_ SG_ 1748 PMR_deviceFused "PMR ECU: device fused";
CM_ SG_ 1748 PMR_componentId "PMR ECU: component id";
CM_ SG_ 1748 PMR_pcbaId "PMR ECU: pcba id";
CM_ SG_ 1748 PMR_assemblyId "PMR ECU: assembly id";
CM_ SG_ 1748 PMR_usageId "PMR ECU: usage id";
CM_ SG_ 1748 PMR_subUsageId "PMR ECU: sub usage id";
CM_ SG_ 1748 PMR_applicationCrc "PMR ECU: application crc";
CM_ SG_ 1748 PMR_appGitHash "PMR ECU: app git hash";
CM_ SG_ 1748 PMR_bootGitHash "PMR ECU: boot git hash";
CM_ SG_ 1748 PMR_platformTyp "PMR ECU: platform typ";
CM_ SG_ 1748 PMR_udsProtocolVersion "PMR ECU: uds protocol version";
CM_ SG_ 1748 PMR_bootloaderCrc "PMR ECU: bootloader crc";
BA_DEF_ BO_ "GenMsgCycleTime" INT 0 3600000;
BA_DEF_ BO_ "GenMsgSendType" ENUM "Cyclic","NotUsed","NotUsed","NotUsed","NotUsed","NotUsed","NotUsed","IfActive","NoMsgSendType","NotUsed";
BA_DEF_ BO_ "VFrameFormat" ENUM "StandardCAN","ExtendedCAN","reserved","J1939PG","reserved","reserved","reserved","reserved","reserved","reserved","reserved","reserved","reserved","reserved","StandardCAN_FD","ExtendedCAN_FD";
BA_DEF_ BO_ "CANFD_BRS" ENUM "0","1";
BA_DEF_ SG_ "GenSigSNA" STRING;
BA_DEF_ SG_ "SystemSignalLongSymbol" STRING;
BA_DEF_ SG_ "Confidence" ENUM "validated","plausible","layout-only","contradicted";
BA_DEF_DEF_ "GenMsgCycleTime" 0;
BA_DEF_DEF_ "GenMsgSendType" "NoMsgSendType";
BA_DEF_DEF_ "VFrameFormat" "StandardCAN";
BA_DEF_DEF_ "CANFD_BRS" "1";
BA_DEF_DEF_ "GenSigSNA" "";
BA_DEF_DEF_ "SystemSignalLongSymbol" "";
BA_DEF_DEF_ "Confidence" "layout-only";
BA_ "GenMsgCycleTime" BO_ 932 1000;
BA_ "GenMsgSendType" BO_ 932 0;
BA_ "GenMsgCycleTime" BO_ 612 100;
BA_ "GenMsgSendType" BO_ 612 0;
BA_ "GenMsgCycleTime" BO_ 516 100;
BA_ "GenMsgSendType" BO_ 516 0;
BA_ "GenMsgCycleTime" BO_ 692 100;
BA_ "GenMsgSendType" BO_ 692 0;
BA_ "GenMsgCycleTime" BO_ 548 100;
BA_ "GenMsgSendType" BO_ 548 0;
BA_ "GenMsgCycleTime" BO_ 964 1000;
BA_ "GenMsgSendType" BO_ 964 0;
BA_ "GenMsgCycleTime" BO_ 708 1000;
BA_ "GenMsgSendType" BO_ 708 0;
BA_ "GenMsgCycleTime" BO_ 676 1000;
BA_ "GenMsgSendType" BO_ 676 0;
BA_ "GenMsgCycleTime" BO_ 790 1000;
BA_ "GenMsgSendType" BO_ 790 0;
BA_ "GenMsgCycleTime" BO_ 1748 1000;
BA_ "GenMsgSendType" BO_ 1748 0;
BA_ "Confidence" SG_ 932 PCS_matrixIndex 1;
BA_ "SystemSignalLongSymbol" SG_ 932 PCS_a032_excessiveGridTransients "PCS_a032_excessiveGridTransientsDetected";
BA_ "SystemSignalLongSymbol" SG_ 932 PCS_a073_unexpectedAcInputVoltag "PCS_a073_unexpectedAcInputVoltage";
BA_ "SystemSignalLongSymbol" SG_ 932 PCS_a084_vDropFastInParasiticDio "PCS_a084_vDropFastInParasiticDiodeRegion";
BA_ "SystemSignalLongSymbol" SG_ 932 PCS_a089_hvBusDischargeIrrationa "PCS_a089_hvBusDischargeIrrational";
BA_ "SystemSignalLongSymbol" SG_ 932 PCS_a090_expectedAcVoltageSource "PCS_a090_expectedAcVoltageSourceMissing";
BA_ "SystemSignalLongSymbol" SG_ 932 PCS_a092_chgPowerLimitedByBusRip "PCS_a092_chgPowerLimitedByBusRipple";
BA_ "SystemSignalLongSymbol" SG_ 932 PCS_a095_dcdcSensorlessModeActiv "PCS_a095_dcdcSensorlessModeActive";
BA_ "SystemSignalLongSymbol" SG_ 932 PCS_a098_gridFreqDroopDetectedSi "PCS_a098_gridFreqDroopDetectedSilent";
BA_ "SystemSignalLongSymbol" SG_ 932 PCS_a099_microGridOverLoadedSile "PCS_a099_microGridOverLoadedSilent";
BA_ "SystemSignalLongSymbol" SG_ 932 PCS_a101_phMachineModelIrrationa "PCS_a101_phMachineModelIrrational";
BA_ "SystemSignalLongSymbol" SG_ 932 PCS_a102_resetWithDCDCCmdAsserte "PCS_a102_resetWithDCDCCmdAsserted";
BA_ "SystemSignalLongSymbol" SG_ 932 PCS_a105_redundantVoltageSourceI "PCS_a105_redundantVoltageSourceIrrational";
BA_ "SystemSignalLongSymbol" SG_ 932 PCS_a106_clockSourceNotFromExter "PCS_a106_clockSourceNotFromExternalCrystal";
BA_ "SystemSignalLongSymbol" SG_ 932 PCS_a108_misconfigurationDetecte "PCS_a108_misconfigurationDetected";
BA_ "SystemSignalLongSymbol" SG_ 932 PCS_a109_deltaChargingL2L3Swappe "PCS_a109_deltaChargingL2L3SwappedDetected";
BA_ "Confidence" SG_ 612 PCS_chgInputVoltage 0;
BA_ "Confidence" SG_ 612 PCS_chgLineCurrent 0;
BA_ "Confidence" SG_ 612 PCS_chgAcVoltagePresent 0;
BA_ "Confidence" SG_ 612 PCS_chgInputPower 0;
BA_ "Confidence" SG_ 612 PCS_chgAcCurrentLimit 0;
BA_ "Confidence" SG_ 516 PCS_chgMainState 0;
BA_ "Confidence" SG_ 516 PCS_hvChargeStatus 1;
BA_ "Confidence" SG_ 516 PCS_gridConfig 0;
BA_ "GenSigSNA" SG_ 516 PCS_gridConfig "0";
BA_ "Confidence" SG_ 516 PCS_chgPHAEnable 0;
BA_ "Confidence" SG_ 516 PCS_chgPHBEnable 0;
BA_ "Confidence" SG_ 516 PCS_hvInletConductorEnergizedAc 0;
BA_ "Confidence" SG_ 516 PCS_chgHighPowerActive 0;
BA_ "Confidence" SG_ 516 PCS_chgPHCEnable 0;
BA_ "Confidence" SG_ 516 PCS_chgInstantAcPowerAvailable 0;
BA_ "Confidence" SG_ 516 PCS_chgMaxAcPowerAvailable 0;
BA_ "GenSigSNA" SG_ 516 PCS_chgMaxAcPowerAvailable "255";
BA_ "Confidence" SG_ 516 PCS_chgPHALineCurrentRequest 0;
BA_ "Confidence" SG_ 516 PCS_chgPHBLineCurrentRequest 0;
BA_ "Confidence" SG_ 516 PCS_chgPHCLineCurrentRequest 0;
BA_ "Confidence" SG_ 516 PCS_chgPwmEnableLine 0;
BA_ "Confidence" SG_ 516 PCS_chargeShutdownRequest 1;
BA_ "Confidence" SG_ 516 PCS_hwVariantType 0;
BA_ "GenSigSNA" SG_ 516 PCS_hwVariantType "3";
BA_ "Confidence" SG_ 692 PCS_dcdcLvBusVolt 0;
BA_ "Confidence" SG_ 692 PCS_dcdcHvBusVolt 0;
BA_ "Confidence" SG_ 692 PCS_dcdcLvOutputCurrent 0;
BA_ "Confidence" SG_ 548 PCS_dcdcPrechargeStatus 0;
BA_ "Confidence" SG_ 548 PCS_dcdcLvSupportStatus 0;
BA_ "Confidence" SG_ 548 PCS_dcdcHvBusDischargeStatus 0;
BA_ "Confidence" SG_ 548 PCS_coldSleepAllowed 0;
BA_ "Confidence" SG_ 548 PCS_dcdcPchgHVBusLowRDetected 0;
BA_ "Confidence" SG_ 548 PCS_dcdcSubState 0;
BA_ "Confidence" SG_ 548 PCS_dcdcFaulted 0;
BA_ "Confidence" SG_ 548 PCS_okToBePowerCycled 0;
BA_ "Confidence" SG_ 548 PCS_dcdcOutputIsLimited 0;
BA_ "Confidence" SG_ 548 PCS_dcdcMaxOutputCurrentAllowed 0;
BA_ "Confidence" SG_ 548 PCS_dcdcPrechargeRtyCnt 0;
BA_ "Confidence" SG_ 548 PCS_dcdcLvSupportRtyCnt 0;
BA_ "Confidence" SG_ 548 PCS_dcdcDischargeRtyCnt 0;
BA_ "Confidence" SG_ 548 PCS_dcdcPwmEnableLine 0;
BA_ "Confidence" SG_ 548 PCS_dcdcSupportingFixedLvTarget 0;
BA_ "Confidence" SG_ 548 PCS_ecuLogUploadRequest 0;
BA_ "Confidence" SG_ 548 PCS_dcdcPrechargeRestartCnt 0;
BA_ "Confidence" SG_ 548 PCS_dcdcInitialPrechargeSubState 0;
BA_ "Confidence" SG_ 964 PCS_infoIndex 1;
BA_ "Confidence" SG_ 964 PCS_buildType 0;
BA_ "Confidence" SG_ 964 PCS_buildConfigId 0;
BA_ "Confidence" SG_ 964 PCS_hardwareId 0;
BA_ "Confidence" SG_ 964 PCS_componentId 0;
BA_ "Confidence" SG_ 964 PCS_pcbaId 0;
BA_ "Confidence" SG_ 964 PCS_assemblyId 0;
BA_ "Confidence" SG_ 964 PCS_usageId 0;
BA_ "Confidence" SG_ 964 PCS_subUsageId 0;
BA_ "Confidence" SG_ 964 PCS_platformType 0;
BA_ "Confidence" SG_ 964 PCS_appCrc 0;
BA_ "Confidence" SG_ 964 PCS_cpu2AppCrc 0;
BA_ "Confidence" SG_ 964 PCS_appGitHash 0;
BA_ "Confidence" SG_ 964 PCS_bootGitHash 0;
BA_ "Confidence" SG_ 964 PCS_bootUdsProtoVersion 0;
BA_ "Confidence" SG_ 964 PCS_bootCrc 0;
BA_ "Confidence" SG_ 708 PCS_logMessageSelect 1;
BA_ "Confidence" SG_ 708 PCS_chgPhAInputIrms 0;
BA_ "Confidence" SG_ 708 PCS_chgPhAIntBusV 0;
BA_ "Confidence" SG_ 708 PCS_chgPhAIntBusVTarget 0;
BA_ "Confidence" SG_ 708 PCS_chgPhAOutputI 0;
BA_ "Confidence" SG_ 708 PCS_chgPhAInputCurrentLimitReaso 0;
BA_ "SystemSignalLongSymbol" SG_ 708 PCS_chgPhAInputCurrentLimitReaso "PCS_chgPhAInputCurrentLimitReason";
BA_ "Confidence" SG_ 708 PCS_chgPhBInputIrms 0;
BA_ "Confidence" SG_ 708 PCS_chgPhBIntBusV 0;
BA_ "Confidence" SG_ 708 PCS_chgPhBIntBusVTarget 0;
BA_ "Confidence" SG_ 708 PCS_chgPhBOutputI 0;
BA_ "Confidence" SG_ 708 PCS_chgPhBInputCurrentLimitReaso 0;
BA_ "SystemSignalLongSymbol" SG_ 708 PCS_chgPhBInputCurrentLimitReaso "PCS_chgPhBInputCurrentLimitReason";
BA_ "Confidence" SG_ 708 PCS_chgPhCInputIrms 0;
BA_ "Confidence" SG_ 708 PCS_chgPhCIntBusV 0;
BA_ "Confidence" SG_ 708 PCS_chgPhCIntBusVTarget 0;
BA_ "Confidence" SG_ 708 PCS_chgPhCOutputI 0;
BA_ "Confidence" SG_ 708 PCS_chgPhCInputCurrentLimitReaso 0;
BA_ "SystemSignalLongSymbol" SG_ 708 PCS_chgPhCInputCurrentLimitReaso "PCS_chgPhCInputCurrentLimitReason";
BA_ "Confidence" SG_ 708 PCS_chgInputL1NVrms 0;
BA_ "Confidence" SG_ 708 PCS_chgInputL2NVrms 0;
BA_ "Confidence" SG_ 708 PCS_chgInputL3NVrms 0;
BA_ "Confidence" SG_ 708 PCS_chgInputL1L2Vrms 0;
BA_ "Confidence" SG_ 708 PCS_chgInputNGVrms 0;
BA_ "Confidence" SG_ 708 PCS_chgInputFrequencyL1N 0;
BA_ "Confidence" SG_ 708 PCS_chgInputFrequencyL2N 0;
BA_ "Confidence" SG_ 708 PCS_chgInputFrequencyL3N 0;
BA_ "Confidence" SG_ 708 PCS_chgInternalPhaseConfig 0;
BA_ "GenSigSNA" SG_ 708 PCS_chgInternalPhaseConfig "0";
BA_ "Confidence" SG_ 708 PCS_chgPhasesPriority 0;
BA_ "Confidence" SG_ 708 PCS_chgOutputV 0;
BA_ "Confidence" SG_ 708 PCS_chgPhAState 0;
BA_ "Confidence" SG_ 708 PCS_chgPhBState 0;
BA_ "Confidence" SG_ 708 PCS_chgPhCState 0;
BA_ "Confidence" SG_ 708 PCS_chgPhALastShutdownReason 0;
BA_ "Confidence" SG_ 708 PCS_chgPhBLastShutdownReason 0;
BA_ "Confidence" SG_ 708 PCS_chgPhCLastShutdownReason 0;
BA_ "Confidence" SG_ 708 PCS_chgPhARetryCount 0;
BA_ "Confidence" SG_ 708 PCS_chgPhBRetryCount 0;
BA_ "Confidence" SG_ 708 PCS_chgPhCRetryCount 0;
BA_ "Confidence" SG_ 708 PCS_chgRetryCount 0;
BA_ "Confidence" SG_ 708 PCS_chgPhManCurrentToDist 0;
BA_ "Confidence" SG_ 708 PCS_chgL1NPllLocked 0;
BA_ "Confidence" SG_ 708 PCS_chgL2NPllLocked 0;
BA_ "Confidence" SG_ 708 PCS_chgL3NPllLocked 0;
BA_ "Confidence" SG_ 708 PCS_chgL1L2PllLocked 0;
BA_ "Confidence" SG_ 708 PCS_chgNgPllLocked 0;
BA_ "Confidence" SG_ 708 PCS_chgPhManOptimalPhsToUse 0;
BA_ "Confidence" SG_ 708 PCS_chg5VL1Enable 0;
BA_ "Confidence" SG_ 708 PCS_dcdcMaxLvOutputCurrent 0;
BA_ "Confidence" SG_ 708 PCS_dcdcCurrentLimit 0;
BA_ "Confidence" SG_ 708 PCS_dcdcLvOutputCurrentTempLimit 0;
BA_ "Confidence" SG_ 708 PCS_dcdcLvOutputCurrentFiltered 0;
BA_ "Confidence" SG_ 708 PCS_dcdcUnifiedCommand 0;
BA_ "Confidence" SG_ 708 PCS_dcdcCLAControllerOutput 0;
BA_ "Confidence" SG_ 708 PCS_dcdcTankVoltage 0;
BA_ "GenSigSNA" SG_ 708 PCS_dcdcTankVoltage "1024";
BA_ "Confidence" SG_ 708 PCS_dcdcTankVoltageTarget 0;
BA_ "Confidence" SG_ 708 PCS_dcdcClaCurrentFreq 0;
BA_ "Confidence" SG_ 708 PCS_dcdcTCommMeasured 0;
BA_ "Confidence" SG_ 708 PCS_dcdcShortTimeUs 0;
BA_ "Confidence" SG_ 708 PCS_dcdcHalfPeriodUs 0;
BA_ "Confidence" SG_ 708 PCS_dcdcLvBusVoltTargetWithOffse 0;
BA_ "SystemSignalLongSymbol" SG_ 708 PCS_dcdcLvBusVoltTargetWithOffse "PCS_dcdcLvBusVoltTargetWithOffset";
BA_ "Confidence" SG_ 708 PCS_cpu2BootState 0;
BA_ "Confidence" SG_ 708 PCS_acChargeSelfTestState 0;
BA_ "Confidence" SG_ 708 PCS_1V5Min10s 0;
BA_ "Confidence" SG_ 708 PCS_1V5Max10s 0;
BA_ "Confidence" SG_ 708 PCS_1V2Min10s 0;
BA_ "Confidence" SG_ 708 PCS_1V2Max10s 0;
BA_ "Confidence" SG_ 708 PCS_5VNMax10s 0;
BA_ "Confidence" SG_ 708 PCS_chgPhAIntBusVMin10s 0;
BA_ "Confidence" SG_ 708 PCS_chgPhAIntBusVMax10s 0;
BA_ "Confidence" SG_ 708 PCS_chgPhAPchgVoltDeltaMax10s 0;
BA_ "Confidence" SG_ 708 PCS_chgPhALifetimekWh 0;
BA_ "Confidence" SG_ 708 PCS_chgPhATransientRetryCount 0;
BA_ "Confidence" SG_ 708 PCS_chgPhBIntBusVMin10s 0;
BA_ "Confidence" SG_ 708 PCS_chgPhBIntBusVMax10s 0;
BA_ "Confidence" SG_ 708 PCS_chgPhBPchgVoltDeltaMax10s 0;
BA_ "Confidence" SG_ 708 PCS_chgPhBLifetimekWh 0;
BA_ "Confidence" SG_ 708 PCS_chgPhBTransientRetryCount 0;
BA_ "Confidence" SG_ 708 PCS_chgPhCIntBusVMin10s 0;
BA_ "Confidence" SG_ 708 PCS_chgPhCIntBusVMax10s 0;
BA_ "Confidence" SG_ 708 PCS_chgPhCPchgVoltDeltaMax10s 0;
BA_ "Confidence" SG_ 708 PCS_chgPhCLifetimekWh 0;
BA_ "Confidence" SG_ 708 PCS_chgPhCTransientRetryCount 0;
BA_ "Confidence" SG_ 708 PCS_chgPhANoFlowBucket 0;
BA_ "Confidence" SG_ 708 PCS_chgPhBNoFlowBucket 0;
BA_ "Confidence" SG_ 708 PCS_chgPhCNoFlowBucket 0;
BA_ "Confidence" SG_ 708 PCS_chgCurrentSensorOutOfBandUs 0;
BA_ "Confidence" SG_ 708 PCS_chgAcpwHeartbeatState 0;
BA_ "Confidence" SG_ 708 PCS_chgKwhLostByFreqDroop 0;
BA_ "Confidence" SG_ 708 PCS_chgReqKwhLostByFreqDroop 0;
BA_ "Confidence" SG_ 708 PCS_dcdcLvSupportLifetimekWh 0;
BA_ "Confidence" SG_ 708 PCS_chgPwmEnableLineErrorCount 0;
BA_ "Confidence" SG_ 708 PCS_dcdcPwmEnableLineErrorCount 0;
BA_ "Confidence" SG_ 708 PCS_numAlertsSet 0;
BA_ "Confidence" SG_ 708 PCS_dcdcPchgStartLvBusVolt 0;
BA_ "Confidence" SG_ 708 PCS_dcdcPchgStartHvBusVolt 0;
BA_ "Confidence" SG_ 708 PCS_processorDieIdLot 0;
BA_ "Confidence" SG_ 708 PCS_processorDieIdWafer 0;
BA_ "Confidence" SG_ 708 PCS_processorDieIdX 0;
BA_ "Confidence" SG_ 708 PCS_processorDieIdY 0;
BA_ "Confidence" SG_ 676 PCS_chgPhATemp 0;
BA_ "GenSigSNA" SG_ 676 PCS_chgPhATemp "1025";
BA_ "Confidence" SG_ 676 PCS_chgPhBTemp 0;
BA_ "GenSigSNA" SG_ 676 PCS_chgPhBTemp "1025";
BA_ "Confidence" SG_ 676 PCS_chgPhCTemp 0;
BA_ "GenSigSNA" SG_ 676 PCS_chgPhCTemp "1025";
BA_ "Confidence" SG_ 676 PCS_dcdcTemp 0;
BA_ "GenSigSNA" SG_ 676 PCS_dcdcTemp "1025";
BA_ "Confidence" SG_ 676 PCS_ambientTemp 0;
BA_ "GenSigSNA" SG_ 676 PCS_ambientTemp "1025";
BA_ "Confidence" SG_ 676 PCS_dcdcBusbarTemp 0;
BA_ "GenSigSNA" SG_ 676 PCS_dcdcBusbarTemp "511";
BA_ "Confidence" SG_ 1317 PMF_alertID 1;
BA_ "Confidence" SG_ 1317 PMF_alertState 1;
BA_ "Confidence" SG_ 1317 PMF_a002_torqueMeasured 1;
BA_ "GenSigSNA" SG_ 1317 PMF_a002_torqueMeasured "4096";
BA_ "Confidence" SG_ 1317 PMF_a002_torqueAccelAverage 1;
BA_ "GenSigSNA" SG_ 1317 PMF_a002_torqueAccelAverage "4096";
BA_ "Confidence" SG_ 1317 PMF_a002_torqueAccelWindow 1;
BA_ "GenSigSNA" SG_ 1317 PMF_a002_torqueAccelWindow "4096";
BA_ "Confidence" SG_ 1317 PMF_a003_pedalPos 1;
BA_ "Confidence" SG_ 1317 PMF_a003_zeroPointPedal 1;
BA_ "Confidence" SG_ 1317 PMF_a004_torqueMeasured 1;
BA_ "GenSigSNA" SG_ 1317 PMF_a004_torqueMeasured "4096";
BA_ "Confidence" SG_ 1317 PMF_a004_torqueDecelAverage 1;
BA_ "GenSigSNA" SG_ 1317 PMF_a004_torqueDecelAverage "4096";
BA_ "Confidence" SG_ 1317 PMF_a004_torqueDecelWindow 1;
BA_ "GenSigSNA" SG_ 1317 PMF_a004_torqueDecelWindow "4096";
BA_ "Confidence" SG_ 1317 PMF_a005_torqueReason 1;
BA_ "Confidence" SG_ 1317 PMF_a005_torqueMeasured 1;
BA_ "GenSigSNA" SG_ 1317 PMF_a005_torqueMeasured "4096";
BA_ "Confidence" SG_ 1317 PMF_a005_iDQmagnitude 1;
BA_ "Confidence" SG_ 1317 PMF_a006_torqueActual 1;
BA_ "GenSigSNA" SG_ 1317 PMF_a006_torqueActual "4096";
BA_ "Confidence" SG_ 1317 PMF_a006_motorRPM 1;
BA_ "Confidence" SG_ 1317 PMF_a006_torqueMeasured 1;
BA_ "GenSigSNA" SG_ 1317 PMF_a006_torqueMeasured "4096";
BA_ "Confidence" SG_ 1317 PMF_a011_Ia 1;
BA_ "Confidence" SG_ 1317 PMF_a011_Ib 1;
BA_ "Confidence" SG_ 1317 PMF_a011_currentVref 1;
BA_ "Confidence" SG_ 1317 PMF_a012_errorType 1;
BA_ "Confidence" SG_ 1317 PMF_a013_errorType 1;
BA_ "Confidence" SG_ 1317 PMF_a019_statorTemp1 1;
BA_ "Confidence" SG_ 1317 PMF_a019_statorTslope1 1;
BA_ "SystemSignalLongSymbol" SG_ 1317 PMF_a025_hwSecModuleWatchdogTime "PMF_a025_hwSecModuleWatchdogTimer";
BA_ "Confidence" SG_ 1317 PMF_a026_reason 1;
BA_ "Confidence" SG_ 1317 PMF_a033_state 1;
BA_ "Confidence" SG_ 1317 PMF_a033_failReason 1;
BA_ "Confidence" SG_ 1317 PMF_a033_DSADC_Ia 1;
BA_ "Confidence" SG_ 1317 PMF_a033_DSADC_Ib 1;
BA_ "Confidence" SG_ 1317 PMF_a036_timeSinceTxHWI 1;
BA_ "Confidence" SG_ 1317 PMF_a036_timeSinceRxHWI 1;
BA_ "Confidence" SG_ 1317 PMF_a036_timeSince100HzTxSWI 1;
BA_ "Confidence" SG_ 1317 PMF_a036_timeSince1kHzCLK 1;
BA_ "Confidence" SG_ 1317 PMF_a036_timeSince1kHzSWI 1;
BA_ "Confidence" SG_ 1317 PMF_a036_timeSinceIdle 1;
BA_ "Confidence" SG_ 1317 PMF_a036_ovfStackId 1;
BA_ "GenSigSNA" SG_ 1317 PMF_a036_ovfStackId "15";
BA_ "Confidence" SG_ 1317 PMF_a042_GTW_drivetrainType 1;
BA_ "Confidence" SG_ 1317 PMF_a042_expectedPerformanceCfg 1;
BA_ "Confidence" SG_ 1317 PMF_a055_motorRPM 1;
BA_ "Confidence" SG_ 1317 PMF_a055_phaseAngle 1;
BA_ "Confidence" SG_ 1317 PMF_a055_commonGain 1;
BA_ "Confidence" SG_ 1317 PMF_a056_errorType 1;
BA_ "Confidence" SG_ 1317 PMF_a057_errorType 1;
BA_ "Confidence" SG_ 1317 PMF_a058_hvilCurrent 1;
BA_ "Confidence" SG_ 1317 PMF_a062_errorType 1;
BA_ "Confidence" SG_ 1317 PMF_a064_interventionType 1;
BA_ "Confidence" SG_ 1317 PMF_a064_torqueCmdState 1;
BA_ "GenSigSNA" SG_ 1317 PMF_a064_torqueCmdState "0";
BA_ "Confidence" SG_ 1317 PMF_a064_UI_stoppingMode 1;
BA_ "Confidence" SG_ 1317 PMF_a064_diCrsState 1;
BA_ "Confidence" SG_ 1317 PMF_a064_pmCrsState 1;
BA_ "Confidence" SG_ 1317 PMF_a084_firewallId 1;
BA_ "Confidence" SG_ 1317 PMF_a084_privId 1;
BA_ "Confidence" SG_ 1317 PMF_a084_faultType 1;
BA_ "Confidence" SG_ 1317 PMF_a092_pllClockSource 1;
BA_ "Confidence" SG_ 790 PMF_infoIndex 1;
BA_ "Confidence" SG_ 790 PMF_buildType 0;
BA_ "Confidence" SG_ 790 PMF_buildConfigurationId 0;
BA_ "Confidence" SG_ 790 PMF_hardwareId 0;
BA_ "Confidence" SG_ 790 PMF_deviceFused 0;
BA_ "Confidence" SG_ 790 PMF_componentId 0;
BA_ "Confidence" SG_ 790 PMF_pcbaId 0;
BA_ "Confidence" SG_ 790 PMF_assemblyId 0;
BA_ "Confidence" SG_ 790 PMF_usageId 0;
BA_ "Confidence" SG_ 790 PMF_subUsageId 0;
BA_ "Confidence" SG_ 790 PMF_applicationCrc 0;
BA_ "Confidence" SG_ 790 PMF_appGitHash 0;
BA_ "Confidence" SG_ 790 PMF_bootGitHash 0;
BA_ "Confidence" SG_ 790 PMF_platformTyp 0;
BA_ "Confidence" SG_ 790 PMF_udsProtocolVersion 0;
BA_ "Confidence" SG_ 790 PMF_bootloaderCrc 0;
BA_ "Confidence" SG_ 1446 PMR_alertID 1;
BA_ "Confidence" SG_ 1446 PMR_alertState 1;
BA_ "Confidence" SG_ 1446 PMR_a002_torqueMeasured 1;
BA_ "GenSigSNA" SG_ 1446 PMR_a002_torqueMeasured "4096";
BA_ "Confidence" SG_ 1446 PMR_a002_torqueAccelAverage 1;
BA_ "GenSigSNA" SG_ 1446 PMR_a002_torqueAccelAverage "4096";
BA_ "Confidence" SG_ 1446 PMR_a002_torqueAccelWindow 1;
BA_ "GenSigSNA" SG_ 1446 PMR_a002_torqueAccelWindow "4096";
BA_ "Confidence" SG_ 1446 PMR_a003_pedalPos 1;
BA_ "Confidence" SG_ 1446 PMR_a003_zeroPointPedal 1;
BA_ "Confidence" SG_ 1446 PMR_a004_torqueMeasured 1;
BA_ "GenSigSNA" SG_ 1446 PMR_a004_torqueMeasured "4096";
BA_ "Confidence" SG_ 1446 PMR_a004_torqueDecelAverage 1;
BA_ "GenSigSNA" SG_ 1446 PMR_a004_torqueDecelAverage "4096";
BA_ "Confidence" SG_ 1446 PMR_a004_torqueDecelWindow 1;
BA_ "GenSigSNA" SG_ 1446 PMR_a004_torqueDecelWindow "4096";
BA_ "Confidence" SG_ 1446 PMR_a005_torqueReason 1;
BA_ "Confidence" SG_ 1446 PMR_a005_torqueMeasured 1;
BA_ "GenSigSNA" SG_ 1446 PMR_a005_torqueMeasured "4096";
BA_ "Confidence" SG_ 1446 PMR_a005_iDQmagnitude 1;
BA_ "Confidence" SG_ 1446 PMR_a006_torqueActual 1;
BA_ "GenSigSNA" SG_ 1446 PMR_a006_torqueActual "4096";
BA_ "Confidence" SG_ 1446 PMR_a006_motorRPM 1;
BA_ "Confidence" SG_ 1446 PMR_a006_torqueMeasured 1;
BA_ "GenSigSNA" SG_ 1446 PMR_a006_torqueMeasured "4096";
BA_ "Confidence" SG_ 1446 PMR_a011_Ia 1;
BA_ "Confidence" SG_ 1446 PMR_a011_Ib 1;
BA_ "Confidence" SG_ 1446 PMR_a011_currentVref 1;
BA_ "Confidence" SG_ 1446 PMR_a012_errorType 1;
BA_ "Confidence" SG_ 1446 PMR_a013_errorType 1;
BA_ "Confidence" SG_ 1446 PMR_a019_statorTemp1 1;
BA_ "Confidence" SG_ 1446 PMR_a019_statorTslope1 1;
BA_ "SystemSignalLongSymbol" SG_ 1446 PMR_a025_hwSecModuleWatchdogTime "PMR_a025_hwSecModuleWatchdogTimer";
BA_ "Confidence" SG_ 1446 PMR_a026_reason 1;
BA_ "Confidence" SG_ 1446 PMR_a033_state 1;
BA_ "Confidence" SG_ 1446 PMR_a033_failReason 1;
BA_ "Confidence" SG_ 1446 PMR_a033_DSADC_Ia 1;
BA_ "Confidence" SG_ 1446 PMR_a033_DSADC_Ib 1;
BA_ "Confidence" SG_ 1446 PMR_a036_timeSinceTxHWI 1;
BA_ "Confidence" SG_ 1446 PMR_a036_timeSinceRxHWI 1;
BA_ "Confidence" SG_ 1446 PMR_a036_timeSince100HzTxSWI 1;
BA_ "Confidence" SG_ 1446 PMR_a036_timeSince1kHzCLK 1;
BA_ "Confidence" SG_ 1446 PMR_a036_timeSince1kHzSWI 1;
BA_ "Confidence" SG_ 1446 PMR_a036_timeSinceIdle 1;
BA_ "Confidence" SG_ 1446 PMR_a036_ovfStackId 1;
BA_ "GenSigSNA" SG_ 1446 PMR_a036_ovfStackId "15";
BA_ "Confidence" SG_ 1446 PMR_a042_GTW_drivetrainType 1;
BA_ "Confidence" SG_ 1446 PMR_a042_expectedPerformanceCfg 1;
BA_ "Confidence" SG_ 1446 PMR_a055_motorRPM 1;
BA_ "Confidence" SG_ 1446 PMR_a055_phaseAngle 1;
BA_ "Confidence" SG_ 1446 PMR_a055_commonGain 1;
BA_ "Confidence" SG_ 1446 PMR_a056_errorType 1;
BA_ "Confidence" SG_ 1446 PMR_a057_errorType 1;
BA_ "Confidence" SG_ 1446 PMR_a058_hvilCurrent 1;
BA_ "Confidence" SG_ 1446 PMR_a062_errorType 1;
BA_ "Confidence" SG_ 1446 PMR_a064_interventionType 1;
BA_ "Confidence" SG_ 1446 PMR_a064_torqueCmdState 1;
BA_ "GenSigSNA" SG_ 1446 PMR_a064_torqueCmdState "0";
BA_ "Confidence" SG_ 1446 PMR_a064_UI_stoppingMode 1;
BA_ "Confidence" SG_ 1446 PMR_a064_diCrsState 1;
BA_ "Confidence" SG_ 1446 PMR_a064_pmCrsState 1;
BA_ "Confidence" SG_ 1446 PMR_a084_firewallId 1;
BA_ "Confidence" SG_ 1446 PMR_a084_privId 1;
BA_ "Confidence" SG_ 1446 PMR_a084_faultType 1;
BA_ "Confidence" SG_ 1446 PMR_a092_pllClockSource 1;
BA_ "Confidence" SG_ 1748 PMR_infoIndex 1;
BA_ "Confidence" SG_ 1748 PMR_buildType 0;
BA_ "Confidence" SG_ 1748 PMR_buildConfigurationId 0;
BA_ "Confidence" SG_ 1748 PMR_hardwareId 0;
BA_ "Confidence" SG_ 1748 PMR_deviceFused 0;
BA_ "Confidence" SG_ 1748 PMR_componentId 0;
BA_ "Confidence" SG_ 1748 PMR_pcbaId 0;
BA_ "Confidence" SG_ 1748 PMR_assemblyId 0;
BA_ "Confidence" SG_ 1748 PMR_usageId 0;
BA_ "Confidence" SG_ 1748 PMR_subUsageId 0;
BA_ "Confidence" SG_ 1748 PMR_applicationCrc 0;
BA_ "Confidence" SG_ 1748 PMR_appGitHash 0;
BA_ "Confidence" SG_ 1748 PMR_bootGitHash 0;
BA_ "Confidence" SG_ 1748 PMR_platformTyp 0;
BA_ "Confidence" SG_ 1748 PMR_udsProtocolVersion 0;
BA_ "Confidence" SG_ 1748 PMR_bootloaderCrc 0;
VAL_ 932 PCS_matrixIndex 1 "AlertMatrix1" 0 "AlertMatrix0" ;
VAL_ 516 PCS_chgMainState 9 "PCS_CHG_STATE_CLEAR_FAULTS" 8 "PCS_CHG_STATE_FAULTED" 7 "PCS_CHG_STATE_SHUTDOWN" 6 "PCS_CHG_STATE_ENABLE" 5 "PCS_CHG_STATE_SYSTEM_CONFIG" 4 "PCS_CHG_STATE_QUALIFY_LINE_CONFIG" 3 "PCS_CHG_STATE_WAIT_FOR_LINE_VOLTAGE" 2 "PCS_CHG_STATE_STARTUP" 1 "PCS_CHG_STATE_IDLE" 0 "PCS_CHG_STATE_INIT" ;
VAL_ 516 PCS_hvChargeStatus 3 "FAULTED" 2 "ENABLED" 1 "BLOCKED" 0 "STANDBY" ;
VAL_ 516 PCS_gridConfig 3 "GRID_CONFIG_THREE_PHASE_DELTA" 2 "GRID_CONFIG_THREE_PHASE" 1 "GRID_CONFIG_SINGLE_PHASE" 0 "GRID_CONFIG_SNA" ;
VAL_ 516 PCS_chgMaxAcPowerAvailable 255 "SNA" ;
VAL_ 516 PCS_chargeShutdownRequest 2 "EMERGENCY_SHUTDOWN_REQUESTED" 1 "GRACEFUL_SHUTDOWN_REQUESTED" 0 "NO_SHUTDOWN_REQUESTED" ;
VAL_ 516 PCS_hwVariantType 3 "PCS_HW_VARIANT_TYPE_SNA" 2 "PCS_THREE_PHASES_VARIANT" 1 "PCS_32A_SINGLE_PHASE_VARIANT" 0 "PCS_48A_SINGLE_PHASE_VARIANT" ;
VAL_ 548 PCS_dcdcPrechargeStatus 3 "PCS_DCDC_PRECHARGE_IMPEDANCE_CHECK" 2 "PCS_DCDC_PRECHARGE_FAULTED" 1 "PCS_DCDC_PRECHARGE_ACTIVE" 0 "PCS_DCDC_PRECHARGE_IDLE" ;
VAL_ 548 PCS_dcdcLvSupportStatus 2 "PCS_DCDC_LV_SUPPORT_FAULTED" 1 "PCS_DCDC_LV_SUPPORT_ACTIVE" 0 "PCS_DCDC_LV_SUPPORT_IDLE" ;
VAL_ 548 PCS_dcdcHvBusDischargeStatus 2 "PCS_DCDC_DIS_HVBUS_FAULTED" 1 "PCS_DCDC_DIS_HVBUS_ACTIVE" 0 "PCS_DCDC_DIS_HVBUS_IDLE" ;
VAL_ 548 PCS_dcdcSubState 18 "DCDC_SUBSTATE_NUM" 17 "DCDC_SUBSTATE_FAULTED" 16 "DCDC_SUBSTATE_CLEAR_FAULTS" 15 "DCDC_SUBSTATE_PCHG_FAULTED" 14 "DCDC_SUBSTATE_DIS_HVBUS_FAULTED" 13 "DCDC_SUBSTATE_LV_SUPPORT_FAULTED" 12 "DCDC_SUBSTATE_SHUTDOWN" 11 "DCDC_SUBSTATE_PCHG_FLT_FAST_DIS_HVBUS" 10 "DCDC_SUBSTATE_PCHG_ACTIVE" 9 "DCDC_SUBSTATE_PCHG_DI_RECOVERY_WAIT" 8 "DCDC_SUBSTATE_PCHG_DWELL_WAIT" 7 "DCDC_SUBSTATE_PCHG_DWELL_CHARGE" 6 "DCDC_SUBSTATE_PCHG_SLOW_DIS_HVBUS" 5 "DCDC_SUBSTATE_PCHG_FAST_DIS_HVBUS" 4 "DCDC_SUBSTATE_SLOW_DIS_HVBUS" 3 "DCDC_SUBSTATE_FAST_DIS_HVBUS" 2 "DCDC_SUBSTATE_LV_SUPPORT_ACTIVE" 1 "DCDC_SUBSTATE_STANDBY" 0 "DCDC_SUBSTATE_PWR_UP_INIT" ;
VAL_ 548 PCS_ecuLogUploadRequest 3 "REQUEST_PRIORITY_3" 2 "REQUEST_PRIORITY_2" 1 "REQUEST_PRIORITY_1" 0 "REQUEST_PRIORITY_NONE" ;
VAL_ 548 PCS_dcdcInitialPrechargeSubState 18 "DCDC_SUBSTATE_NUM" 17 "DCDC_SUBSTATE_FAULTED" 16 "DCDC_SUBSTATE_CLEAR_FAULTS" 15 "DCDC_SUBSTATE_PCHG_FAULTED" 14 "DCDC_SUBSTATE_DIS_HVBUS_FAULTED" 13 "DCDC_SUBSTATE_LV_SUPPORT_FAULTED" 12 "DCDC_SUBSTATE_SHUTDOWN" 11 "DCDC_SUBSTATE_PCHG_FLT_FAST_DIS_HVBUS" 10 "DCDC_SUBSTATE_PCHG_ACTIVE" 9 "DCDC_SUBSTATE_PCHG_DI_RECOVERY_WAIT" 8 "DCDC_SUBSTATE_PCHG_DWELL_WAIT" 7 "DCDC_SUBSTATE_PCHG_DWELL_CHARGE" 6 "DCDC_SUBSTATE_PCHG_SLOW_DIS_HVBUS" 5 "DCDC_SUBSTATE_PCHG_FAST_DIS_HVBUS" 4 "DCDC_SUBSTATE_SLOW_DIS_HVBUS" 3 "DCDC_SUBSTATE_FAST_DIS_HVBUS" 2 "DCDC_SUBSTATE_LV_SUPPORT_ACTIVE" 1 "DCDC_SUBSTATE_STANDBY" 0 "DCDC_SUBSTATE_PWR_UP_INIT" ;
VAL_ 964 PCS_infoIndex 255 "END" 31 "SUBCOMPONENT_GITHASH" 30 "PACKAGE_SN_8_14" 29 "PACKAGE_SN_1_7" 27 "PACKAGE_PN_15_20" 26 "PACKAGE_PN_8_14" 25 "PACKAGE_PN_1_7" 23 "SUBCOMPONENT2" 22 "VARIANTCRC" 20 "UDS_PROTOCOL_BOOTCRC" 19 "VERSION_DEPRECATED" 18 "BOOTLOADER_GITHASH" 17 "APP_GITHASH" 16 "SUBCOMPONENT" 15 "BOOTLOADER_CRC" 14 "BOOTLOADER_SVN" 13 "APP_CRC" 11 "PCBAID_ASSYID_USAGEID" 10 "BUILD_HWID_COMPONENTID" 9 "DEPRECATED_9" 8 "DEPRECATED_8" 7 "DEPRECATED_7" 6 "DEPRECATED_6" 5 "DEPRECATED_5" 4 "DEPRECATED_4" 3 "DEPRECATED_3" 2 "DEPRECATED_2" 1 "DEPRECATED_1" 0 "DEPRECATED_0" ;
VAL_ 964 PCS_buildType 4 "INFO_MFG_BUILD" 3 "INFO_TRACEABLE_CI_BUILD" 2 "INFO_LOCAL_BUILD" 1 "INFO_PLATFORM_BUILD" 0 "INFO_UNKNOWN_BUILD" ;
VAL_ 708 PCS_logMessageSelect 27 "NUM_MSGS" 26 "PROCESSOR_DIE_ID" 25 "DCDC_IMPEDANCE_EST" 24 "DCDC_HVBUS_PCHG_DATA" 23 "CHG_MACHINEMODEL" 22 "DCDC_STATISTICS" 21 "CHG_LINE_OFFSET" 20 "CHG_NO_FLOW" 19 "DCDC_5" 18 "DCDC_4" 17 "DLOG_4" 16 "DLOG_3" 15 "DLOG_2" 14 "DLOG_1" 13 "CHG_4" 12 "PHC_2" 11 "PHB_2" 10 "PHA_2" 9 "SYSTEM_1" 8 "DCDC_3" 7 "DCDC_2" 6 "DCDC_1" 5 "CHG_3" 4 "CHG_2" 3 "CHG_1" 2 "PHC_1" 1 "PHB_1" 0 "PHA_1" ;
VAL_ 708 PCS_chgPhAInputCurrentLimitReaso 5 "PCS_IAC_LIMITED_BY_PHASE_MACHINE_MODEL" 4 "PCS_IAC_LIMITED_BY_PHASE_THERMAL_LIMIT" 3 "PCS_IAC_LIMITED_BY_INPUT_POWER" 2 "PCS_IAC_LIMITED_BY_OUTPUT_POWER" 1 "PCS_IAC_LIMITED_BY_RIPPLE_RELAXED" 0 "PCS_IAC_LIMITED_BY_NONE" ;
VAL_ 708 PCS_chgPhBInputCurrentLimitReaso 5 "PCS_IAC_LIMITED_BY_PHASE_MACHINE_MODEL" 4 "PCS_IAC_LIMITED_BY_PHASE_THERMAL_LIMIT" 3 "PCS_IAC_LIMITED_BY_INPUT_POWER" 2 "PCS_IAC_LIMITED_BY_OUTPUT_POWER" 1 "PCS_IAC_LIMITED_BY_RIPPLE_RELAXED" 0 "PCS_IAC_LIMITED_BY_NONE" ;
VAL_ 708 PCS_chgPhCInputCurrentLimitReaso 5 "PCS_IAC_LIMITED_BY_PHASE_MACHINE_MODEL" 4 "PCS_IAC_LIMITED_BY_PHASE_THERMAL_LIMIT" 3 "PCS_IAC_LIMITED_BY_INPUT_POWER" 2 "PCS_IAC_LIMITED_BY_OUTPUT_POWER" 1 "PCS_IAC_LIMITED_BY_RIPPLE_RELAXED" 0 "PCS_IAC_LIMITED_BY_NONE" ;
VAL_ 708 PCS_chgInputFrequencyL1N 0 "FREQUENCY_UNKNOWN" ;
VAL_ 708 PCS_chgInputFrequencyL2N 0 "FREQUENCY_UNKNOWN" ;
VAL_ 708 PCS_chgInputFrequencyL3N 0 "FREQUENCY_UNKNOWN" ;
VAL_ 708 PCS_chgInternalPhaseConfig 9 "PHASE_CONFIG_TOTAL_NUM" 8 "PHASE_CONFIG_SINGLE_PHASE_EVSE_PARALLEL" 7 "PHASE_CONFIG_SINGLE_PHASE_BRIDGED_HARNESS" 6 "PHASE_CONFIG_MFG_TEST_CONFIG_2" 5 "PHASE_CONFIG_MFG_TEST_CONFIG_1" 4 "PHASE_CONFIG_SINGLE_PHASE_IEC_GB" 3 "PHASE_CONFIG_THREE_PHASE_DELTA" 2 "PHASE_CONFIG_THREE_PHASE" 1 "PHASE_CONFIG_SINGLE_PHASE" 0 "PHASE_CONFIG_SNA" ;
VAL_ 708 PCS_chgPhasesPriority 36 "PHASES_PRIORITY_ABC" 33 "PHASES_PRIORITY_BAC" 24 "PHASES_PRIORITY_ACB" 18 "PHASES_PRIORITY_CAB" 9 "PHASES_PRIORITY_BCA" 6 "PHASES_PRIORITY_CBA" 0 "UNDEFINED_PHASES_PRIORITY" ;
VAL_ 708 PCS_chgPhAState 6 "PCS_PH_STATE_SHUTTING_DOWN" 5 "PCS_PH_STATE_CLEAR_FAULTS" 4 "PCS_PH_STATE_FAULT" 3 "PCS_PH_STATE_ENABLE" 2 "PCS_PH_STATE_PRECHARGE" 1 "PCS_PH_STATE_IDLE" 0 "PCS_PH_STATE_INIT" ;
VAL_ 708 PCS_chgPhBState 6 "PCS_PH_STATE_SHUTTING_DOWN" 5 "PCS_PH_STATE_CLEAR_FAULTS" 4 "PCS_PH_STATE_FAULT" 3 "PCS_PH_STATE_ENABLE" 2 "PCS_PH_STATE_PRECHARGE" 1 "PCS_PH_STATE_IDLE" 0 "PCS_PH_STATE_INIT" ;
VAL_ 708 PCS_chgPhCState 6 "PCS_PH_STATE_SHUTTING_DOWN" 5 "PCS_PH_STATE_CLEAR_FAULTS" 4 "PCS_PH_STATE_FAULT" 3 "PCS_PH_STATE_ENABLE" 2 "PCS_PH_STATE_PRECHARGE" 1 "PCS_PH_STATE_IDLE" 0 "PCS_PH_STATE_INIT" ;
VAL_ 708 PCS_chgPhALastShutdownReason 17 "PCS_PH_SHUTDOWN_LINE_TRANSIENT_FAULT" 16 "PCS_PH_SHUTDOWN_FREQ_OUT_OF_RANGE" 15 "PCS_PH_SHUTDOWN_SENSOR_IRRATIONAL" 14 "PCS_PH_SHUTDOWN_TEMP_IRRATIONAL" 13 "PCS_PH_SHUTDOWN_OVER_TEMPERATURE" 12 "PCS_PH_SHUTDOWN_CONTROL_REGULATION_FAULT" 11 "PCS_PH_SHUTDOWN_INT_BUS_UV" 10 "PCS_PH_SHUTDOWN_PRECHARGE_TIMEOUT" 9 "PCS_PH_SHUTDOWN_OUTPUT_OV" 8 "PCS_PH_SHUTDOWN_OUTPUT_UV" 7 "PCS_PH_SHUTDOWN_INPUT_OV" 6 "PCS_PH_SHUTDOWN_INPUT_UV" 5 "PCS_PH_SHUTDOWN_PLL_NOT_LOCKED" 4 "PCS_PH_SHUTDOWN_HW_FAULT" 3 "PCS_PH_SHUTDOWN_SW_FAULT" 2 "PCS_PH_SHUTDOWN_HW_ENABLE" 1 "PCS_PH_SHUTDOWN_SW_ENABLE" 0 "PCS_PH_SHUTDOWN_REASON_NONE" ;
VAL_ 708 PCS_chgPhBLastShutdownReason 17 "PCS_PH_SHUTDOWN_LINE_TRANSIENT_FAULT" 16 "PCS_PH_SHUTDOWN_FREQ_OUT_OF_RANGE" 15 "PCS_PH_SHUTDOWN_SENSOR_IRRATIONAL" 14 "PCS_PH_SHUTDOWN_TEMP_IRRATIONAL" 13 "PCS_PH_SHUTDOWN_OVER_TEMPERATURE" 12 "PCS_PH_SHUTDOWN_CONTROL_REGULATION_FAULT" 11 "PCS_PH_SHUTDOWN_INT_BUS_UV" 10 "PCS_PH_SHUTDOWN_PRECHARGE_TIMEOUT" 9 "PCS_PH_SHUTDOWN_OUTPUT_OV" 8 "PCS_PH_SHUTDOWN_OUTPUT_UV" 7 "PCS_PH_SHUTDOWN_INPUT_OV" 6 "PCS_PH_SHUTDOWN_INPUT_UV" 5 "PCS_PH_SHUTDOWN_PLL_NOT_LOCKED" 4 "PCS_PH_SHUTDOWN_HW_FAULT" 3 "PCS_PH_SHUTDOWN_SW_FAULT" 2 "PCS_PH_SHUTDOWN_HW_ENABLE" 1 "PCS_PH_SHUTDOWN_SW_ENABLE" 0 "PCS_PH_SHUTDOWN_REASON_NONE" ;
VAL_ 708 PCS_chgPhCLastShutdownReason 17 "PCS_PH_SHUTDOWN_LINE_TRANSIENT_FAULT" 16 "PCS_PH_SHUTDOWN_FREQ_OUT_OF_RANGE" 15 "PCS_PH_SHUTDOWN_SENSOR_IRRATIONAL" 14 "PCS_PH_SHUTDOWN_TEMP_IRRATIONAL" 13 "PCS_PH_SHUTDOWN_OVER_TEMPERATURE" 12 "PCS_PH_SHUTDOWN_CONTROL_REGULATION_FAULT" 11 "PCS_PH_SHUTDOWN_INT_BUS_UV" 10 "PCS_PH_SHUTDOWN_PRECHARGE_TIMEOUT" 9 "PCS_PH_SHUTDOWN_OUTPUT_OV" 8 "PCS_PH_SHUTDOWN_OUTPUT_UV" 7 "PCS_PH_SHUTDOWN_INPUT_OV" 6 "PCS_PH_SHUTDOWN_INPUT_UV" 5 "PCS_PH_SHUTDOWN_PLL_NOT_LOCKED" 4 "PCS_PH_SHUTDOWN_HW_FAULT" 3 "PCS_PH_SHUTDOWN_SW_FAULT" 2 "PCS_PH_SHUTDOWN_HW_ENABLE" 1 "PCS_PH_SHUTDOWN_SW_ENABLE" 0 "PCS_PH_SHUTDOWN_REASON_NONE" ;
VAL_ 708 PCS_dcdcTankVoltage -1024 "TANK_VOLTAGE_SNA" ;
VAL_ 708 PCS_cpu2BootState 3 "CPU2_STATE_ERROR" 2 "CPU2_STATE_APPLICATION" 1 "CPU2_STATE_BOOTLOADER" 0 "CPU2_STATE_BOOTROM" ;
VAL_ 708 PCS_acChargeSelfTestState 1 "PCS_SELF_TEST_STARTED" 0 "PCS_SELF_TEST_IDLE" ;
VAL_ 708 PCS_chgAcpwHeartbeatState 4 "PCS_ACPW_HEARTBEAT_STATE_NUM" 3 "PCS_ACPW_HEARTBEAT_STATE_DETECTED_ONGRID" 2 "PCS_ACPW_HEARTBEAT_STATE_DETECTED_OFFGRID" 1 "PCS_ACPW_HEARTBEAT_STATE_NOT_DETECTED" 0 "PCS_ACPW_HEARTBEAT_STATE_UNKNOWN" ;
VAL_ 676 PCS_chgPhATemp -1023 "SNA" ;
VAL_ 676 PCS_chgPhBTemp -1023 "SNA" ;
VAL_ 676 PCS_chgPhCTemp -1023 "SNA" ;
VAL_ 676 PCS_dcdcTemp -1023 "SNA" ;
VAL_ 676 PCS_ambientTemp -1023 "SNA" ;
VAL_ 676 PCS_dcdcBusbarTemp 511 "SNA" ;
VAL_ 1317 PMF_alertID 121 "a121_unintendedReset2" 100 "a100_diTraceInfo1" 97 "a097_lowFlowAlmostTripped" 96 "a096_safetyICDebug" 95 "a095_safetyICFault" 94 "a094_safetyICWarn" 92 "a092_xtalOscillator" 86 "a086_exceptionUndefinedInstruction" 84 "a084_exceptionMpuFirewall" 83 "a083_ahbWriteError" 82 "a082_exceptionDataAbort2" 81 "a081_exceptionDataAbort" 80 "a080_exceptionPrefetchAbort" 64 "a064_torqueIntervention" 62 "a062_eccError" 61 "a061_DIPMVersionMismatch" 58 "a058_measuredHvilCurrentFrozen" 57 "a057_canDataBusB" 56 "a056_canHardwareBusB" 55 "a055_resolver" 54 "a054_uiMIA" 53 "a053_vcfrontMIA" 45 "a045_motorMovementDetected" 42 "a042_gtwMIA" 40 "a040_pmMIA" 39 "a039_disMIA" 37 "a037_hvpMIA" 36 "a036_preWatchdog" 35 "a035_udsTransactionInitiated" 34 "a034_trqCrossCheck" 33 "a033_selfTest" 32 "a032_registerConfigError" 31 "a031_highStackUsage" 28 "a028_torqueCmdError" 27 "a027_torqueEstimationOutOfBounds" 26 "a026_diHeartBeatMIA" 25 "a025_unintendedReset" 19 "a019_statorTempIrrational" 18 "a018_encoderIrrational" 17 "a017_brakeMIA" 13 "a013_canHardwareBusA" 12 "a012_canDataBusA" 11 "a011_phaseCurrentIrrational" 10 "a010_diMIA" 8 "a008_memoryError" 6 "a006_underTorqueCheck" 5 "a005_torqueInNeutralOrPark" 4 "a004_excessiveDecelTorque" 3 "a003_excessiveReversalTorque" 2 "a002_excessiveAccelTorque" 1 "a001_absoluteTorque" 0 "ALERT_DO_NOT_USE_ZERO" ;
VAL_ 1317 PMF_alertState 1 "SET" 0 "CLEARED" ;
VAL_ 1317 PMF_a002_torqueMeasured -4096 "SNA" ;
VAL_ 1317 PMF_a002_torqueAccelAverage -4096 "SNA" ;
VAL_ 1317 PMF_a002_torqueAccelWindow -4096 "SNA" ;
VAL_ 1317 PMF_a004_torqueMeasured -4096 "SNA" ;
VAL_ 1317 PMF_a004_torqueDecelAverage -4096 "SNA" ;
VAL_ 1317 PMF_a004_torqueDecelWindow -4096 "SNA" ;
VAL_ 1317 PMF_a005_torqueReason 2 "SLAVE_ENABLE_IN_NEUTRAL" 1 "CURRENT_IN_NEUTRAL" 0 "TORQUE_IN_NEUTRAL" ;
VAL_ 1317 PMF_a005_torqueMeasured -4096 "SNA" ;
VAL_ 1317 PMF_a006_torqueActual -4096 "SNA" ;
VAL_ 1317 PMF_a006_torqueMeasured -4096 "SNA" ;
VAL_ 1317 PMF_a012_errorType 6 "UNKNOWN_ID" 5 "DATA_INVALID" 4 "SEQUENCE" 3 "CHECKSUM" 2 "LENGTH_LONG" 1 "LENGTH_SHORT" 0 "NONE" ;
VAL_ 1317 PMF_a013_errorType 5 "IPC_TX_OVERRUN" 4 "IPC_RX_OVERRUN" 3 "TX_OVERRUN" 2 "RX_OVERRUN" 1 "TX" 0 "RX" ;
VAL_ 1317 PMF_a026_reason 1 "TooFast" 0 "TooSlow" ;
VAL_ 1317 PMF_a033_state 12 "TEST_RESTART" 11 "TEST_FAILED" 10 "TEST_SKIPPED" 9 "TEST_PASSED" 8 "TEST_PRE_PASSED" 7 "CURRENT_TEST_NEG" 6 "CURRENT_TEST_POS" 5 "PWM_ENABLE" 4 "ASC_TEST_PASSED" 3 "ASC_TEST" 2 "PSTG_BRING_UP_AT_SPEED" 1 "PSTG_BRING_UP" 0 "INIT" ;
VAL_ 1317 PMF_a033_failReason 7 "ASC_TEST" 6 "FAULT_PRESENT" 5 "GATE_DRIVE_ERROR" 4 "TIMEDOUT" 3 "DISAGREE" 2 "NEG_CURRENT" 1 "POS_CURRENT" 0 "CACHED" ;
VAL_ 1317 PMF_a036_ovfStackId 15 "SNA" ;
VAL_ 1317 PMF_a042_GTW_drivetrainType 1 "AWD" 0 "RWD" ;
VAL_ 1317 PMF_a042_expectedPerformanceCfg 1 "AWD" 0 "RWD" ;
VAL_ 1317 PMF_a056_errorType 5 "IPC_TX_OVERRUN" 4 "IPC_RX_OVERRUN" 3 "TX_OVERRUN" 2 "RX_OVERRUN" 1 "TX" 0 "RX" ;
VAL_ 1317 PMF_a057_errorType 6 "UNKNOWN_ID" 5 "DATA_INVALID" 4 "SEQUENCE" 3 "CHECKSUM" 2 "LENGTH_LONG" 1 "LENGTH_SHORT" 0 "NONE" ;
VAL_ 1317 PMF_a062_errorType 12 "RAM_CORRECTABLE_DMA" 11 "RAM_CORRECTABLE_CLA" 10 "RAM_CORRECTABLE_CPU" 9 "RAM_UNCORRECTABLE_DMA" 8 "RAM_UNCORRECTABLE_CLA" 7 "RAM_UNCORRECTABLE_CPU" 6 "FLASH_FAIL1_HIGH" 5 "FLASH_FAIL1_LOW" 4 "FLASH_FAIL0_HIGH" 3 "FLASH_FAIL0_LOW" 2 "FLASH_UNCORRECTABLE_HIGH" 1 "FLASH_UNCORRECTABLE_LOW" 0 "UNKNOWN" ;
VAL_ 1317 PMF_a064_interventionType 15 "excessiveMotorMz" 14 "inconsistentAxleTorque" 13 "diHeartbeat" 12 "currentAfterIntervention" 11 "switchingAfterIntervention" 10 "switchOffPathTestFail" 9 "inconsistentTorqueSign" 8 "torqueInNeutral" 7 "excessiveRegenTorque" 6 "torqueReversal" 5 "accumulatedTorque" 4 "motorMovementDetected" 3 "cruiseFault" 2 "torqueCmdInvalid" 1 "resolver" 0 "masterTorqueMonitorShutoff" ;
VAL_ 1317 PMF_a064_torqueCmdState 8 "Invalid" 6 "Valid" 0 "SNA" ;
VAL_ 1317 PMF_a064_UI_stoppingMode 2 "HOLD" 1 "CREEP" 0 "STANDARD" ;
VAL_ 1317 PMF_a064_diCrsState 7 "PRE_CANCEL" 6 "PRE_FAULT" 5 "FAULT" 4 "OVERRIDE" 3 "STANDSTILL" 2 "ENABLED" 1 "STANDBY" 0 "UNAVAILABLE" ;
VAL_ 1317 PMF_a064_pmCrsState 7 "PRE_CANCEL" 6 "PRE_FAULT" 5 "FAULT" 4 "OVERRIDE" 3 "STANDSTILL" 2 "ENABLED" 1 "STANDBY" 0 "UNAVAILABLE" ;
VAL_ 1317 PMF_a084_firewallId 17 "HSM_SLV" 16 "R5SS1_CORE1_AHB_MST" 15 "R5SS1_CORE0_AHB_MST" 14 "R5SS0_CORE1_AHB_MST" 13 "R5SS0_CORE0_AHB_MST" 12 "SCRM2SCRP1_SLV" 11 "SCRM2SCRP0_SLV" 10 "QSPI0_SLV" 9 "MBOX_RAM_SLV" 8 "DTHE_SLV" 7 "R5SS1_CORE1_AXIS_SLV" 6 "R5SS1_CORE0_AXIS_SLV" 5 "R5SS0_CORE1_AXIS_SLV" 4 "R5SS0_CORE0_AXIS_SLV" 3 "L2OCRAM_BANK3_SLV" 2 "L2OCRAM_BANK2_SLV" 1 "L2OCRAM_BANK1_SLV" 0 "L2OCRAM_BANK0_SLV" ;
VAL_ 1317 PMF_a084_privId 10 "CPSW" 9 "ICSSM" 7 "R5FSS1_1" 6 "R5FSS1_0" 5 "R5FSS0_1" 4 "R5FSS0_0" 1 "M4FSS0_0" ;
VAL_ 1317 PMF_a084_faultType 6 "SUPER_READ" 5 "SUPER_WRITE" 4 "SUPER_EXE" 3 "USER_READ" 2 "USER_WRITE" 1 "USER_EXE" 0 "NO_FAULT" ;
VAL_ 1317 PMF_a092_pllClockSource 2 "INTOSC1" 1 "XTAL" 0 "INTOSC2" ;
VAL_ 790 PMF_infoIndex 255 "END" 21 "DI_BUILD_DATA" 20 "UDS_PROTOCOL_BOOTCRC" 19 "VERSION_DEPRECATED" 18 "BOOTLOADER_GITHASH" 17 "APP_GITHASH" 16 "SUBCOMPONENT" 15 "BOOTLOADER_CRC" 14 "BOOTLOADER_SVN" 13 "APP_CRC" 11 "PCBAID_ASSYID_USAGEID" 10 "BUILD_HWID_COMPONENTID" 9 "DEPRECATED_9" 8 "DEPRECATED_8" 7 "DEPRECATED_7" 6 "DEPRECATED_6" 5 "DEPRECATED_5" 4 "DEPRECATED_4" 3 "DEPRECATED_3" 2 "DEPRECATED_2" 1 "DEPRECATED_1" 0 "DEPRECATED_0" ;
VAL_ 790 PMF_buildType 4 "INFO_MFG_BUILD" 3 "INFO_TRACEABLE_CI_BUILD" 2 "INFO_LOCAL_BUILD" 1 "INFO_PLATFORM_BUILD" 0 "INFO_UNKNOWN_BUILD" ;
VAL_ 790 PMF_hardwareId 252 "CONFIGURABLE_HWID_PLACEHOLDER" ;
VAL_ 1446 PMR_alertID 121 "a121_unintendedReset2" 101 "a101_hwVoltageMonitorTrip" 100 "a100_diTraceInfo1" 97 "a097_lowFlowAlmostTripped" 96 "a096_safetyICDebug" 95 "a095_safetyICFault" 94 "a094_safetyICWarn" 92 "a092_xtalOscillator" 86 "a086_exceptionUndefinedInstruction" 84 "a084_exceptionMpuFirewall" 83 "a083_ahbWriteError" 82 "a082_exceptionDataAbort2" 81 "a081_exceptionDataAbort" 80 "a080_exceptionPrefetchAbort" 64 "a064_torqueIntervention" 62 "a062_eccError" 61 "a061_DIPMVersionMismatch" 58 "a058_measuredHvilCurrentFrozen" 57 "a057_canDataBusB" 56 "a056_canHardwareBusB" 55 "a055_resolver" 54 "a054_uiMIA" 53 "a053_vcfrontMIA" 45 "a045_motorMovementDetected" 42 "a042_gtwMIA" 40 "a040_pmMIA" 39 "a039_disMIA" 37 "a037_hvpMIA" 36 "a036_preWatchdog" 35 "a035_udsTransactionInitiated" 34 "a034_trqCrossCheck" 33 "a033_selfTest" 32 "a032_registerConfigError" 31 "a031_highStackUsage" 28 "a028_torqueCmdError" 27 "a027_torqueEstimationOutOfBounds" 26 "a026_diHeartBeatMIA" 25 "a025_unintendedReset" 19 "a019_statorTempIrrational" 18 "a018_encoderIrrational" 17 "a017_brakeMIA" 13 "a013_canHardwareBusA" 12 "a012_canDataBusA" 11 "a011_phaseCurrentIrrational" 10 "a010_diMIA" 8 "a008_memoryError" 6 "a006_underTorqueCheck" 5 "a005_torqueInNeutralOrPark" 4 "a004_excessiveDecelTorque" 3 "a003_excessiveReversalTorque" 2 "a002_excessiveAccelTorque" 1 "a001_absoluteTorque" 0 "ALERT_DO_NOT_USE_ZERO" ;
VAL_ 1446 PMR_alertState 1 "SET" 0 "CLEARED" ;
VAL_ 1446 PMR_a002_torqueMeasured -4096 "SNA" ;
VAL_ 1446 PMR_a002_torqueAccelAverage -4096 "SNA" ;
VAL_ 1446 PMR_a002_torqueAccelWindow -4096 "SNA" ;
VAL_ 1446 PMR_a004_torqueMeasured -4096 "SNA" ;
VAL_ 1446 PMR_a004_torqueDecelAverage -4096 "SNA" ;
VAL_ 1446 PMR_a004_torqueDecelWindow -4096 "SNA" ;
VAL_ 1446 PMR_a005_torqueReason 2 "SLAVE_ENABLE_IN_NEUTRAL" 1 "CURRENT_IN_NEUTRAL" 0 "TORQUE_IN_NEUTRAL" ;
VAL_ 1446 PMR_a005_torqueMeasured -4096 "SNA" ;
VAL_ 1446 PMR_a006_torqueActual -4096 "SNA" ;
VAL_ 1446 PMR_a006_torqueMeasured -4096 "SNA" ;
VAL_ 1446 PMR_a012_errorType 6 "UNKNOWN_ID" 5 "DATA_INVALID" 4 "SEQUENCE" 3 "CHECKSUM" 2 "LENGTH_LONG" 1 "LENGTH_SHORT" 0 "NONE" ;
VAL_ 1446 PMR_a013_errorType 5 "IPC_TX_OVERRUN" 4 "IPC_RX_OVERRUN" 3 "TX_OVERRUN" 2 "RX_OVERRUN" 1 "TX" 0 "RX" ;
VAL_ 1446 PMR_a026_reason 1 "TooFast" 0 "TooSlow" ;
VAL_ 1446 PMR_a033_state 12 "TEST_RESTART" 11 "TEST_FAILED" 10 "TEST_SKIPPED" 9 "TEST_PASSED" 8 "TEST_PRE_PASSED" 7 "CURRENT_TEST_NEG" 6 "CURRENT_TEST_POS" 5 "PWM_ENABLE" 4 "ASC_TEST_PASSED" 3 "ASC_TEST" 2 "PSTG_BRING_UP_AT_SPEED" 1 "PSTG_BRING_UP" 0 "INIT" ;
VAL_ 1446 PMR_a033_failReason 7 "ASC_TEST" 6 "FAULT_PRESENT" 5 "GATE_DRIVE_ERROR" 4 "TIMEDOUT" 3 "DISAGREE" 2 "NEG_CURRENT" 1 "POS_CURRENT" 0 "CACHED" ;
VAL_ 1446 PMR_a036_ovfStackId 15 "SNA" ;
VAL_ 1446 PMR_a042_GTW_drivetrainType 1 "AWD" 0 "RWD" ;
VAL_ 1446 PMR_a042_expectedPerformanceCfg 1 "AWD" 0 "RWD" ;
VAL_ 1446 PMR_a056_errorType 5 "IPC_TX_OVERRUN" 4 "IPC_RX_OVERRUN" 3 "TX_OVERRUN" 2 "RX_OVERRUN" 1 "TX" 0 "RX" ;
VAL_ 1446 PMR_a057_errorType 6 "UNKNOWN_ID" 5 "DATA_INVALID" 4 "SEQUENCE" 3 "CHECKSUM" 2 "LENGTH_LONG" 1 "LENGTH_SHORT" 0 "NONE" ;
VAL_ 1446 PMR_a062_errorType 12 "RAM_CORRECTABLE_DMA" 11 "RAM_CORRECTABLE_CLA" 10 "RAM_CORRECTABLE_CPU" 9 "RAM_UNCORRECTABLE_DMA" 8 "RAM_UNCORRECTABLE_CLA" 7 "RAM_UNCORRECTABLE_CPU" 6 "FLASH_FAIL1_HIGH" 5 "FLASH_FAIL1_LOW" 4 "FLASH_FAIL0_HIGH" 3 "FLASH_FAIL0_LOW" 2 "FLASH_UNCORRECTABLE_HIGH" 1 "FLASH_UNCORRECTABLE_LOW" 0 "UNKNOWN" ;
VAL_ 1446 PMR_a064_interventionType 15 "excessiveMotorMz" 14 "inconsistentAxleTorque" 13 "diHeartbeat" 12 "currentAfterIntervention" 11 "switchingAfterIntervention" 10 "switchOffPathTestFail" 9 "inconsistentTorqueSign" 8 "torqueInNeutral" 7 "excessiveRegenTorque" 6 "torqueReversal" 5 "accumulatedTorque" 4 "motorMovementDetected" 3 "cruiseFault" 2 "torqueCmdInvalid" 1 "resolver" 0 "masterTorqueMonitorShutoff" ;
VAL_ 1446 PMR_a064_torqueCmdState 8 "Invalid" 6 "Valid" 0 "SNA" ;
VAL_ 1446 PMR_a064_UI_stoppingMode 2 "HOLD" 1 "CREEP" 0 "STANDARD" ;
VAL_ 1446 PMR_a064_diCrsState 7 "PRE_CANCEL" 6 "PRE_FAULT" 5 "FAULT" 4 "OVERRIDE" 3 "STANDSTILL" 2 "ENABLED" 1 "STANDBY" 0 "UNAVAILABLE" ;
VAL_ 1446 PMR_a064_pmCrsState 7 "PRE_CANCEL" 6 "PRE_FAULT" 5 "FAULT" 4 "OVERRIDE" 3 "STANDSTILL" 2 "ENABLED" 1 "STANDBY" 0 "UNAVAILABLE" ;
VAL_ 1446 PMR_a084_firewallId 17 "HSM_SLV" 16 "R5SS1_CORE1_AHB_MST" 15 "R5SS1_CORE0_AHB_MST" 14 "R5SS0_CORE1_AHB_MST" 13 "R5SS0_CORE0_AHB_MST" 12 "SCRM2SCRP1_SLV" 11 "SCRM2SCRP0_SLV" 10 "QSPI0_SLV" 9 "MBOX_RAM_SLV" 8 "DTHE_SLV" 7 "R5SS1_CORE1_AXIS_SLV" 6 "R5SS1_CORE0_AXIS_SLV" 5 "R5SS0_CORE1_AXIS_SLV" 4 "R5SS0_CORE0_AXIS_SLV" 3 "L2OCRAM_BANK3_SLV" 2 "L2OCRAM_BANK2_SLV" 1 "L2OCRAM_BANK1_SLV" 0 "L2OCRAM_BANK0_SLV" ;
VAL_ 1446 PMR_a084_privId 10 "CPSW" 9 "ICSSM" 7 "R5FSS1_1" 6 "R5FSS1_0" 5 "R5FSS0_1" 4 "R5FSS0_0" 1 "M4FSS0_0" ;
VAL_ 1446 PMR_a084_faultType 6 "SUPER_READ" 5 "SUPER_WRITE" 4 "SUPER_EXE" 3 "USER_READ" 2 "USER_WRITE" 1 "USER_EXE" 0 "NO_FAULT" ;
VAL_ 1446 PMR_a092_pllClockSource 2 "INTOSC1" 1 "XTAL" 0 "INTOSC2" ;
VAL_ 1748 PMR_infoIndex 255 "END" 21 "DI_BUILD_DATA" 20 "UDS_PROTOCOL_BOOTCRC" 19 "VERSION_DEPRECATED" 18 "BOOTLOADER_GITHASH" 17 "APP_GITHASH" 16 "SUBCOMPONENT" 15 "BOOTLOADER_CRC" 14 "BOOTLOADER_SVN" 13 "APP_CRC" 11 "PCBAID_ASSYID_USAGEID" 10 "BUILD_HWID_COMPONENTID" 9 "DEPRECATED_9" 8 "DEPRECATED_8" 7 "DEPRECATED_7" 6 "DEPRECATED_6" 5 "DEPRECATED_5" 4 "DEPRECATED_4" 3 "DEPRECATED_3" 2 "DEPRECATED_2" 1 "DEPRECATED_1" 0 "DEPRECATED_0" ;
VAL_ 1748 PMR_buildType 4 "INFO_MFG_BUILD" 3 "INFO_TRACEABLE_CI_BUILD" 2 "INFO_LOCAL_BUILD" 1 "INFO_PLATFORM_BUILD" 0 "INFO_UNKNOWN_BUILD" ;
VAL_ 1748 PMR_hardwareId 252 "CONFIGURABLE_HWID_PLACEHOLDER" ;
